[part 6 of 12: package /E40_Platform_System_SystemPackage/Components]
AUTOSAR XML (schema 4-2-1)
package /E40_Platform_System_SystemPackage/Components  (continued)
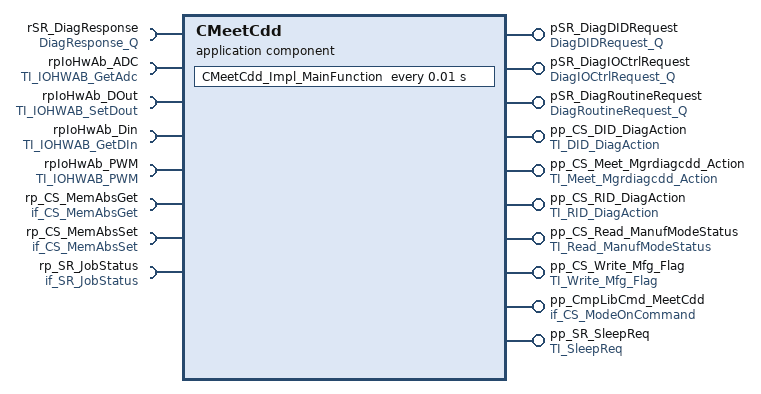
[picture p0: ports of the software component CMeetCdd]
  application sw component type CMeetCdd
    10 x provide port:
      pSR_DiagDIDRequest: queued-sender-com-spec=DiagDIDRequestData, provided-interface=DiagDIDRequest_Q
      pSR_DiagIOCtrlRequest: queued-sender-com-spec=DiagIOCtrlRequestData, provided-interface=DiagIOCtrlRequest_Q
      pSR_DiagRoutineRequest: queued-sender-com-spec=DiagRoutineRequestData, provided-interface=DiagRoutineRequest_Q
      pp_CS_DID_DiagAction: server-com-spec{operation=TI_DID_DiagAction/DID_DiagAction, queue-length=1}, provided-interface=TI_DID_DiagAction
      pp_CS_Meet_Mgrdiagcdd_Action: server-com-spec{operation=Meet_Mgrdiagcdd_Action, queue-length=1}, provided-interface=TI_Meet_Mgrdiagcdd_Action
      pp_CS_RID_DiagAction: server-com-spec{operation=TI_RID_DiagAction/RID_DiagAction, queue-length=1}, provided-interface=TI_RID_DiagAction
      pp_CS_Read_ManufModeStatus: server-com-spec{operation=Read_ManufModeStatus, queue-length=1}, provided-interface=TI_Read_ManufModeStatus
      pp_CS_Write_Mfg_Flag: server-com-spec{operation=Write_Mfg_Flag, queue-length=1}, provided-interface=TI_Write_Mfg_Flag
      pp_CmpLibCmd_MeetCdd: server-com-spec{operation=Impl_OnCommand, queue-length=1}, provided-interface=if_CS_ModeOnCommand
      pp_SR_SleepReq: nonqueued-sender-com-spec{data-element=SleepReqData, uses-end-to-end-protection=0, init-value=constant-reference=CMeetCddSleepReqDataValue0}, provided-interface=TI_SleepReq
    8 x require port:
      rSR_DiagResponse: queued-receiver-com-spec{data-element=DiagResponseData, queue-length=2}, required-interface=DiagResponse_Q
      rpIoHwAb_ADC: required-interface=TI_IOHWAB_GetAdc
      rpIoHwAb_DOut: required-interface=TI_IOHWAB_SetDout
      rpIoHwAb_Din: required-interface=TI_IOHWAB_GetDIn
      rpIoHwAb_PWM: required-interface=TI_IOHWAB_PWM
      rp_CS_MemAbsGet: required-interface=if_CS_MemAbsGet
      rp_CS_MemAbsSet: required-interface=if_CS_MemAbsSet
      rp_SR_JobStatus: required-interface=if_SR_JobStatus
        required-com-specs:
          data-element=JobStatus_BsConst_Audio_Element, init-value=constant-reference=CMeetCddJobStatus_BsConst_Audio_ElementValue0
          data-element=JobStatus_BsConst_BsConst_Illumination_ReservedByte, init-value=constant-reference=CMeetCddJobStatus_BsConst_BsConst_Illumination_ReservedByteValue0
          data-element=JobStatus_BsConst_BsConst_Illumination_ReservedByte_SafeCopy1, init-value=constant-reference=CMeetCddJobStatus_BsConst_BsConst_Illumination_ReservedByte_SafeCopy1Value0
          data-element=JobStatus_BsConst_BsConst_Illumination_ReservedByte_SafeCopy2, init-value=constant-reference=CMeetCddJobStatus_BsConst_BsConst_Illumination_ReservedByte_SafeCopy2Value0
          data-element=JobStatus_BsConst_Communication_Element, init-value=constant-reference=CMeetCddJobStatus_BsConst_Communication_ElementValue0
          data-element=JobStatus_BsConst_Compensation_Line_Shift_b, init-value=constant-reference=CMeetCddJobStatus_BsConst_Compensation_Line_Shift_bValue0
          data-element=JobStatus_BsConst_Compensation_Line_Shift_b_SafeCopy1, init-value=constant-reference=CMeetCddJobStatus_BsConst_Compensation_Line_Shift_b_SafeCopy1Value0
          data-element=JobStatus_BsConst_Compensation_Line_Shift_b_SafeCopy2, init-value=constant-reference=CMeetCddJobStatus_BsConst_Compensation_Line_Shift_b_SafeCopy2Value0
          data-element=JobStatus_BsConst_Compensation_Line_Slope_m, init-value=constant-reference=CMeetCddJobStatus_BsConst_Compensation_Line_Slope_mValue0
          data-element=JobStatus_BsConst_Compensation_Line_Slope_m_SafeCopy1, init-value=constant-reference=CMeetCddJobStatus_BsConst_Compensation_Line_Slope_m_SafeCopy1Value0
          data-element=JobStatus_BsConst_Compensation_Line_Slope_m_SafeCopy2, init-value=constant-reference=CMeetCddJobStatus_BsConst_Compensation_Line_Slope_m_SafeCopy2Value0
          data-element=JobStatus_BsConst_Derating_Backlight_Disable, init-value=constant-reference=CMeetCddJobStatus_BsConst_Derating_Backlight_DisableValue0
          data-element=JobStatus_BsConst_Derating_Backlight_Disable_SafeCopy1, init-value=constant-reference=CMeetCddJobStatus_BsConst_Derating_Backlight_Disable_SafeCopy1Value0
          data-element=JobStatus_BsConst_Derating_Backlight_Disable_SafeCopy2, init-value=constant-reference=CMeetCddJobStatus_BsConst_Derating_Backlight_Disable_SafeCopy2Value0
          data-element=JobStatus_BsConst_Display_Illum_Max_Level, init-value=constant-reference=CMeetCddJobStatus_BsConst_Display_Illum_Max_LevelValue0
          data-element=JobStatus_BsConst_Display_Illum_Max_Level_SafeCopy1, init-value=constant-reference=CMeetCddJobStatus_BsConst_Display_Illum_Max_Level_SafeCopy1Value0
          data-element=JobStatus_BsConst_Display_Illum_Max_Level_SafeCopy2, init-value=constant-reference=CMeetCddJobStatus_BsConst_Display_Illum_Max_Level_SafeCopy2Value0
          data-element=JobStatus_BsConst_EngOffTimer_Element, init-value=constant-reference=CMeetCddJobStatus_BsConst_EngOffTimer_ElementValue0
          data-element=JobStatus_BsConst_FuelGauge_Element, init-value=constant-reference=CMeetCddJobStatus_BsConst_FuelGauge_ElementValue0
          data-element=JobStatus_BsConst_Lookup_Curve_HotSpot_Coef_X, init-value=constant-reference=CMeetCddJobStatus_BsConst_Lookup_Curve_HotSpot_Coef_XValue0
          data-element=JobStatus_BsConst_Lookup_Curve_HotSpot_Coef_X_SafeCopy1, init-value=constant-reference=CMeetCddJobStatus_BsConst_Lookup_Curve_HotSpot_Coef_X_SafeCopy1Value0
          data-element=JobStatus_BsConst_Lookup_Curve_HotSpot_Coef_X_SafeCopy2, init-value=constant-reference=CMeetCddJobStatus_BsConst_Lookup_Curve_HotSpot_Coef_X_SafeCopy2Value0
          data-element=JobStatus_BsConst_Lookup_Curve_HotSpot_Coef_Y, init-value=constant-reference=CMeetCddJobStatus_BsConst_Lookup_Curve_HotSpot_Coef_YValue0
          data-element=JobStatus_BsConst_Lookup_Curve_HotSpot_Coef_Y_SafeCopy1, init-value=constant-reference=CMeetCddJobStatus_BsConst_Lookup_Curve_HotSpot_Coef_Y_SafeCopy1Value0
          data-element=JobStatus_BsConst_Lookup_Curve_HotSpot_Coef_Y_SafeCopy2, init-value=constant-reference=CMeetCddJobStatus_BsConst_Lookup_Curve_HotSpot_Coef_Y_SafeCopy2Value0
          data-element=JobStatus_BsConst_OilGauge_Element, init-value=constant-reference=CMeetCddJobStatus_BsConst_OilGauge_ElementValue0
          data-element=JobStatus_BsConst_PCB_Temperature_Sensor_Conv, init-value=constant-reference=CMeetCddJobStatus_BsConst_PCB_Temperature_Sensor_ConvValue0
          data-element=JobStatus_BsConst_PCB_Temperature_Sensor_Conv_SafeCopy1, init-value=constant-reference=CMeetCddJobStatus_BsConst_PCB_Temperature_Sensor_Conv_SafeCopy1Value0
          data-element=JobStatus_BsConst_PCB_Temperature_Sensor_Conv_SafeCopy2, init-value=constant-reference=CMeetCddJobStatus_BsConst_PCB_Temperature_Sensor_Conv_SafeCopy2Value0
          data-element=JobStatus_BsConst_PWM_boost_bypass_duty, init-value=constant-reference=CMeetCddJobStatus_BsConst_PWM_boost_bypass_dutyValue0
          data-element=JobStatus_BsConst_PWM_boost_bypass_duty_SafeCopy1, init-value=constant-reference=CMeetCddJobStatus_BsConst_PWM_boost_bypass_duty_SafeCopy1Value0
          data-element=JobStatus_BsConst_PWM_boost_bypass_duty_SafeCopy2, init-value=constant-reference=CMeetCddJobStatus_BsConst_PWM_boost_bypass_duty_SafeCopy2Value0
          data-element=JobStatus_BsConst_PowerGauge_Element, init-value=constant-reference=CMeetCddJobStatus_BsConst_PowerGauge_ElementValue0
          data-element=JobStatus_BsConst_Power_Element, init-value=constant-reference=CMeetCddJobStatus_BsConst_Power_ElementValue0
          data-element=JobStatus_BsConst_RealTimeClock_Element, init-value=constant-reference=CMeetCddJobStatus_BsConst_RealTimeClock_ElementValue0
          data-element=JobStatus_BsConst_ServiceReminder_Element, init-value=constant-reference=CMeetCddJobStatus_BsConst_ServiceReminder_ElementValue0
          data-element=JobStatus_BsConst_SpeedoGauge_Element, init-value=constant-reference=CMeetCddJobStatus_BsConst_SpeedoGauge_ElementValue0
          data-element=JobStatus_BsConst_TachoGauge_Element, init-value=constant-reference=CMeetCddJobStatus_BsConst_TachoGauge_ElementValue0
          data-element=JobStatus_BsConst_TempGauge_Element, init-value=constant-reference=CMeetCddJobStatus_BsConst_TempGauge_ElementValue0
          data-element=JobStatus_BsConst_Temp_Threshold_Hysteresis_Derating, init-value=constant-reference=CMeetCddJobStatus_BsConst_Temp_Threshold_Hysteresis_DeratingValue0
          data-element=JobStatus_BsConst_Temp_Threshold_Hysteresis_Derating_SafeCopy1, init-value=constant-reference=CMeetCddJobStatus_BsConst_Temp_Threshold_Hysteresis_Derating_SafeCopy1Value0
          data-element=JobStatus_BsConst_Temp_Threshold_Hysteresis_Derating_SafeCopy2, init-value=constant-reference=CMeetCddJobStatus_BsConst_Temp_Threshold_Hysteresis_Derating_SafeCopy2Value0
          data-element=JobStatus_BsConst_Temperature_Sensor_Conv, init-value=constant-reference=CMeetCddJobStatus_BsConst_Temperature_Sensor_ConvValue0
          data-element=JobStatus_BsConst_Temperature_Sensor_Conv_SafeCopy1, init-value=constant-reference=CMeetCddJobStatus_BsConst_Temperature_Sensor_Conv_SafeCopy1Value0
          data-element=JobStatus_BsConst_Temperature_Sensor_Conv_SafeCopy2, init-value=constant-reference=CMeetCddJobStatus_BsConst_Temperature_Sensor_Conv_SafeCopy2Value0
          data-element=JobStatus_BsConst_TripComputer_Element, init-value=constant-reference=CMeetCddJobStatus_BsConst_TripComputer_ElementValue0
          data-element=JobStatus_BsConst_Warning_Element, init-value=constant-reference=CMeetCddJobStatus_BsConst_Warning_ElementValue0
          data-element=JobStatus_BsCys_Certicificate_Element, init-value=constant-reference=CMeetCddJobStatus_BsCys_Certicificate_ElementValue0
          data-element=JobStatus_BsDiag_Dtc_Element, init-value=constant-reference=CMeetCddJobStatus_BsDiag_Dtc_ElementValue0
          data-element=JobStatus_BsDiag_ErrorRecord_Element, init-value=constant-reference=CMeetCddJobStatus_BsDiag_ErrorRecord_ElementValue0
          data-element=JobStatus_BsReten_Audio_Element, init-value=constant-reference=CMeetCddJobStatus_BsReten_Audio_ElementValue0
          data-element=JobStatus_BsReten_Communication_Element, init-value=constant-reference=CMeetCddJobStatus_BsReten_Communication_ElementValue0
          data-element=JobStatus_BsReten_Display_Element, init-value=constant-reference=CMeetCddJobStatus_BsReten_Display_ElementValue0
          data-element=JobStatus_BsReten_Gauges_Element, init-value=constant-reference=CMeetCddJobStatus_BsReten_Gauges_ElementValue0
          data-element=JobStatus_BsReten_Illumination_Element, init-value=constant-reference=CMeetCddJobStatus_BsReten_Illumination_ElementValue0
          data-element=JobStatus_BsReten_Odometer_Element, init-value=constant-reference=CMeetCddJobStatus_BsReten_Odometer_ElementValue0
          data-element=JobStatus_BsReten_Personalization_Element, init-value=constant-reference=CMeetCddJobStatus_BsReten_Personalization_ElementValue0
          data-element=JobStatus_BsReten_Power_Element, init-value=constant-reference=CMeetCddJobStatus_BsReten_Power_ElementValue0
          data-element=JobStatus_BsReten_RealTimeClock_Element, init-value=constant-reference=CMeetCddJobStatus_BsReten_RealTimeClock_ElementValue0
          data-element=JobStatus_BsReten_Tripcomputer_Element, init-value=constant-reference=CMeetCddJobStatus_BsReten_Tripcomputer_ElementValue0
          data-element=JobStatus_BsReten_Warning_Element, init-value=constant-reference=CMeetCddJobStatus_BsReten_Warning_ElementValue0
          data-element=JobStatus_BsRt_CusDlt_Element, init-value=constant-reference=CMeetCddJobStatus_BsRt_CusDlt_ElementValue0
          data-element=JobStatus_BsRt_FuelGauge_Element, init-value=constant-reference=CMeetCddJobStatus_BsRt_FuelGauge_ElementValue0
          data-element=JobStatus_BsRt_Illumination_Element, init-value=constant-reference=CMeetCddJobStatus_BsRt_Illumination_ElementValue0
          data-element=JobStatus_BsRt_Odometer_Element, init-value=constant-reference=CMeetCddJobStatus_BsRt_Odometer_ElementValue0
          data-element=JobStatus_BsRt_OilGauge_Element, init-value=constant-reference=CMeetCddJobStatus_BsRt_OilGauge_ElementValue0
          data-element=JobStatus_BsRt_Personalization_Element, init-value=constant-reference=CMeetCddJobStatus_BsRt_Personalization_ElementValue0
          data-element=JobStatus_BsRt_PowerGauge_Element, init-value=constant-reference=CMeetCddJobStatus_BsRt_PowerGauge_ElementValue0
          data-element=JobStatus_BsRt_RealTimeClock_Element, init-value=constant-reference=CMeetCddJobStatus_BsRt_RealTimeClock_ElementValue0
          data-element=JobStatus_BsRt_SpeedoGauge_Element, init-value=constant-reference=CMeetCddJobStatus_BsRt_SpeedoGauge_ElementValue0
          data-element=JobStatus_BsRt_TachoGauge_Element, init-value=constant-reference=CMeetCddJobStatus_BsRt_TachoGauge_ElementValue0
          data-element=JobStatus_BsRt_TempGauge_Element, init-value=constant-reference=CMeetCddJobStatus_BsRt_TempGauge_ElementValue0
          data-element=JobStatus_BsRt_TripComputer_Element, init-value=constant-reference=CMeetCddJobStatus_BsRt_TripComputer_ElementValue0
          data-element=JobStatus_BsRt_Warning_Element, init-value=constant-reference=CMeetCddJobStatus_BsRt_Warning_ElementValue0
          data-element=JobStatus_BsShare_AssemblyManufacturingDate, init-value=constant-reference=CMeetCddJobStatus_BsShare_AssemblyManufacturingDateValue0
          data-element=JobStatus_BsShare_AssemblyPlantNumber, init-value=constant-reference=CMeetCddJobStatus_BsShare_AssemblyPlantNumberValue0
          data-element=JobStatus_BsShare_EcuPartNumber_Element, init-value=constant-reference=CMeetCddJobStatus_BsShare_EcuPartNumber_ElementValue0
          data-element=JobStatus_BsShare_HWModification, init-value=constant-reference=CMeetCddJobStatus_BsShare_HWModificationValue0
          data-element=JobStatus_BsShare_PCBSerialNumber, init-value=constant-reference=CMeetCddJobStatus_BsShare_PCBSerialNumberValue0
          data-element=JobStatus_BsShare_ProductSerialNumber, init-value=constant-reference=CMeetCddJobStatus_BsShare_ProductSerialNumberValue0
          data-element=JobStatus_BsShare_SMTManufacturingDate, init-value=constant-reference=CMeetCddJobStatus_BsShare_SMTManufacturingDateValue0
          data-element=JobStatus_BsShare_SMTPlantNumber, init-value=constant-reference=CMeetCddJobStatus_BsShare_SMTPlantNumberValue0
          data-element=JobStatus_BsShare_SwUpdFotaFinPrint_Element, init-value=constant-reference=CMeetCddJobStatus_BsShare_SwUpdFotaFinPrint_ElementValue0
          data-element=JobStatus_BsShare_SwUpdFotaMode_Element, init-value=constant-reference=CMeetCddJobStatus_BsShare_SwUpdFotaMode_ElementValue0
          data-element=JobStatus_BsShare_SwUpdFotaStatus_Element, init-value=constant-reference=CMeetCddJobStatus_BsShare_SwUpdFotaStatus_ElementValue0
          data-element=JobStatus_BsShare_SwUpdFotadecrypt_Element, init-value=constant-reference=CMeetCddJobStatus_BsShare_SwUpdFotadecrypt_ElementValue0
          data-element=JobStatus_BsShare_SwUpdReflash_Element, init-value=constant-reference=CMeetCddJobStatus_BsShare_SwUpdReflash_ElementValue0
          data-element=JobStatus_BsShare_VehicleConfig_Element, init-value=constant-reference=CMeetCddJobStatus_BsShare_VehicleConfig_ElementValue0
          data-element=JobStatus_BsShare_VisMeet_EOLEntry_Element, init-value=constant-reference=CMeetCddJobStatus_BsShare_VisMeet_EOLEntry_ElementValue0
          data-element=JobStatus_BsShare_VisMeet_Element, init-value=constant-reference=CMeetCddJobStatus_BsShare_VisMeet_ElementValue0
          data-element=JobStatus_BsShare_VisteonPCBPartNumber, init-value=constant-reference=CMeetCddJobStatus_BsShare_VisteonPCBPartNumberValue0
          data-element=JobStatus_BsShare_VisteonPartNumber, init-value=constant-reference=CMeetCddJobStatus_BsShare_VisteonPartNumberValue0
          data-element=JobStatus_RefCys_Certicificate1_Element, init-value=constant-reference=CMeetCddJobStatus_RefCys_Certicificate1_ElementValue0
          data-element=JobStatus_RefCys_Certicificate_Element, init-value=constant-reference=CMeetCddJobStatus_RefCys_Certicificate_ElementValue0
    behavior IB_CMeetCdd
      operation invoked event OIE_pp_CS_DID_DiagAction_CMeetCdd_DID_DiagActionTrigByDID_DiagAction: start-on-event=CMeetCdd_DID_DiagAction, operation=pp_CS_DID_DiagAction.DID_DiagAction
      timing event TECMeetCdd_Impl_MainFunction: start-on-event=CMeetCdd_Impl_MainFunction, period=0.01
      5 x operation invoked event:
        OIE_pp_CmpLibCmd_MeetCdd_CMeetCdd_Impl_OnCommandTrigByImpl_OnCommand: start-on-event=CMeetCdd_Impl_OnCommand, operation=pp_CmpLibCmd_MeetCdd.Impl_OnCommand
        OIE_pp_CS_Meet_Mgrdiagcdd_Action_CMeetCdd_Meet_Mgrdiagcdd_ActionTrigByMeet_Mgrdiagcdd_Action: start-on-event=CMeetCdd_Meet_Mgrdiagcdd_Action, operation=pp_CS_Meet_Mgrdiagcdd_Action.Meet_Mgrdiagcdd_Action
        OIE_pp_CS_RID_DiagAction_CMeetCdd_RID_DiagActionTrigByRID_DiagAction: start-on-event=CMeetCdd_RID_DiagAction, operation=pp_CS_RID_DiagAction.RID_DiagAction
        OIE_pp_CS_Read_ManufModeStatus_CMeetCdd_Read_ManufModeStatusTrigByRead_ManufModeStatus: start-on-event=CMeetCdd_Read_ManufModeStatus, operation=pp_CS_Read_ManufModeStatus.Read_ManufModeStatus
        OIE_pp_CS_Write_Mfg_Flag_CMeetCdd_Write_Mfg_FlagTrigByWrite_Mfg_Flag: start-on-event=CMeetCdd_Write_Mfg_Flag, operation=pp_CS_Write_Mfg_Flag.Write_Mfg_Flag
      port-api-options:
        enable-take-address=false, indirect-api=false, port=pSR_DiagDIDRequest
        enable-take-address=false, indirect-api=false, port=pSR_DiagIOCtrlRequest
        enable-take-address=false, indirect-api=false, port=pSR_DiagRoutineRequest
        enable-take-address=false, indirect-api=false, port=pp_CS_DID_DiagAction
        enable-take-address=false, indirect-api=false, port=pp_CS_Meet_Mgrdiagcdd_Action
        enable-take-address=false, indirect-api=false, port=pp_CS_RID_DiagAction
        enable-take-address=false, indirect-api=false, port=pp_CS_Read_ManufModeStatus
        enable-take-address=false, indirect-api=false, port=pp_CS_Write_Mfg_Flag
        enable-take-address=false, indirect-api=false, port=pp_CmpLibCmd_MeetCdd
        enable-take-address=false, indirect-api=false, port=pp_SR_SleepReq
        enable-take-address=false, indirect-api=false, port=rSR_DiagResponse
        enable-take-address=false, indirect-api=false, port=CMeetCdd/rpIoHwAb_ADC
        enable-take-address=false, indirect-api=false, port=CMeetCdd/rpIoHwAb_DOut
        enable-take-address=false, indirect-api=false, port=CMeetCdd/rpIoHwAb_Din
        enable-take-address=false, indirect-api=false, port=CMeetCdd/rpIoHwAb_PWM
        enable-take-address=false, indirect-api=false, port=CMeetCdd/rp_CS_MemAbsGet
        enable-take-address=false, indirect-api=false, port=CMeetCdd/rp_CS_MemAbsSet
        enable-take-address=false, indirect-api=false, port=CMeetCdd/rp_SR_JobStatus
      7 x runnable, all with can-be-invoked-concurrently=true:
        CMeetCdd_DID_DiagAction
        CMeetCdd_Impl_MainFunction
          data-receive-point-by-arguments:
            95 x access:
              DRP_rSR_DiagResponse_DiagResponseData: accessed-variable=rSR_DiagResponse.DiagResponseData
              DRA_rp_SR_JobStatus_JobStatus_BsConst_Audio_Element: accessed-variable=rp_SR_JobStatus.JobStatus_BsConst_Audio_Element
              DRA_rp_SR_JobStatus_JobStatus_BsConst_BsConst_Illumination_ReservedByte: accessed-variable=rp_SR_JobStatus.JobStatus_BsConst_BsConst_Illumination_ReservedByte
              DRA_rp_SR_JobStatus_JobStatus_BsConst_BsConst_Illumination_ReservedByte_SafeCopy1: accessed-variable=rp_SR_JobStatus.JobStatus_BsConst_BsConst_Illumination_ReservedByte_SafeCopy1
              DRA_rp_SR_JobStatus_JobStatus_BsConst_BsConst_Illumination_ReservedByte_SafeCopy2: accessed-variable=rp_SR_JobStatus.JobStatus_BsConst_BsConst_Illumination_ReservedByte_SafeCopy2
              DRA_rp_SR_JobStatus_JobStatus_BsConst_Communication_Element: accessed-variable=rp_SR_JobStatus.JobStatus_BsConst_Communication_Element
              DRA_rp_SR_JobStatus_JobStatus_BsConst_Compensation_Line_Shift_b: accessed-variable=rp_SR_JobStatus.JobStatus_BsConst_Compensation_Line_Shift_b
              DRA_rp_SR_JobStatus_JobStatus_BsConst_Compensation_Line_Shift_b_SafeCopy1: accessed-variable=rp_SR_JobStatus.JobStatus_BsConst_Compensation_Line_Shift_b_SafeCopy1
              DRA_rp_SR_JobStatus_JobStatus_BsConst_Compensation_Line_Shift_b_SafeCopy2: accessed-variable=rp_SR_JobStatus.JobStatus_BsConst_Compensation_Line_Shift_b_SafeCopy2
              DRA_rp_SR_JobStatus_JobStatus_BsConst_Compensation_Line_Slope_m: accessed-variable=rp_SR_JobStatus.JobStatus_BsConst_Compensation_Line_Slope_m
              DRA_rp_SR_JobStatus_JobStatus_BsConst_Compensation_Line_Slope_m_SafeCopy1: accessed-variable=rp_SR_JobStatus.JobStatus_BsConst_Compensation_Line_Slope_m_SafeCopy1
              DRA_rp_SR_JobStatus_JobStatus_BsConst_Compensation_Line_Slope_m_SafeCopy2: accessed-variable=rp_SR_JobStatus.JobStatus_BsConst_Compensation_Line_Slope_m_SafeCopy2
              DRA_rp_SR_JobStatus_JobStatus_BsConst_Derating_Backlight_Disable: accessed-variable=rp_SR_JobStatus.JobStatus_BsConst_Derating_Backlight_Disable
              DRA_rp_SR_JobStatus_JobStatus_BsConst_Derating_Backlight_Disable_SafeCopy1: accessed-variable=rp_SR_JobStatus.JobStatus_BsConst_Derating_Backlight_Disable_SafeCopy1
              DRA_rp_SR_JobStatus_JobStatus_BsConst_Derating_Backlight_Disable_SafeCopy2: accessed-variable=rp_SR_JobStatus.JobStatus_BsConst_Derating_Backlight_Disable_SafeCopy2
              DRA_rp_SR_JobStatus_JobStatus_BsConst_Display_Illum_Max_Level: accessed-variable=rp_SR_JobStatus.JobStatus_BsConst_Display_Illum_Max_Level
              DRA_rp_SR_JobStatus_JobStatus_BsConst_Display_Illum_Max_Level_SafeCopy1: accessed-variable=rp_SR_JobStatus.JobStatus_BsConst_Display_Illum_Max_Level_SafeCopy1
              DRA_rp_SR_JobStatus_JobStatus_BsConst_Display_Illum_Max_Level_SafeCopy2: accessed-variable=rp_SR_JobStatus.JobStatus_BsConst_Display_Illum_Max_Level_SafeCopy2
              DRA_rp_SR_JobStatus_JobStatus_BsConst_EngOffTimer_Element: accessed-variable=rp_SR_JobStatus.JobStatus_BsConst_EngOffTimer_Element
              DRA_rp_SR_JobStatus_JobStatus_BsConst_FuelGauge_Element: accessed-variable=rp_SR_JobStatus.JobStatus_BsConst_FuelGauge_Element
              DRA_rp_SR_JobStatus_JobStatus_BsConst_Lookup_Curve_HotSpot_Coef_X: accessed-variable=rp_SR_JobStatus.JobStatus_BsConst_Lookup_Curve_HotSpot_Coef_X
              DRA_rp_SR_JobStatus_JobStatus_BsConst_Lookup_Curve_HotSpot_Coef_X_SafeCopy1: accessed-variable=rp_SR_JobStatus.JobStatus_BsConst_Lookup_Curve_HotSpot_Coef_X_SafeCopy1
              DRA_rp_SR_JobStatus_JobStatus_BsConst_Lookup_Curve_HotSpot_Coef_X_SafeCopy2: accessed-variable=rp_SR_JobStatus.JobStatus_BsConst_Lookup_Curve_HotSpot_Coef_X_SafeCopy2
              DRA_rp_SR_JobStatus_JobStatus_BsConst_Lookup_Curve_HotSpot_Coef_Y: accessed-variable=rp_SR_JobStatus.JobStatus_BsConst_Lookup_Curve_HotSpot_Coef_Y
              DRA_rp_SR_JobStatus_JobStatus_BsConst_Lookup_Curve_HotSpot_Coef_Y_SafeCopy1: accessed-variable=rp_SR_JobStatus.JobStatus_BsConst_Lookup_Curve_HotSpot_Coef_Y_SafeCopy1
              DRA_rp_SR_JobStatus_JobStatus_BsConst_Lookup_Curve_HotSpot_Coef_Y_SafeCopy2: accessed-variable=rp_SR_JobStatus.JobStatus_BsConst_Lookup_Curve_HotSpot_Coef_Y_SafeCopy2
              DRA_rp_SR_JobStatus_JobStatus_BsConst_OilGauge_Element: accessed-variable=rp_SR_JobStatus.JobStatus_BsConst_OilGauge_Element
              DRA_rp_SR_JobStatus_JobStatus_BsConst_PCB_Temperature_Sensor_Conv: accessed-variable=rp_SR_JobStatus.JobStatus_BsConst_PCB_Temperature_Sensor_Conv
              DRA_rp_SR_JobStatus_JobStatus_BsConst_PCB_Temperature_Sensor_Conv_SafeCopy1: accessed-variable=rp_SR_JobStatus.JobStatus_BsConst_PCB_Temperature_Sensor_Conv_SafeCopy1
              DRA_rp_SR_JobStatus_JobStatus_BsConst_PCB_Temperature_Sensor_Conv_SafeCopy2: accessed-variable=rp_SR_JobStatus.JobStatus_BsConst_PCB_Temperature_Sensor_Conv_SafeCopy2
              DRA_rp_SR_JobStatus_JobStatus_BsConst_PWM_boost_bypass_duty: accessed-variable=rp_SR_JobStatus.JobStatus_BsConst_PWM_boost_bypass_duty
              DRA_rp_SR_JobStatus_JobStatus_BsConst_PWM_boost_bypass_duty_SafeCopy1: accessed-variable=rp_SR_JobStatus.JobStatus_BsConst_PWM_boost_bypass_duty_SafeCopy1
              DRA_rp_SR_JobStatus_JobStatus_BsConst_PWM_boost_bypass_duty_SafeCopy2: accessed-variable=rp_SR_JobStatus.JobStatus_BsConst_PWM_boost_bypass_duty_SafeCopy2
              DRA_rp_SR_JobStatus_JobStatus_BsConst_PowerGauge_Element: accessed-variable=rp_SR_JobStatus.JobStatus_BsConst_PowerGauge_Element
              DRA_rp_SR_JobStatus_JobStatus_BsConst_Power_Element: accessed-variable=rp_SR_JobStatus.JobStatus_BsConst_Power_Element
              DRA_rp_SR_JobStatus_JobStatus_BsConst_RealTimeClock_Element: accessed-variable=rp_SR_JobStatus.JobStatus_BsConst_RealTimeClock_Element
              DRA_rp_SR_JobStatus_JobStatus_BsConst_ServiceReminder_Element: accessed-variable=rp_SR_JobStatus.JobStatus_BsConst_ServiceReminder_Element
              DRA_rp_SR_JobStatus_JobStatus_BsConst_SpeedoGauge_Element: accessed-variable=rp_SR_JobStatus.JobStatus_BsConst_SpeedoGauge_Element
              DRA_rp_SR_JobStatus_JobStatus_BsConst_TachoGauge_Element: accessed-variable=rp_SR_JobStatus.JobStatus_BsConst_TachoGauge_Element
              DRA_rp_SR_JobStatus_JobStatus_BsConst_TempGauge_Element: accessed-variable=rp_SR_JobStatus.JobStatus_BsConst_TempGauge_Element
              DRA_rp_SR_JobStatus_JobStatus_BsConst_Temp_Threshold_Hysteresis_Derating: accessed-variable=rp_SR_JobStatus.JobStatus_BsConst_Temp_Threshold_Hysteresis_Derating
              DRA_rp_SR_JobStatus_JobStatus_BsConst_Temp_Threshold_Hysteresis_Derating_SafeCopy1: accessed-variable=rp_SR_JobStatus.JobStatus_BsConst_Temp_Threshold_Hysteresis_Derating_SafeCopy1
              DRA_rp_SR_JobStatus_JobStatus_BsConst_Temp_Threshold_Hysteresis_Derating_SafeCopy2: accessed-variable=rp_SR_JobStatus.JobStatus_BsConst_Temp_Threshold_Hysteresis_Derating_SafeCopy2
              DRA_rp_SR_JobStatus_JobStatus_BsConst_Temperature_Sensor_Conv: accessed-variable=rp_SR_JobStatus.JobStatus_BsConst_Temperature_Sensor_Conv
              DRA_rp_SR_JobStatus_JobStatus_BsConst_Temperature_Sensor_Conv_SafeCopy1: accessed-variable=rp_SR_JobStatus.JobStatus_BsConst_Temperature_Sensor_Conv_SafeCopy1
              DRA_rp_SR_JobStatus_JobStatus_BsConst_Temperature_Sensor_Conv_SafeCopy2: accessed-variable=rp_SR_JobStatus.JobStatus_BsConst_Temperature_Sensor_Conv_SafeCopy2
              DRA_rp_SR_JobStatus_JobStatus_BsConst_TripComputer_Element: accessed-variable=rp_SR_JobStatus.JobStatus_BsConst_TripComputer_Element
              DRA_rp_SR_JobStatus_JobStatus_BsConst_Warning_Element: accessed-variable=rp_SR_JobStatus.JobStatus_BsConst_Warning_Element
              DRA_rp_SR_JobStatus_JobStatus_BsCys_Certicificate_Element: accessed-variable=rp_SR_JobStatus.JobStatus_BsCys_Certicificate_Element
              DRA_rp_SR_JobStatus_JobStatus_BsDiag_Dtc_Element: accessed-variable=rp_SR_JobStatus.JobStatus_BsDiag_Dtc_Element
              DRA_rp_SR_JobStatus_JobStatus_BsDiag_ErrorRecord_Element: accessed-variable=rp_SR_JobStatus.JobStatus_BsDiag_ErrorRecord_Element
              DRA_rp_SR_JobStatus_JobStatus_BsReten_Audio_Element: accessed-variable=rp_SR_JobStatus.JobStatus_BsReten_Audio_Element
              DRA_rp_SR_JobStatus_JobStatus_BsReten_Communication_Element: accessed-variable=rp_SR_JobStatus.JobStatus_BsReten_Communication_Element
              DRA_rp_SR_JobStatus_JobStatus_BsReten_Display_Element: accessed-variable=rp_SR_JobStatus.JobStatus_BsReten_Display_Element
              DRA_rp_SR_JobStatus_JobStatus_BsReten_Gauges_Element: accessed-variable=rp_SR_JobStatus.JobStatus_BsReten_Gauges_Element
              DRA_rp_SR_JobStatus_JobStatus_BsReten_Illumination_Element: accessed-variable=rp_SR_JobStatus.JobStatus_BsReten_Illumination_Element
              DRA_rp_SR_JobStatus_JobStatus_BsReten_Odometer_Element: accessed-variable=rp_SR_JobStatus.JobStatus_BsReten_Odometer_Element
              DRA_rp_SR_JobStatus_JobStatus_BsReten_Personalization_Element: accessed-variable=rp_SR_JobStatus.JobStatus_BsReten_Personalization_Element
              DRA_rp_SR_JobStatus_JobStatus_BsReten_Power_Element: accessed-variable=rp_SR_JobStatus.JobStatus_BsReten_Power_Element
              DRA_rp_SR_JobStatus_JobStatus_BsReten_RealTimeClock_Element: accessed-variable=rp_SR_JobStatus.JobStatus_BsReten_RealTimeClock_Element
              DRA_rp_SR_JobStatus_JobStatus_BsReten_Tripcomputer_Element: accessed-variable=rp_SR_JobStatus.JobStatus_BsReten_Tripcomputer_Element
              DRA_rp_SR_JobStatus_JobStatus_BsReten_Warning_Element: accessed-variable=rp_SR_JobStatus.JobStatus_BsReten_Warning_Element
              DRA_rp_SR_JobStatus_JobStatus_BsRt_CusDlt_Element: accessed-variable=rp_SR_JobStatus.JobStatus_BsRt_CusDlt_Element
              DRA_rp_SR_JobStatus_JobStatus_BsRt_FuelGauge_Element: accessed-variable=rp_SR_JobStatus.JobStatus_BsRt_FuelGauge_Element
              DRA_rp_SR_JobStatus_JobStatus_BsRt_Illumination_Element: accessed-variable=rp_SR_JobStatus.JobStatus_BsRt_Illumination_Element
              DRA_rp_SR_JobStatus_JobStatus_BsRt_Odometer_Element: accessed-variable=rp_SR_JobStatus.JobStatus_BsRt_Odometer_Element
              DRA_rp_SR_JobStatus_JobStatus_BsRt_OilGauge_Element: accessed-variable=rp_SR_JobStatus.JobStatus_BsRt_OilGauge_Element
              DRA_rp_SR_JobStatus_JobStatus_BsRt_Personalization_Element: accessed-variable=rp_SR_JobStatus.JobStatus_BsRt_Personalization_Element
              DRA_rp_SR_JobStatus_JobStatus_BsRt_PowerGauge_Element: accessed-variable=rp_SR_JobStatus.JobStatus_BsRt_PowerGauge_Element
              DRA_rp_SR_JobStatus_JobStatus_BsRt_RealTimeClock_Element: accessed-variable=rp_SR_JobStatus.JobStatus_BsRt_RealTimeClock_Element
              DRA_rp_SR_JobStatus_JobStatus_BsRt_SpeedoGauge_Element: accessed-variable=rp_SR_JobStatus.JobStatus_BsRt_SpeedoGauge_Element
              DRA_rp_SR_JobStatus_JobStatus_BsRt_TachoGauge_Element: accessed-variable=rp_SR_JobStatus.JobStatus_BsRt_TachoGauge_Element
              DRA_rp_SR_JobStatus_JobStatus_BsRt_TempGauge_Element: accessed-variable=rp_SR_JobStatus.JobStatus_BsRt_TempGauge_Element
              DRA_rp_SR_JobStatus_JobStatus_BsRt_TripComputer_Element: accessed-variable=rp_SR_JobStatus.JobStatus_BsRt_TripComputer_Element
              DRA_rp_SR_JobStatus_JobStatus_BsRt_Warning_Element: accessed-variable=rp_SR_JobStatus.JobStatus_BsRt_Warning_Element
              DRA_rp_SR_JobStatus_JobStatus_BsShare_AssemblyManufacturingDate: accessed-variable=rp_SR_JobStatus.JobStatus_BsShare_AssemblyManufacturingDate
              DRA_rp_SR_JobStatus_JobStatus_BsShare_AssemblyPlantNumber: accessed-variable=rp_SR_JobStatus.JobStatus_BsShare_AssemblyPlantNumber
              DRA_rp_SR_JobStatus_JobStatus_BsShare_EcuPartNumber_Element: accessed-variable=rp_SR_JobStatus.JobStatus_BsShare_EcuPartNumber_Element
              DRA_rp_SR_JobStatus_JobStatus_BsShare_HWModification: accessed-variable=rp_SR_JobStatus.JobStatus_BsShare_HWModification
              DRA_rp_SR_JobStatus_JobStatus_BsShare_PCBSerialNumber: accessed-variable=rp_SR_JobStatus.JobStatus_BsShare_PCBSerialNumber
              DRA_rp_SR_JobStatus_JobStatus_BsShare_ProductSerialNumber: accessed-variable=rp_SR_JobStatus.JobStatus_BsShare_ProductSerialNumber
              DRA_rp_SR_JobStatus_JobStatus_BsShare_SMTManufacturingDate: accessed-variable=rp_SR_JobStatus.JobStatus_BsShare_SMTManufacturingDate
              DRA_rp_SR_JobStatus_JobStatus_BsShare_SMTPlantNumber: accessed-variable=rp_SR_JobStatus.JobStatus_BsShare_SMTPlantNumber
              DRA_rp_SR_JobStatus_JobStatus_BsShare_SwUpdFotaFinPrint_Element: accessed-variable=rp_SR_JobStatus.JobStatus_BsShare_SwUpdFotaFinPrint_Element
              DRA_rp_SR_JobStatus_JobStatus_BsShare_SwUpdFotaMode_Element: accessed-variable=rp_SR_JobStatus.JobStatus_BsShare_SwUpdFotaMode_Element
              DRA_rp_SR_JobStatus_JobStatus_BsShare_SwUpdFotaStatus_Element: accessed-variable=rp_SR_JobStatus.JobStatus_BsShare_SwUpdFotaStatus_Element
              DRA_rp_SR_JobStatus_JobStatus_BsShare_SwUpdFotadecrypt_Element: accessed-variable=rp_SR_JobStatus.JobStatus_BsShare_SwUpdFotadecrypt_Element
              DRA_rp_SR_JobStatus_JobStatus_BsShare_SwUpdReflash_Element: accessed-variable=rp_SR_JobStatus.JobStatus_BsShare_SwUpdReflash_Element
              DRA_rp_SR_JobStatus_JobStatus_BsShare_VehicleConfig_Element: accessed-variable=rp_SR_JobStatus.JobStatus_BsShare_VehicleConfig_Element
              DRA_rp_SR_JobStatus_JobStatus_BsShare_VisMeet_EOLEntry_Element: accessed-variable=rp_SR_JobStatus.JobStatus_BsShare_VisMeet_EOLEntry_Element
              DRA_rp_SR_JobStatus_JobStatus_BsShare_VisMeet_Element: accessed-variable=rp_SR_JobStatus.JobStatus_BsShare_VisMeet_Element
              DRA_rp_SR_JobStatus_JobStatus_BsShare_VisteonPCBPartNumber: accessed-variable=rp_SR_JobStatus.JobStatus_BsShare_VisteonPCBPartNumber
              DRA_rp_SR_JobStatus_JobStatus_BsShare_VisteonPartNumber: accessed-variable=rp_SR_JobStatus.JobStatus_BsShare_VisteonPartNumber
              DRA_rp_SR_JobStatus_JobStatus_RefCys_Certicificate1_Element: accessed-variable=rp_SR_JobStatus.JobStatus_RefCys_Certicificate1_Element
              DRA_rp_SR_JobStatus_JobStatus_RefCys_Certicificate_Element: accessed-variable=rp_SR_JobStatus.JobStatus_RefCys_Certicificate_Element
          data-send-points:
            4 x access:
              DSP_pSR_DiagDIDRequest_DiagDIDRequestData: accessed-variable=pSR_DiagDIDRequest.DiagDIDRequestData
              DSP_pSR_DiagIOCtrlRequest_DiagIOCtrlRequestData: accessed-variable=pSR_DiagIOCtrlRequest.DiagIOCtrlRequestData
              DSP_pSR_DiagRoutineRequest_DiagRoutineRequestData: accessed-variable=pSR_DiagRoutineRequest.DiagRoutineRequestData
              DWA_pp_SR_SleepReq_SleepReqData: accessed-variable=pp_SR_SleepReq.SleepReqData
          200 x sync call, all with timeout=0.0:
            OA_rpIoHwAb_ADC_GetAsyncRawAdc: operation=rpIoHwAb_ADC.GetAsyncRawAdc
            OA_rpIoHwAb_ADC_GetSyncRawAdc: operation=rpIoHwAb_ADC.GetSyncRawAdc
            OA_rpIoHwAb_ADC_GetProcessedAdc: operation=rpIoHwAb_ADC.GetProcessedAdc
            OA_rpIoHwAb_DOut_SetOutputGroup: operation=rpIoHwAb_DOut.SetOutputGroup
            OA_rpIoHwAb_DOut_SetOutputPin: operation=rpIoHwAb_DOut.SetOutputPin
            OA_rpIoHwAb_Din_GetAsyncRawInput: operation=rpIoHwAb_Din.GetAsyncRawInput
            OA_rpIoHwAb_Din_GetProcessedInput: operation=rpIoHwAb_Din.GetProcessedInput
            OA_rpIoHwAb_Din_GetSyncRawInput: operation=rpIoHwAb_Din.GetSyncRawInput
            OA_rpIoHwAb_Din_GetInputGroup: operation=rpIoHwAb_Din.GetInputGroup
            OA_rpIoHwAb_PWM_PwmSetDuty: operation=rpIoHwAb_PWM.PwmSetDuty
            OA_rpIoHwAb_PWM_PwmSetDutyAndPeriod: operation=rpIoHwAb_PWM.PwmSetDutyAndPeriod
            OA_rpIoHwAb_PWM_PwmSetIdeal: operation=rpIoHwAb_PWM.PwmSetIdeal
            OA_rp_CS_MemAbsGet_Get_BsShare_SwUpdReflash_Element: operation=rp_CS_MemAbsGet.Get_BsShare_SwUpdReflash_Element
            OA_rp_CS_MemAbsGet_Get_BsShare_SwUpdFotaMode_Element: operation=rp_CS_MemAbsGet.Get_BsShare_SwUpdFotaMode_Element
            OA_rp_CS_MemAbsGet_Get_BsShare_SwUpdFotaFinPrint_Element: operation=rp_CS_MemAbsGet.Get_BsShare_SwUpdFotaFinPrint_Element
            OA_rp_CS_MemAbsGet_Get_BsShare_SwUpdFotaStatus_Element: operation=rp_CS_MemAbsGet.Get_BsShare_SwUpdFotaStatus_Element
            OA_rp_CS_MemAbsGet_Get_BsShare_SwUpdFotadecrypt_Element: operation=rp_CS_MemAbsGet.Get_BsShare_SwUpdFotadecrypt_Element
            OA_rp_CS_MemAbsGet_Get_BsShare_EcuPartNumber_Element: operation=rp_CS_MemAbsGet.Get_BsShare_EcuPartNumber_Element
            OA_rp_CS_MemAbsGet_Get_BsShare_VisteonPartNumber: operation=rp_CS_MemAbsGet.Get_BsShare_VisteonPartNumber
            OA_rp_CS_MemAbsGet_Get_BsShare_VisteonPCBPartNumber: operation=rp_CS_MemAbsGet.Get_BsShare_VisteonPCBPartNumber
            OA_rp_CS_MemAbsGet_Get_BsShare_ProductSerialNumber: operation=rp_CS_MemAbsGet.Get_BsShare_ProductSerialNumber
            OA_rp_CS_MemAbsGet_Get_BsShare_PCBSerialNumber: operation=rp_CS_MemAbsGet.Get_BsShare_PCBSerialNumber
            OA_rp_CS_MemAbsGet_Get_BsShare_SMTManufacturingDate: operation=rp_CS_MemAbsGet.Get_BsShare_SMTManufacturingDate
            OA_rp_CS_MemAbsGet_Get_BsShare_AssemblyManufacturingDate: operation=rp_CS_MemAbsGet.Get_BsShare_AssemblyManufacturingDate
            OA_rp_CS_MemAbsGet_Get_BsShare_SMTPlantNumber: operation=rp_CS_MemAbsGet.Get_BsShare_SMTPlantNumber
            OA_rp_CS_MemAbsGet_Get_BsShare_AssemblyPlantNumber: operation=rp_CS_MemAbsGet.Get_BsShare_AssemblyPlantNumber
            OA_rp_CS_MemAbsGet_Get_BsShare_HWModification: operation=rp_CS_MemAbsGet.Get_BsShare_HWModification
            OA_rp_CS_MemAbsGet_Get_BsShare_VisMeet_Element: operation=rp_CS_MemAbsGet.Get_BsShare_VisMeet_Element
            OA_rp_CS_MemAbsGet_Get_BsShare_VisMeet_EOLEntry_Element: operation=rp_CS_MemAbsGet.Get_BsShare_VisMeet_EOLEntry_Element
            OA_rp_CS_MemAbsGet_Get_BsShare_VehicleConfig_Element: operation=rp_CS_MemAbsGet.Get_BsShare_VehicleConfig_Element
            OA_rp_CS_MemAbsGet_Get_BsConst_SpeedoGauge_Element: operation=rp_CS_MemAbsGet.Get_BsConst_SpeedoGauge_Element
            OA_rp_CS_MemAbsGet_Get_BsConst_TachoGauge_Element: operation=rp_CS_MemAbsGet.Get_BsConst_TachoGauge_Element
            OA_rp_CS_MemAbsGet_Get_BsConst_FuelGauge_Element: operation=rp_CS_MemAbsGet.Get_BsConst_FuelGauge_Element
            OA_rp_CS_MemAbsGet_Get_BsConst_TempGauge_Element: operation=rp_CS_MemAbsGet.Get_BsConst_TempGauge_Element
            OA_rp_CS_MemAbsGet_Get_BsConst_PowerGauge_Element: operation=rp_CS_MemAbsGet.Get_BsConst_PowerGauge_Element
            OA_rp_CS_MemAbsGet_Get_BsConst_OilGauge_Element: operation=rp_CS_MemAbsGet.Get_BsConst_OilGauge_Element
            OA_rp_CS_MemAbsGet_Get_BsConst_TripComputer_Element: operation=rp_CS_MemAbsGet.Get_BsConst_TripComputer_Element
            OA_rp_CS_MemAbsGet_Get_BsConst_Compensation_Line_Slope_m: operation=rp_CS_MemAbsGet.Get_BsConst_Compensation_Line_Slope_m
            OA_rp_CS_MemAbsGet_Get_BsConst_Compensation_Line_Shift_b: operation=rp_CS_MemAbsGet.Get_BsConst_Compensation_Line_Shift_b
            OA_rp_CS_MemAbsGet_Get_BsConst_Lookup_Curve_HotSpot_Coef_X: operation=rp_CS_MemAbsGet.Get_BsConst_Lookup_Curve_HotSpot_Coef_X
            OA_rp_CS_MemAbsGet_Get_BsConst_Lookup_Curve_HotSpot_Coef_Y: operation=rp_CS_MemAbsGet.Get_BsConst_Lookup_Curve_HotSpot_Coef_Y
            OA_rp_CS_MemAbsGet_Get_BsConst_Temp_Threshold_Hysteresis_Derating: operation=rp_CS_MemAbsGet.Get_BsConst_Temp_Threshold_Hysteresis_Derating
            OA_rp_CS_MemAbsGet_Get_BsConst_Derating_Backlight_Disable: operation=rp_CS_MemAbsGet.Get_BsConst_Derating_Backlight_Disable
            OA_rp_CS_MemAbsGet_Get_BsConst_Temperature_Sensor_Conv: operation=rp_CS_MemAbsGet.Get_BsConst_Temperature_Sensor_Conv
            OA_rp_CS_MemAbsGet_Get_BsConst_PCB_Temperature_Sensor_Conv: operation=rp_CS_MemAbsGet.Get_BsConst_PCB_Temperature_Sensor_Conv
            OA_rp_CS_MemAbsGet_Get_BsConst_Display_Illum_Max_Level: operation=rp_CS_MemAbsGet.Get_BsConst_Display_Illum_Max_Level
            OA_rp_CS_MemAbsGet_Get_BsConst_PWM_boost_bypass_duty: operation=rp_CS_MemAbsGet.Get_BsConst_PWM_boost_bypass_duty
            OA_rp_CS_MemAbsGet_Get_BsConst_BsConst_Illumination_ReservedByte: operation=rp_CS_MemAbsGet.Get_BsConst_BsConst_Illumination_ReservedByte
            OA_rp_CS_MemAbsGet_Get_BsConst_Compensation_Line_Slope_m_SafeCopy1: operation=rp_CS_MemAbsGet.Get_BsConst_Compensation_Line_Slope_m_SafeCopy1
            OA_rp_CS_MemAbsGet_Get_BsConst_Compensation_Line_Shift_b_SafeCopy1: operation=rp_CS_MemAbsGet.Get_BsConst_Compensation_Line_Shift_b_SafeCopy1
            OA_rp_CS_MemAbsGet_Get_BsConst_Lookup_Curve_HotSpot_Coef_X_SafeCopy1: operation=rp_CS_MemAbsGet.Get_BsConst_Lookup_Curve_HotSpot_Coef_X_SafeCopy1
            OA_rp_CS_MemAbsGet_Get_BsConst_Lookup_Curve_HotSpot_Coef_Y_SafeCopy1: operation=rp_CS_MemAbsGet.Get_BsConst_Lookup_Curve_HotSpot_Coef_Y_SafeCopy1
            OA_rp_CS_MemAbsGet_Get_BsConst_Temp_Threshold_Hysteresis_Derating_SafeCopy1: operation=rp_CS_MemAbsGet.Get_BsConst_Temp_Threshold_Hysteresis_Derating_SafeCopy1
            OA_rp_CS_MemAbsGet_Get_BsConst_Derating_Backlight_Disable_SafeCopy1: operation=rp_CS_MemAbsGet.Get_BsConst_Derating_Backlight_Disable_SafeCopy1
            OA_rp_CS_MemAbsGet_Get_BsConst_Temperature_Sensor_Conv_SafeCopy1: operation=rp_CS_MemAbsGet.Get_BsConst_Temperature_Sensor_Conv_SafeCopy1
            OA_rp_CS_MemAbsGet_Get_BsConst_PCB_Temperature_Sensor_Conv_SafeCopy1: operation=rp_CS_MemAbsGet.Get_BsConst_PCB_Temperature_Sensor_Conv_SafeCopy1
            OA_rp_CS_MemAbsGet_Get_BsConst_Display_Illum_Max_Level_SafeCopy1: operation=rp_CS_MemAbsGet.Get_BsConst_Display_Illum_Max_Level_SafeCopy1
            OA_rp_CS_MemAbsGet_Get_BsConst_PWM_boost_bypass_duty_SafeCopy1: operation=rp_CS_MemAbsGet.Get_BsConst_PWM_boost_bypass_duty_SafeCopy1
            OA_rp_CS_MemAbsGet_Get_BsConst_BsConst_Illumination_ReservedByte_SafeCopy1: operation=rp_CS_MemAbsGet.Get_BsConst_BsConst_Illumination_ReservedByte_SafeCopy1
            OA_rp_CS_MemAbsGet_Get_BsConst_Compensation_Line_Slope_m_SafeCopy2: operation=rp_CS_MemAbsGet.Get_BsConst_Compensation_Line_Slope_m_SafeCopy2
            OA_rp_CS_MemAbsGet_Get_BsConst_Compensation_Line_Shift_b_SafeCopy2: operation=rp_CS_MemAbsGet.Get_BsConst_Compensation_Line_Shift_b_SafeCopy2
            OA_rp_CS_MemAbsGet_Get_BsConst_Lookup_Curve_HotSpot_Coef_X_SafeCopy2: operation=rp_CS_MemAbsGet.Get_BsConst_Lookup_Curve_HotSpot_Coef_X_SafeCopy2
            OA_rp_CS_MemAbsGet_Get_BsConst_Lookup_Curve_HotSpot_Coef_Y_SafeCopy2: operation=rp_CS_MemAbsGet.Get_BsConst_Lookup_Curve_HotSpot_Coef_Y_SafeCopy2
            OA_rp_CS_MemAbsGet_Get_BsConst_Temp_Threshold_Hysteresis_Derating_SafeCopy2: operation=rp_CS_MemAbsGet.Get_BsConst_Temp_Threshold_Hysteresis_Derating_SafeCopy2
            OA_rp_CS_MemAbsGet_Get_BsConst_Derating_Backlight_Disable_SafeCopy2: operation=rp_CS_MemAbsGet.Get_BsConst_Derating_Backlight_Disable_SafeCopy2
            OA_rp_CS_MemAbsGet_Get_BsConst_Temperature_Sensor_Conv_SafeCopy2: operation=rp_CS_MemAbsGet.Get_BsConst_Temperature_Sensor_Conv_SafeCopy2
            OA_rp_CS_MemAbsGet_Get_BsConst_PCB_Temperature_Sensor_Conv_SafeCopy2: operation=rp_CS_MemAbsGet.Get_BsConst_PCB_Temperature_Sensor_Conv_SafeCopy2
            OA_rp_CS_MemAbsGet_Get_BsConst_Display_Illum_Max_Level_SafeCopy2: operation=rp_CS_MemAbsGet.Get_BsConst_Display_Illum_Max_Level_SafeCopy2
            OA_rp_CS_MemAbsGet_Get_BsConst_PWM_boost_bypass_duty_SafeCopy2: operation=rp_CS_MemAbsGet.Get_BsConst_PWM_boost_bypass_duty_SafeCopy2
            OA_rp_CS_MemAbsGet_Get_BsConst_BsConst_Illumination_ReservedByte_SafeCopy2: operation=rp_CS_MemAbsGet.Get_BsConst_BsConst_Illumination_ReservedByte_SafeCopy2
            OA_rp_CS_MemAbsGet_Get_BsConst_Audio_Element: operation=rp_CS_MemAbsGet.Get_BsConst_Audio_Element
            OA_rp_CS_MemAbsGet_Get_BsConst_Warning_Element: operation=rp_CS_MemAbsGet.Get_BsConst_Warning_Element
            OA_rp_CS_MemAbsGet_Get_BsConst_RealTimeClock_Element: operation=rp_CS_MemAbsGet.Get_BsConst_RealTimeClock_Element
            OA_rp_CS_MemAbsGet_Get_BsConst_Communication_Element: operation=rp_CS_MemAbsGet.Get_BsConst_Communication_Element
            OA_rp_CS_MemAbsGet_Get_BsConst_Power_Element: operation=rp_CS_MemAbsGet.Get_BsConst_Power_Element
            OA_rp_CS_MemAbsGet_Get_BsConst_ServiceReminder_Element: operation=rp_CS_MemAbsGet.Get_BsConst_ServiceReminder_Element
            OA_rp_CS_MemAbsGet_Get_BsConst_EngOffTimer_Element: operation=rp_CS_MemAbsGet.Get_BsConst_EngOffTimer_Element
            OA_rp_CS_MemAbsGet_Get_BsCys_Certicificate_Element: operation=rp_CS_MemAbsGet.Get_BsCys_Certicificate_Element
            OA_rp_CS_MemAbsGet_Get_RefCys_Certicificate_Element: operation=rp_CS_MemAbsGet.Get_RefCys_Certicificate_Element
            OA_rp_CS_MemAbsGet_Get_RefCys_Certicificate1_Element: operation=rp_CS_MemAbsGet.Get_RefCys_Certicificate1_Element
            OA_rp_CS_MemAbsGet_Get_BsRt_Odometer_Element: operation=rp_CS_MemAbsGet.Get_BsRt_Odometer_Element
            OA_rp_CS_MemAbsGet_Get_BsRt_SpeedoGauge_Element: operation=rp_CS_MemAbsGet.Get_BsRt_SpeedoGauge_Element
            OA_rp_CS_MemAbsGet_Get_BsRt_TachoGauge_Element: operation=rp_CS_MemAbsGet.Get_BsRt_TachoGauge_Element
            OA_rp_CS_MemAbsGet_Get_BsRt_FuelGauge_Element: operation=rp_CS_MemAbsGet.Get_BsRt_FuelGauge_Element
            OA_rp_CS_MemAbsGet_Get_BsRt_TempGauge_Element: operation=rp_CS_MemAbsGet.Get_BsRt_TempGauge_Element
            OA_rp_CS_MemAbsGet_Get_BsRt_PowerGauge_Element: operation=rp_CS_MemAbsGet.Get_BsRt_PowerGauge_Element
            OA_rp_CS_MemAbsGet_Get_BsRt_OilGauge_Element: operation=rp_CS_MemAbsGet.Get_BsRt_OilGauge_Element
            OA_rp_CS_MemAbsGet_Get_BsRt_TripComputer_Element: operation=rp_CS_MemAbsGet.Get_BsRt_TripComputer_Element
            OA_rp_CS_MemAbsGet_Get_BsRt_Warning_Element: operation=rp_CS_MemAbsGet.Get_BsRt_Warning_Element
            OA_rp_CS_MemAbsGet_Get_BsRt_RealTimeClock_Element: operation=rp_CS_MemAbsGet.Get_BsRt_RealTimeClock_Element
            OA_rp_CS_MemAbsGet_Get_BsRt_Personalization_Element: operation=rp_CS_MemAbsGet.Get_BsRt_Personalization_Element
            OA_rp_CS_MemAbsGet_Get_BsRt_Illumination_Element: operation=rp_CS_MemAbsGet.Get_BsRt_Illumination_Element
            OA_rp_CS_MemAbsGet_Get_BsRt_CusDlt_Element: operation=rp_CS_MemAbsGet.Get_BsRt_CusDlt_Element
            OA_rp_CS_MemAbsGet_Get_BsReten_Odometer_Element: operation=rp_CS_MemAbsGet.Get_BsReten_Odometer_Element
            OA_rp_CS_MemAbsGet_Get_BsReten_Gauges_Element: operation=rp_CS_MemAbsGet.Get_BsReten_Gauges_Element
            OA_rp_CS_MemAbsGet_Get_BsReten_Tripcomputer_Element: operation=rp_CS_MemAbsGet.Get_BsReten_Tripcomputer_Element
            OA_rp_CS_MemAbsGet_Get_BsReten_Illumination_Element: operation=rp_CS_MemAbsGet.Get_BsReten_Illumination_Element
            OA_rp_CS_MemAbsGet_Get_BsReten_Audio_Element: operation=rp_CS_MemAbsGet.Get_BsReten_Audio_Element
            OA_rp_CS_MemAbsGet_Get_BsReten_Warning_Element: operation=rp_CS_MemAbsGet.Get_BsReten_Warning_Element
            OA_rp_CS_MemAbsGet_Get_BsReten_RealTimeClock_Element: operation=rp_CS_MemAbsGet.Get_BsReten_RealTimeClock_Element
            OA_rp_CS_MemAbsGet_Get_BsReten_Communication_Element: operation=rp_CS_MemAbsGet.Get_BsReten_Communication_Element
            OA_rp_CS_MemAbsGet_Get_BsReten_Personalization_Element: operation=rp_CS_MemAbsGet.Get_BsReten_Personalization_Element
            OA_rp_CS_MemAbsGet_Get_BsReten_Power_Element: operation=rp_CS_MemAbsGet.Get_BsReten_Power_Element
            OA_rp_CS_MemAbsGet_Get_BsReten_Display_Element: operation=rp_CS_MemAbsGet.Get_BsReten_Display_Element
            OA_rp_CS_MemAbsGet_Get_BsDiag_ErrorRecord_Element: operation=rp_CS_MemAbsGet.Get_BsDiag_ErrorRecord_Element
            OA_rp_CS_MemAbsGet_Get_BsDiag_Dtc_Element: operation=rp_CS_MemAbsGet.Get_BsDiag_Dtc_Element
            OA_rp_CS_MemAbsSet_Set_BsShare_SwUpdReflash_Element: operation=rp_CS_MemAbsSet.Set_BsShare_SwUpdReflash_Element
            OA_rp_CS_MemAbsSet_Set_BsShare_SwUpdFotaMode_Element: operation=rp_CS_MemAbsSet.Set_BsShare_SwUpdFotaMode_Element
            OA_rp_CS_MemAbsSet_Set_BsShare_SwUpdFotaFinPrint_Element: operation=rp_CS_MemAbsSet.Set_BsShare_SwUpdFotaFinPrint_Element
            OA_rp_CS_MemAbsSet_Set_BsShare_SwUpdFotaStatus_Element: operation=rp_CS_MemAbsSet.Set_BsShare_SwUpdFotaStatus_Element
            OA_rp_CS_MemAbsSet_Set_BsShare_SwUpdFotadecrypt_Element: operation=rp_CS_MemAbsSet.Set_BsShare_SwUpdFotadecrypt_Element
            OA_rp_CS_MemAbsSet_Set_BsShare_EcuPartNumber_Element: operation=rp_CS_MemAbsSet.Set_BsShare_EcuPartNumber_Element
            OA_rp_CS_MemAbsSet_Set_BsShare_VisteonPartNumber: operation=rp_CS_MemAbsSet.Set_BsShare_VisteonPartNumber
            OA_rp_CS_MemAbsSet_Set_BsShare_VisteonPCBPartNumber: operation=rp_CS_MemAbsSet.Set_BsShare_VisteonPCBPartNumber
            OA_rp_CS_MemAbsSet_Set_BsShare_ProductSerialNumber: operation=rp_CS_MemAbsSet.Set_BsShare_ProductSerialNumber
            OA_rp_CS_MemAbsSet_Set_BsShare_PCBSerialNumber: operation=rp_CS_MemAbsSet.Set_BsShare_PCBSerialNumber
            OA_rp_CS_MemAbsSet_Set_BsShare_SMTManufacturingDate: operation=rp_CS_MemAbsSet.Set_BsShare_SMTManufacturingDate
            OA_rp_CS_MemAbsSet_Set_BsShare_AssemblyManufacturingDate: operation=rp_CS_MemAbsSet.Set_BsShare_AssemblyManufacturingDate
            OA_rp_CS_MemAbsSet_Set_BsShare_SMTPlantNumber: operation=rp_CS_MemAbsSet.Set_BsShare_SMTPlantNumber
            OA_rp_CS_MemAbsSet_Set_BsShare_AssemblyPlantNumber: operation=rp_CS_MemAbsSet.Set_BsShare_AssemblyPlantNumber
            OA_rp_CS_MemAbsSet_Set_BsShare_HWModification: operation=rp_CS_MemAbsSet.Set_BsShare_HWModification
            OA_rp_CS_MemAbsSet_Set_BsShare_VisMeet_Element: operation=rp_CS_MemAbsSet.Set_BsShare_VisMeet_Element
            OA_rp_CS_MemAbsSet_Set_BsShare_VisMeet_EOLEntry_Element: operation=rp_CS_MemAbsSet.Set_BsShare_VisMeet_EOLEntry_Element
            OA_rp_CS_MemAbsSet_Set_BsShare_VehicleConfig_Element: operation=rp_CS_MemAbsSet.Set_BsShare_VehicleConfig_Element
            OA_rp_CS_MemAbsSet_Set_BsConst_SpeedoGauge_Element: operation=rp_CS_MemAbsSet.Set_BsConst_SpeedoGauge_Element
            OA_rp_CS_MemAbsSet_Set_BsConst_TachoGauge_Element: operation=rp_CS_MemAbsSet.Set_BsConst_TachoGauge_Element
            OA_rp_CS_MemAbsSet_Set_BsConst_FuelGauge_Element: operation=rp_CS_MemAbsSet.Set_BsConst_FuelGauge_Element
            OA_rp_CS_MemAbsSet_Set_BsConst_TempGauge_Element: operation=rp_CS_MemAbsSet.Set_BsConst_TempGauge_Element
            OA_rp_CS_MemAbsSet_Set_BsConst_PowerGauge_Element: operation=rp_CS_MemAbsSet.Set_BsConst_PowerGauge_Element
            OA_rp_CS_MemAbsSet_Set_BsConst_OilGauge_Element: operation=rp_CS_MemAbsSet.Set_BsConst_OilGauge_Element
            OA_rp_CS_MemAbsSet_Set_BsConst_TripComputer_Element: operation=rp_CS_MemAbsSet.Set_BsConst_TripComputer_Element
            OA_rp_CS_MemAbsSet_Set_BsConst_Compensation_Line_Slope_m: operation=rp_CS_MemAbsSet.Set_BsConst_Compensation_Line_Slope_m
            OA_rp_CS_MemAbsSet_Set_BsConst_Compensation_Line_Shift_b: operation=rp_CS_MemAbsSet.Set_BsConst_Compensation_Line_Shift_b
            OA_rp_CS_MemAbsSet_Set_BsConst_Lookup_Curve_HotSpot_Coef_X: operation=rp_CS_MemAbsSet.Set_BsConst_Lookup_Curve_HotSpot_Coef_X
            OA_rp_CS_MemAbsSet_Set_BsConst_Lookup_Curve_HotSpot_Coef_Y: operation=rp_CS_MemAbsSet.Set_BsConst_Lookup_Curve_HotSpot_Coef_Y
            OA_rp_CS_MemAbsSet_Set_BsConst_Temp_Threshold_Hysteresis_Derating: operation=rp_CS_MemAbsSet.Set_BsConst_Temp_Threshold_Hysteresis_Derating
            OA_rp_CS_MemAbsSet_Set_BsConst_Derating_Backlight_Disable: operation=rp_CS_MemAbsSet.Set_BsConst_Derating_Backlight_Disable
            OA_rp_CS_MemAbsSet_Set_BsConst_Temperature_Sensor_Conv: operation=rp_CS_MemAbsSet.Set_BsConst_Temperature_Sensor_Conv
            OA_rp_CS_MemAbsSet_Set_BsConst_PCB_Temperature_Sensor_Conv: operation=rp_CS_MemAbsSet.Set_BsConst_PCB_Temperature_Sensor_Conv
            OA_rp_CS_MemAbsSet_Set_BsConst_Display_Illum_Max_Level: operation=rp_CS_MemAbsSet.Set_BsConst_Display_Illum_Max_Level
            OA_rp_CS_MemAbsSet_Set_BsConst_PWM_boost_bypass_duty: operation=rp_CS_MemAbsSet.Set_BsConst_PWM_boost_bypass_duty
            OA_rp_CS_MemAbsSet_Set_BsConst_BsConst_Illumination_ReservedByte: operation=rp_CS_MemAbsSet.Set_BsConst_BsConst_Illumination_ReservedByte
            OA_rp_CS_MemAbsSet_Set_BsConst_Compensation_Line_Slope_m_SafeCopy1: operation=rp_CS_MemAbsSet.Set_BsConst_Compensation_Line_Slope_m_SafeCopy1
            OA_rp_CS_MemAbsSet_Set_BsConst_Compensation_Line_Shift_b_SafeCopy1: operation=rp_CS_MemAbsSet.Set_BsConst_Compensation_Line_Shift_b_SafeCopy1
            OA_rp_CS_MemAbsSet_Set_BsConst_Lookup_Curve_HotSpot_Coef_X_SafeCopy1: operation=rp_CS_MemAbsSet.Set_BsConst_Lookup_Curve_HotSpot_Coef_X_SafeCopy1
            OA_rp_CS_MemAbsSet_Set_BsConst_Lookup_Curve_HotSpot_Coef_Y_SafeCopy1: operation=rp_CS_MemAbsSet.Set_BsConst_Lookup_Curve_HotSpot_Coef_Y_SafeCopy1
            OA_rp_CS_MemAbsSet_Set_BsConst_Temp_Threshold_Hysteresis_Derating_SafeCopy1: operation=rp_CS_MemAbsSet.Set_BsConst_Temp_Threshold_Hysteresis_Derating_SafeCopy1
            OA_rp_CS_MemAbsSet_Set_BsConst_Derating_Backlight_Disable_SafeCopy1: operation=rp_CS_MemAbsSet.Set_BsConst_Derating_Backlight_Disable_SafeCopy1
            OA_rp_CS_MemAbsSet_Set_BsConst_Temperature_Sensor_Conv_SafeCopy1: operation=rp_CS_MemAbsSet.Set_BsConst_Temperature_Sensor_Conv_SafeCopy1
            OA_rp_CS_MemAbsSet_Set_BsConst_PCB_Temperature_Sensor_Conv_SafeCopy1: operation=rp_CS_MemAbsSet.Set_BsConst_PCB_Temperature_Sensor_Conv_SafeCopy1
            OA_rp_CS_MemAbsSet_Set_BsConst_Display_Illum_Max_Level_SafeCopy1: operation=rp_CS_MemAbsSet.Set_BsConst_Display_Illum_Max_Level_SafeCopy1
            OA_rp_CS_MemAbsSet_Set_BsConst_PWM_boost_bypass_duty_SafeCopy1: operation=rp_CS_MemAbsSet.Set_BsConst_PWM_boost_bypass_duty_SafeCopy1
            OA_rp_CS_MemAbsSet_Set_BsConst_BsConst_Illumination_ReservedByte_SafeCopy1: operation=rp_CS_MemAbsSet.Set_BsConst_BsConst_Illumination_ReservedByte_SafeCopy1
            OA_rp_CS_MemAbsSet_Set_BsConst_Compensation_Line_Slope_m_SafeCopy2: operation=rp_CS_MemAbsSet.Set_BsConst_Compensation_Line_Slope_m_SafeCopy2
            OA_rp_CS_MemAbsSet_Set_BsConst_Compensation_Line_Shift_b_SafeCopy2: operation=rp_CS_MemAbsSet.Set_BsConst_Compensation_Line_Shift_b_SafeCopy2
            OA_rp_CS_MemAbsSet_Set_BsConst_Lookup_Curve_HotSpot_Coef_X_SafeCopy2: operation=rp_CS_MemAbsSet.Set_BsConst_Lookup_Curve_HotSpot_Coef_X_SafeCopy2
            OA_rp_CS_MemAbsSet_Set_BsConst_Lookup_Curve_HotSpot_Coef_Y_SafeCopy2: operation=rp_CS_MemAbsSet.Set_BsConst_Lookup_Curve_HotSpot_Coef_Y_SafeCopy2
            OA_rp_CS_MemAbsSet_Set_BsConst_Temp_Threshold_Hysteresis_Derating_SafeCopy2: operation=rp_CS_MemAbsSet.Set_BsConst_Temp_Threshold_Hysteresis_Derating_SafeCopy2
            OA_rp_CS_MemAbsSet_Set_BsConst_Derating_Backlight_Disable_SafeCopy2: operation=rp_CS_MemAbsSet.Set_BsConst_Derating_Backlight_Disable_SafeCopy2
            OA_rp_CS_MemAbsSet_Set_BsConst_Temperature_Sensor_Conv_SafeCopy2: operation=rp_CS_MemAbsSet.Set_BsConst_Temperature_Sensor_Conv_SafeCopy2
            OA_rp_CS_MemAbsSet_Set_BsConst_PCB_Temperature_Sensor_Conv_SafeCopy2: operation=rp_CS_MemAbsSet.Set_BsConst_PCB_Temperature_Sensor_Conv_SafeCopy2
            OA_rp_CS_MemAbsSet_Set_BsConst_Display_Illum_Max_Level_SafeCopy2: operation=rp_CS_MemAbsSet.Set_BsConst_Display_Illum_Max_Level_SafeCopy2
            OA_rp_CS_MemAbsSet_Set_BsConst_PWM_boost_bypass_duty_SafeCopy2: operation=rp_CS_MemAbsSet.Set_BsConst_PWM_boost_bypass_duty_SafeCopy2
            OA_rp_CS_MemAbsSet_Set_BsConst_BsConst_Illumination_ReservedByte_SafeCopy2: operation=rp_CS_MemAbsSet.Set_BsConst_BsConst_Illumination_ReservedByte_SafeCopy2
            OA_rp_CS_MemAbsSet_Set_BsConst_Audio_Element: operation=rp_CS_MemAbsSet.Set_BsConst_Audio_Element
            OA_rp_CS_MemAbsSet_Set_BsConst_Warning_Element: operation=rp_CS_MemAbsSet.Set_BsConst_Warning_Element
            OA_rp_CS_MemAbsSet_Set_BsConst_RealTimeClock_Element: operation=rp_CS_MemAbsSet.Set_BsConst_RealTimeClock_Element
            OA_rp_CS_MemAbsSet_Set_BsConst_Communication_Element: operation=rp_CS_MemAbsSet.Set_BsConst_Communication_Element
            OA_rp_CS_MemAbsSet_Set_BsConst_Power_Element: operation=rp_CS_MemAbsSet.Set_BsConst_Power_Element
            OA_rp_CS_MemAbsSet_Set_BsConst_ServiceReminder_Element: operation=rp_CS_MemAbsSet.Set_BsConst_ServiceReminder_Element
            OA_rp_CS_MemAbsSet_Set_BsConst_EngOffTimer_Element: operation=rp_CS_MemAbsSet.Set_BsConst_EngOffTimer_Element
            OA_rp_CS_MemAbsSet_Set_BsCys_Certicificate_Element: operation=rp_CS_MemAbsSet.Set_BsCys_Certicificate_Element
            OA_rp_CS_MemAbsSet_Set_RefCys_Certicificate_Element: operation=rp_CS_MemAbsSet.Set_RefCys_Certicificate_Element
            OA_rp_CS_MemAbsSet_Set_RefCys_Certicificate1_Element: operation=rp_CS_MemAbsSet.Set_RefCys_Certicificate1_Element
            OA_rp_CS_MemAbsSet_Set_BsRt_Odometer_Element: operation=rp_CS_MemAbsSet.Set_BsRt_Odometer_Element
            OA_rp_CS_MemAbsSet_Set_BsRt_SpeedoGauge_Element: operation=rp_CS_MemAbsSet.Set_BsRt_SpeedoGauge_Element
            OA_rp_CS_MemAbsSet_Set_BsRt_TachoGauge_Element: operation=rp_CS_MemAbsSet.Set_BsRt_TachoGauge_Element
            OA_rp_CS_MemAbsSet_Set_BsRt_FuelGauge_Element: operation=rp_CS_MemAbsSet.Set_BsRt_FuelGauge_Element
            OA_rp_CS_MemAbsSet_Set_BsRt_TempGauge_Element: operation=rp_CS_MemAbsSet.Set_BsRt_TempGauge_Element
            OA_rp_CS_MemAbsSet_Set_BsRt_PowerGauge_Element: operation=rp_CS_MemAbsSet.Set_BsRt_PowerGauge_Element
            OA_rp_CS_MemAbsSet_Set_BsRt_OilGauge_Element: operation=rp_CS_MemAbsSet.Set_BsRt_OilGauge_Element
            OA_rp_CS_MemAbsSet_Set_BsRt_TripComputer_Element: operation=rp_CS_MemAbsSet.Set_BsRt_TripComputer_Element
            OA_rp_CS_MemAbsSet_Set_BsRt_Warning_Element: operation=rp_CS_MemAbsSet.Set_BsRt_Warning_Element
            OA_rp_CS_MemAbsSet_Set_BsRt_RealTimeClock_Element: operation=rp_CS_MemAbsSet.Set_BsRt_RealTimeClock_Element
            OA_rp_CS_MemAbsSet_Set_BsRt_Personalization_Element: operation=rp_CS_MemAbsSet.Set_BsRt_Personalization_Element
            OA_rp_CS_MemAbsSet_Set_BsRt_Illumination_Element: operation=rp_CS_MemAbsSet.Set_BsRt_Illumination_Element
            OA_rp_CS_MemAbsSet_Set_BsRt_CusDlt_Element: operation=rp_CS_MemAbsSet.Set_BsRt_CusDlt_Element
            OA_rp_CS_MemAbsSet_Set_BsReten_Odometer_Element: operation=rp_CS_MemAbsSet.Set_BsReten_Odometer_Element
            OA_rp_CS_MemAbsSet_Set_BsReten_Gauges_Element: operation=rp_CS_MemAbsSet.Set_BsReten_Gauges_Element
            OA_rp_CS_MemAbsSet_Set_BsReten_Tripcomputer_Element: operation=rp_CS_MemAbsSet.Set_BsReten_Tripcomputer_Element
            OA_rp_CS_MemAbsSet_Set_BsReten_Illumination_Element: operation=rp_CS_MemAbsSet.Set_BsReten_Illumination_Element
            OA_rp_CS_MemAbsSet_Set_BsReten_Audio_Element: operation=rp_CS_MemAbsSet.Set_BsReten_Audio_Element
            OA_rp_CS_MemAbsSet_Set_BsReten_Warning_Element: operation=rp_CS_MemAbsSet.Set_BsReten_Warning_Element
            OA_rp_CS_MemAbsSet_Set_BsReten_RealTimeClock_Element: operation=rp_CS_MemAbsSet.Set_BsReten_RealTimeClock_Element
            OA_rp_CS_MemAbsSet_Set_BsReten_Communication_Element: operation=rp_CS_MemAbsSet.Set_BsReten_Communication_Element
            OA_rp_CS_MemAbsSet_Set_BsReten_Personalization_Element: operation=rp_CS_MemAbsSet.Set_BsReten_Personalization_Element
            OA_rp_CS_MemAbsSet_Set_BsReten_Power_Element: operation=rp_CS_MemAbsSet.Set_BsReten_Power_Element
            OA_rp_CS_MemAbsSet_Set_BsReten_Display_Element: operation=rp_CS_MemAbsSet.Set_BsReten_Display_Element
            OA_rp_CS_MemAbsSet_Set_BsDiag_ErrorRecord_Element: operation=rp_CS_MemAbsSet.Set_BsDiag_ErrorRecord_Element
            OA_rp_CS_MemAbsSet_Set_BsDiag_Dtc_Element: operation=rp_CS_MemAbsSet.Set_BsDiag_Dtc_Element
        CMeetCdd_Impl_OnCommand
        CMeetCdd_Meet_Mgrdiagcdd_Action
        CMeetCdd_RID_DiagAction
        CMeetCdd_Read_ManufModeStatus
        CMeetCdd_Write_Mfg_Flag
  95 x constant specification:
    CMeetCddSleepReqDataValue0: value-spec=CMeetCddSleepReqDataValue0:false
    CMeetCddJobStatus_BsConst_Audio_ElementValue0: value-spec=CMeetCddJobStatus_BsConst_Audio_ElementValue0:0
    CMeetCddJobStatus_BsConst_BsConst_Illumination_ReservedByteValue0: value-spec=CMeetCddJobStatus_BsConst_BsConst_Illumination_ReservedByteValue0:0
    CMeetCddJobStatus_BsConst_BsConst_Illumination_ReservedByte_SafeCopy1Value0: value-spec=CMeetCddJobStatus_BsConst_BsConst_Illumination_ReservedByte_SafeCopy1Value0:0
    CMeetCddJobStatus_BsConst_BsConst_Illumination_ReservedByte_SafeCopy2Value0: value-spec=CMeetCddJobStatus_BsConst_BsConst_Illumination_ReservedByte_SafeCopy2Value0:0
    CMeetCddJobStatus_BsConst_Communication_ElementValue0: value-spec=CMeetCddJobStatus_BsConst_Communication_ElementValue0:0
    CMeetCddJobStatus_BsConst_Compensation_Line_Shift_bValue0: value-spec=CMeetCddJobStatus_BsConst_Compensation_Line_Shift_bValue0:0
    CMeetCddJobStatus_BsConst_Compensation_Line_Shift_b_SafeCopy1Value0: value-spec=CMeetCddJobStatus_BsConst_Compensation_Line_Shift_b_SafeCopy1Value0:0
    CMeetCddJobStatus_BsConst_Compensation_Line_Shift_b_SafeCopy2Value0: value-spec=CMeetCddJobStatus_BsConst_Compensation_Line_Shift_b_SafeCopy2Value0:0
    CMeetCddJobStatus_BsConst_Compensation_Line_Slope_mValue0: value-spec=CMeetCddJobStatus_BsConst_Compensation_Line_Slope_mValue0:0
    CMeetCddJobStatus_BsConst_Compensation_Line_Slope_m_SafeCopy1Value0: value-spec=CMeetCddJobStatus_BsConst_Compensation_Line_Slope_m_SafeCopy1Value0:0
    CMeetCddJobStatus_BsConst_Compensation_Line_Slope_m_SafeCopy2Value0: value-spec=CMeetCddJobStatus_BsConst_Compensation_Line_Slope_m_SafeCopy2Value0:0
    CMeetCddJobStatus_BsConst_Derating_Backlight_DisableValue0: value-spec=CMeetCddJobStatus_BsConst_Derating_Backlight_DisableValue0:0
    CMeetCddJobStatus_BsConst_Derating_Backlight_Disable_SafeCopy1Value0: value-spec=CMeetCddJobStatus_BsConst_Derating_Backlight_Disable_SafeCopy1Value0:0
    CMeetCddJobStatus_BsConst_Derating_Backlight_Disable_SafeCopy2Value0: value-spec=CMeetCddJobStatus_BsConst_Derating_Backlight_Disable_SafeCopy2Value0:0
    CMeetCddJobStatus_BsConst_Display_Illum_Max_LevelValue0: value-spec=CMeetCddJobStatus_BsConst_Display_Illum_Max_LevelValue0:0
    CMeetCddJobStatus_BsConst_Display_Illum_Max_Level_SafeCopy1Value0: value-spec=CMeetCddJobStatus_BsConst_Display_Illum_Max_Level_SafeCopy1Value0:0
    CMeetCddJobStatus_BsConst_Display_Illum_Max_Level_SafeCopy2Value0: value-spec=CMeetCddJobStatus_BsConst_Display_Illum_Max_Level_SafeCopy2Value0:0
    CMeetCddJobStatus_BsConst_EngOffTimer_ElementValue0: value-spec=CMeetCddJobStatus_BsConst_EngOffTimer_ElementValue0:0
    CMeetCddJobStatus_BsConst_FuelGauge_ElementValue0: value-spec=CMeetCddJobStatus_BsConst_FuelGauge_ElementValue0:0
    CMeetCddJobStatus_BsConst_Lookup_Curve_HotSpot_Coef_XValue0: value-spec=CMeetCddJobStatus_BsConst_Lookup_Curve_HotSpot_Coef_XValue0:0
    CMeetCddJobStatus_BsConst_Lookup_Curve_HotSpot_Coef_X_SafeCopy1Value0: value-spec=CMeetCddJobStatus_BsConst_Lookup_Curve_HotSpot_Coef_X_SafeCopy1Value0:0
    CMeetCddJobStatus_BsConst_Lookup_Curve_HotSpot_Coef_X_SafeCopy2Value0: value-spec=CMeetCddJobStatus_BsConst_Lookup_Curve_HotSpot_Coef_X_SafeCopy2Value0:0
    CMeetCddJobStatus_BsConst_Lookup_Curve_HotSpot_Coef_YValue0: value-spec=CMeetCddJobStatus_BsConst_Lookup_Curve_HotSpot_Coef_YValue0:0
    CMeetCddJobStatus_BsConst_Lookup_Curve_HotSpot_Coef_Y_SafeCopy1Value0: value-spec=CMeetCddJobStatus_BsConst_Lookup_Curve_HotSpot_Coef_Y_SafeCopy1Value0:0
    CMeetCddJobStatus_BsConst_Lookup_Curve_HotSpot_Coef_Y_SafeCopy2Value0: value-spec=CMeetCddJobStatus_BsConst_Lookup_Curve_HotSpot_Coef_Y_SafeCopy2Value0:0
    CMeetCddJobStatus_BsConst_OilGauge_ElementValue0: value-spec=CMeetCddJobStatus_BsConst_OilGauge_ElementValue0:0
    CMeetCddJobStatus_BsConst_PCB_Temperature_Sensor_ConvValue0: value-spec=CMeetCddJobStatus_BsConst_PCB_Temperature_Sensor_ConvValue0:0
    CMeetCddJobStatus_BsConst_PCB_Temperature_Sensor_Conv_SafeCopy1Value0: value-spec=CMeetCddJobStatus_BsConst_PCB_Temperature_Sensor_Conv_SafeCopy1Value0:0
    CMeetCddJobStatus_BsConst_PCB_Temperature_Sensor_Conv_SafeCopy2Value0: value-spec=CMeetCddJobStatus_BsConst_PCB_Temperature_Sensor_Conv_SafeCopy2Value0:0
    CMeetCddJobStatus_BsConst_PWM_boost_bypass_dutyValue0: value-spec=CMeetCddJobStatus_BsConst_PWM_boost_bypass_dutyValue0:0
    CMeetCddJobStatus_BsConst_PWM_boost_bypass_duty_SafeCopy1Value0: value-spec=CMeetCddJobStatus_BsConst_PWM_boost_bypass_duty_SafeCopy1Value0:0
    CMeetCddJobStatus_BsConst_PWM_boost_bypass_duty_SafeCopy2Value0: value-spec=CMeetCddJobStatus_BsConst_PWM_boost_bypass_duty_SafeCopy2Value0:0
    CMeetCddJobStatus_BsConst_PowerGauge_ElementValue0: value-spec=CMeetCddJobStatus_BsConst_PowerGauge_ElementValue0:0
    CMeetCddJobStatus_BsConst_Power_ElementValue0: value-spec=CMeetCddJobStatus_BsConst_Power_ElementValue0:0
    CMeetCddJobStatus_BsConst_RealTimeClock_ElementValue0: value-spec=CMeetCddJobStatus_BsConst_RealTimeClock_ElementValue0:0
    CMeetCddJobStatus_BsConst_ServiceReminder_ElementValue0: value-spec=CMeetCddJobStatus_BsConst_ServiceReminder_ElementValue0:0
    CMeetCddJobStatus_BsConst_SpeedoGauge_ElementValue0: value-spec=CMeetCddJobStatus_BsConst_SpeedoGauge_ElementValue0:0
    CMeetCddJobStatus_BsConst_TachoGauge_ElementValue0: value-spec=CMeetCddJobStatus_BsConst_TachoGauge_ElementValue0:0
    CMeetCddJobStatus_BsConst_TempGauge_ElementValue0: value-spec=CMeetCddJobStatus_BsConst_TempGauge_ElementValue0:0
    CMeetCddJobStatus_BsConst_Temp_Threshold_Hysteresis_DeratingValue0: value-spec=CMeetCddJobStatus_BsConst_Temp_Threshold_Hysteresis_DeratingValue0:0
    CMeetCddJobStatus_BsConst_Temp_Threshold_Hysteresis_Derating_SafeCopy1Value0: value-spec=CMeetCddJobStatus_BsConst_Temp_Threshold_Hysteresis_Derating_SafeCopy1Value0:0
    CMeetCddJobStatus_BsConst_Temp_Threshold_Hysteresis_Derating_SafeCopy2Value0: value-spec=CMeetCddJobStatus_BsConst_Temp_Threshold_Hysteresis_Derating_SafeCopy2Value0:0
    CMeetCddJobStatus_BsConst_Temperature_Sensor_ConvValue0: value-spec=CMeetCddJobStatus_BsConst_Temperature_Sensor_ConvValue0:0
    CMeetCddJobStatus_BsConst_Temperature_Sensor_Conv_SafeCopy1Value0: value-spec=CMeetCddJobStatus_BsConst_Temperature_Sensor_Conv_SafeCopy1Value0:0
    CMeetCddJobStatus_BsConst_Temperature_Sensor_Conv_SafeCopy2Value0: value-spec=CMeetCddJobStatus_BsConst_Temperature_Sensor_Conv_SafeCopy2Value0:0
    CMeetCddJobStatus_BsConst_TripComputer_ElementValue0: value-spec=CMeetCddJobStatus_BsConst_TripComputer_ElementValue0:0
    CMeetCddJobStatus_BsConst_Warning_ElementValue0: value-spec=CMeetCddJobStatus_BsConst_Warning_ElementValue0:0
    CMeetCddJobStatus_BsCys_Certicificate_ElementValue0: value-spec=CMeetCddJobStatus_BsCys_Certicificate_ElementValue0:0
    CMeetCddJobStatus_BsDiag_Dtc_ElementValue0: value-spec=CMeetCddJobStatus_BsDiag_Dtc_ElementValue0:0
    CMeetCddJobStatus_BsDiag_ErrorRecord_ElementValue0: value-spec=CMeetCddJobStatus_BsDiag_ErrorRecord_ElementValue0:0
    CMeetCddJobStatus_BsReten_Audio_ElementValue0: value-spec=CMeetCddJobStatus_BsReten_Audio_ElementValue0:0
    CMeetCddJobStatus_BsReten_Communication_ElementValue0: value-spec=CMeetCddJobStatus_BsReten_Communication_ElementValue0:0
    CMeetCddJobStatus_BsReten_Display_ElementValue0: value-spec=CMeetCddJobStatus_BsReten_Display_ElementValue0:0
    CMeetCddJobStatus_BsReten_Gauges_ElementValue0: value-spec=CMeetCddJobStatus_BsReten_Gauges_ElementValue0:0
    CMeetCddJobStatus_BsReten_Illumination_ElementValue0: value-spec=CMeetCddJobStatus_BsReten_Illumination_ElementValue0:0
    CMeetCddJobStatus_BsReten_Odometer_ElementValue0: value-spec=CMeetCddJobStatus_BsReten_Odometer_ElementValue0:0
    CMeetCddJobStatus_BsReten_Personalization_ElementValue0: value-spec=CMeetCddJobStatus_BsReten_Personalization_ElementValue0:0
    CMeetCddJobStatus_BsReten_Power_ElementValue0: value-spec=CMeetCddJobStatus_BsReten_Power_ElementValue0:0
    CMeetCddJobStatus_BsReten_RealTimeClock_ElementValue0: value-spec=CMeetCddJobStatus_BsReten_RealTimeClock_ElementValue0:0
    CMeetCddJobStatus_BsReten_Tripcomputer_ElementValue0: value-spec=CMeetCddJobStatus_BsReten_Tripcomputer_ElementValue0:0
    CMeetCddJobStatus_BsReten_Warning_ElementValue0: value-spec=CMeetCddJobStatus_BsReten_Warning_ElementValue0:0
    CMeetCddJobStatus_BsRt_CusDlt_ElementValue0: value-spec=CMeetCddJobStatus_BsRt_CusDlt_ElementValue0:0
    CMeetCddJobStatus_BsRt_FuelGauge_ElementValue0: value-spec=CMeetCddJobStatus_BsRt_FuelGauge_ElementValue0:0
    CMeetCddJobStatus_BsRt_Illumination_ElementValue0: value-spec=CMeetCddJobStatus_BsRt_Illumination_ElementValue0:0
    CMeetCddJobStatus_BsRt_Odometer_ElementValue0: value-spec=CMeetCddJobStatus_BsRt_Odometer_ElementValue0:0
    CMeetCddJobStatus_BsRt_OilGauge_ElementValue0: value-spec=CMeetCddJobStatus_BsRt_OilGauge_ElementValue0:0
    CMeetCddJobStatus_BsRt_Personalization_ElementValue0: value-spec=CMeetCddJobStatus_BsRt_Personalization_ElementValue0:0
    CMeetCddJobStatus_BsRt_PowerGauge_ElementValue0: value-spec=CMeetCddJobStatus_BsRt_PowerGauge_ElementValue0:0
    CMeetCddJobStatus_BsRt_RealTimeClock_ElementValue0: value-spec=CMeetCddJobStatus_BsRt_RealTimeClock_ElementValue0:0
    CMeetCddJobStatus_BsRt_SpeedoGauge_ElementValue0: value-spec=CMeetCddJobStatus_BsRt_SpeedoGauge_ElementValue0:0
    CMeetCddJobStatus_BsRt_TachoGauge_ElementValue0: value-spec=CMeetCddJobStatus_BsRt_TachoGauge_ElementValue0:0
    CMeetCddJobStatus_BsRt_TempGauge_ElementValue0: value-spec=CMeetCddJobStatus_BsRt_TempGauge_ElementValue0:0
    CMeetCddJobStatus_BsRt_TripComputer_ElementValue0: value-spec=CMeetCddJobStatus_BsRt_TripComputer_ElementValue0:0
    CMeetCddJobStatus_BsRt_Warning_ElementValue0: value-spec=CMeetCddJobStatus_BsRt_Warning_ElementValue0:0
    CMeetCddJobStatus_BsShare_AssemblyManufacturingDateValue0: value-spec=CMeetCddJobStatus_BsShare_AssemblyManufacturingDateValue0:0
    CMeetCddJobStatus_BsShare_AssemblyPlantNumberValue0: value-spec=CMeetCddJobStatus_BsShare_AssemblyPlantNumberValue0:0
    CMeetCddJobStatus_BsShare_EcuPartNumber_ElementValue0: value-spec=CMeetCddJobStatus_BsShare_EcuPartNumber_ElementValue0:0
    CMeetCddJobStatus_BsShare_HWModificationValue0: value-spec=CMeetCddJobStatus_BsShare_HWModificationValue0:0
    CMeetCddJobStatus_BsShare_PCBSerialNumberValue0: value-spec=CMeetCddJobStatus_BsShare_PCBSerialNumberValue0:0
    CMeetCddJobStatus_BsShare_ProductSerialNumberValue0: value-spec=CMeetCddJobStatus_BsShare_ProductSerialNumberValue0:0
    CMeetCddJobStatus_BsShare_SMTManufacturingDateValue0: value-spec=CMeetCddJobStatus_BsShare_SMTManufacturingDateValue0:0
    CMeetCddJobStatus_BsShare_SMTPlantNumberValue0: value-spec=CMeetCddJobStatus_BsShare_SMTPlantNumberValue0:0
    CMeetCddJobStatus_BsShare_SwUpdFotaFinPrint_ElementValue0: value-spec=CMeetCddJobStatus_BsShare_SwUpdFotaFinPrint_ElementValue0:0
    CMeetCddJobStatus_BsShare_SwUpdFotaMode_ElementValue0: value-spec=CMeetCddJobStatus_BsShare_SwUpdFotaMode_ElementValue0:0
    CMeetCddJobStatus_BsShare_SwUpdFotaStatus_ElementValue0: value-spec=CMeetCddJobStatus_BsShare_SwUpdFotaStatus_ElementValue0:0
    CMeetCddJobStatus_BsShare_SwUpdFotadecrypt_ElementValue0: value-spec=CMeetCddJobStatus_BsShare_SwUpdFotadecrypt_ElementValue0:0
    CMeetCddJobStatus_BsShare_SwUpdReflash_ElementValue0: value-spec=CMeetCddJobStatus_BsShare_SwUpdReflash_ElementValue0:0
    CMeetCddJobStatus_BsShare_VehicleConfig_ElementValue0: value-spec=CMeetCddJobStatus_BsShare_VehicleConfig_ElementValue0:0
    CMeetCddJobStatus_BsShare_VisMeet_EOLEntry_ElementValue0: value-spec=CMeetCddJobStatus_BsShare_VisMeet_EOLEntry_ElementValue0:0
    CMeetCddJobStatus_BsShare_VisMeet_ElementValue0: value-spec=CMeetCddJobStatus_BsShare_VisMeet_ElementValue0:0
    CMeetCddJobStatus_BsShare_VisteonPCBPartNumberValue0: value-spec=CMeetCddJobStatus_BsShare_VisteonPCBPartNumberValue0:0
    CMeetCddJobStatus_BsShare_VisteonPartNumberValue0: value-spec=CMeetCddJobStatus_BsShare_VisteonPartNumberValue0:0
    CMeetCddJobStatus_RefCys_Certicificate1_ElementValue0: value-spec=CMeetCddJobStatus_RefCys_Certicificate1_ElementValue0:0
    CMeetCddJobStatus_RefCys_Certicificate_ElementValue0: value-spec=CMeetCddJobStatus_RefCys_Certicificate_ElementValue0:0
  swc implementation IMPL_CMeetCdd: programming-language=C, behavior=IB_CMeetCdd
    code-descriptors:
      code CodeDescriptor
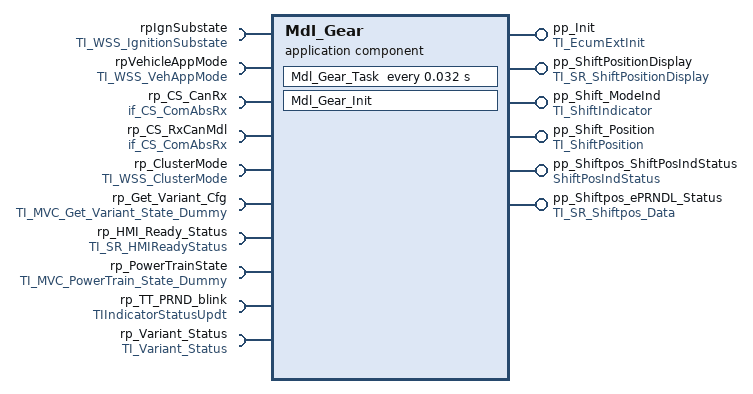
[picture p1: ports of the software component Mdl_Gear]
  application sw component type Mdl_Gear
    6 x provide port:
      pp_Init: server-com-spec{operation=TI_EcumExtInit/Init, queue-length=1}, provided-interface=TI_EcumExtInit
      pp_ShiftPositionDisplay: nonqueued-sender-com-spec{data-element=ShiftPositionDisplay, init-value=constant-reference=Mdl_GearShiftPositionDisplayValue0}, provided-interface=TI_SR_ShiftPositionDisplay
      pp_Shift_ModeInd: nonqueued-sender-com-spec{data-element=ShiftModeIndicator, init-value=constant-reference=Mdl_GearShiftModeIndicatorValue0}, provided-interface=TI_ShiftIndicator
      pp_Shift_Position: nonqueued-sender-com-spec{data-element=ShiftPosition, init-value=constant-reference=Mdl_GearShiftPositionValue0}, provided-interface=TI_ShiftPosition
      pp_Shiftpos_ShiftPosIndStatus: nonqueued-sender-com-spec{data-element=ShiftPosIndStatusData, init-value=constant-reference=Mdl_GearShiftPosIndStatusDataValue0}, provided-interface=ShiftPosIndStatus
      pp_Shiftpos_ePRNDL_Status: nonqueued-sender-com-spec{data-element=ShiftPos_Data, init-value=constant-reference=Mdl_GearShiftPos_DataValue0}, provided-interface=TI_SR_Shiftpos_Data
    10 x require port:
      rpIgnSubstate: nonqueued-receiver-com-spec{data-element=IgnitionSubstate, init-value=constant-reference=Mdl_GearIgnitionSubstateValue0}, required-interface=TI_WSS_IgnitionSubstate
      rpVehicleAppMode: nonqueued-receiver-com-spec{data-element=WSSCurrentVehicleState, init-value=constant-reference=Mdl_GearWSSCurrentVehicleStateValue0}, required-interface=TI_WSS_VehAppMode
      rp_CS_CanRx: required-interface=if_CS_ComAbsRx
      rp_CS_RxCanMdl: required-interface=if_CS_ComAbsRx
      rp_ClusterMode: nonqueued-receiver-com-spec{data-element=WSSCurrentClusterMode, init-value=constant-reference=Mdl_GearWSSCurrentClusterModeValue0}, required-interface=TI_WSS_ClusterMode
      rp_Get_Variant_Cfg: required-interface=TI_MVC_Get_Variant_State_Dummy
      rp_HMI_Ready_Status: nonqueued-receiver-com-spec{data-element=HMI_ReadyStatus, init-value=constant-reference=Mdl_GearHMI_ReadyStatusValue0}, required-interface=TI_SR_HMIReadyStatus
      rp_PowerTrainState: nonqueued-receiver-com-spec{data-element=PowerTrain_Flag, init-value=constant-reference=Mdl_GearPowerTrain_FlagValue0}, required-interface=TI_MVC_PowerTrain_State_Dummy
      rp_TT_PRND_blink: nonqueued-receiver-com-spec{data-element=TIUpdateIndicatorStatus, init-value=constant-reference=Mdl_GearTIUpdateIndicatorStatusValue0}, required-interface=TIIndicatorStatusUpdt
      rp_Variant_Status: required-interface=TI_Variant_Status
    behavior IB_Mdl_Gear
      operation invoked event OIE_pp_Init_Mdl_Gear_InitTrigByInit: start-on-event=Mdl_Gear_Init, operation=pp_Init.Init
      timing event TEMdl_Gear_Task: start-on-event=Mdl_Gear_Task, period=0.032
      port-api-options:
        enable-take-address=false, indirect-api=false, port=Mdl_Gear/pp_Init
        enable-take-address=false, indirect-api=false, port=pp_ShiftPositionDisplay
        enable-take-address=false, indirect-api=false, port=pp_Shift_ModeInd
        enable-take-address=false, indirect-api=false, port=pp_Shift_Position
        enable-take-address=false, indirect-api=false, port=pp_Shiftpos_ShiftPosIndStatus
        enable-take-address=false, indirect-api=false, port=pp_Shiftpos_ePRNDL_Status
        enable-take-address=false, indirect-api=false, port=Mdl_Gear/rpIgnSubstate
        enable-take-address=false, indirect-api=false, port=Mdl_Gear/rpVehicleAppMode
        enable-take-address=false, indirect-api=false, port=Mdl_Gear/rp_CS_CanRx
        enable-take-address=false, indirect-api=false, port=Mdl_Gear/rp_CS_RxCanMdl
        enable-take-address=false, indirect-api=false, port=Mdl_Gear/rp_ClusterMode
        enable-take-address=false, indirect-api=false, port=Mdl_Gear/rp_Get_Variant_Cfg
        enable-take-address=false, indirect-api=false, port=rp_HMI_Ready_Status
        enable-take-address=false, indirect-api=false, port=rp_PowerTrainState
        enable-take-address=false, indirect-api=false, port=rp_TT_PRND_blink
        enable-take-address=false, indirect-api=false, port=Mdl_Gear/rp_Variant_Status
      runnable Mdl_Gear_Init: can-be-invoked-concurrently=true
      runnable Mdl_Gear_Task: can-be-invoked-concurrently=true
        data-receive-point-by-arguments:
          6 x access:
            DRA_rpIgnSubstate_IgnitionSubstate: accessed-variable=rpIgnSubstate.IgnitionSubstate
            DRA_rpVehicleAppMode_WSSCurrentVehicleState: accessed-variable=rpVehicleAppMode.WSSCurrentVehicleState
            DRA_rp_ClusterMode_WSSCurrentClusterMode: accessed-variable=rp_ClusterMode.WSSCurrentClusterMode
            DRA_rp_HMI_Ready_Status_HMI_ReadyStatus: accessed-variable=rp_HMI_Ready_Status.HMI_ReadyStatus
            DRA_rp_PowerTrainState_PowerTrain_Flag: accessed-variable=rp_PowerTrainState.PowerTrain_Flag
            DRA_rp_TT_PRND_blink_TIUpdateIndicatorStatus: accessed-variable=rp_TT_PRND_blink.TIUpdateIndicatorStatus
        data-send-points:
          5 x access:
            DWA_pp_ShiftPositionDisplay_ShiftPositionDisplay: accessed-variable=pp_ShiftPositionDisplay.ShiftPositionDisplay
            DWA_pp_Shift_ModeInd_ShiftModeIndicator: accessed-variable=pp_Shift_ModeInd.ShiftModeIndicator
            DWA_pp_Shift_Position_ShiftPosition: accessed-variable=pp_Shift_Position.ShiftPosition
            DWA_pp_Shiftpos_ShiftPosIndStatus_ShiftPosIndStatusData: accessed-variable=pp_Shiftpos_ShiftPosIndStatus.ShiftPosIndStatusData
            DWA_pp_Shiftpos_ePRNDL_Status_ShiftPos_Data: accessed-variable=pp_Shiftpos_ePRNDL_Status.ShiftPos_Data
        20 x sync call, all with timeout=0.0:
          OA_rp_CS_CanRx_RxCan_GetSignalValueU8Arr: operation=rp_CS_CanRx.RxCan_GetSignalValueU8Arr
          OA_rp_CS_CanRx_RxCan_SetSignalInitValue: operation=rp_CS_CanRx.RxCan_SetSignalInitValue
          OA_rp_CS_CanRx_RxCan_SetSignalInitValueU8Arr: operation=rp_CS_CanRx.RxCan_SetSignalInitValueU8Arr
          OA_rp_CS_CanRx_RxCan_SignalInvalidProcessingControl: operation=rp_CS_CanRx.RxCan_SignalInvalidProcessingControl
          OA_rp_CS_CanRx_RxCan_SignalMissingProcessingControl: operation=rp_CS_CanRx.RxCan_SignalMissingProcessingControl
          OA_rp_CS_CanRx_RxCan_SignalNRProcessingControl: operation=rp_CS_CanRx.RxCan_SignalNRProcessingControl
          OA_rp_CS_CanRx_RxCan_SignalGetJustRcvdStatus: operation=rp_CS_CanRx.RxCan_SignalGetJustRcvdStatus
          OA_rp_CS_CanRx_RxCan_SignalClearJustRcvdStatus: operation=rp_CS_CanRx.RxCan_SignalClearJustRcvdStatus
          OA_rp_CS_CanRx_RxCan_GetSignalValue: operation=rp_CS_CanRx.RxCan_GetSignalValue
          OA_rp_CS_RxCanMdl_RxCan_GetSignalValueU8Arr: operation=rp_CS_RxCanMdl.RxCan_GetSignalValueU8Arr
          OA_rp_CS_RxCanMdl_RxCan_SetSignalInitValue: operation=rp_CS_RxCanMdl.RxCan_SetSignalInitValue
          OA_rp_CS_RxCanMdl_RxCan_SetSignalInitValueU8Arr: operation=rp_CS_RxCanMdl.RxCan_SetSignalInitValueU8Arr
          OA_rp_CS_RxCanMdl_RxCan_SignalInvalidProcessingControl: operation=rp_CS_RxCanMdl.RxCan_SignalInvalidProcessingControl
          OA_rp_CS_RxCanMdl_RxCan_SignalMissingProcessingControl: operation=rp_CS_RxCanMdl.RxCan_SignalMissingProcessingControl
          OA_rp_CS_RxCanMdl_RxCan_SignalNRProcessingControl: operation=rp_CS_RxCanMdl.RxCan_SignalNRProcessingControl
          OA_rp_CS_RxCanMdl_RxCan_SignalGetJustRcvdStatus: operation=rp_CS_RxCanMdl.RxCan_SignalGetJustRcvdStatus
          OA_rp_CS_RxCanMdl_RxCan_SignalClearJustRcvdStatus: operation=rp_CS_RxCanMdl.RxCan_SignalClearJustRcvdStatus
          OA_rp_CS_RxCanMdl_RxCan_GetSignalValue: operation=rp_CS_RxCanMdl.RxCan_GetSignalValue
          OA_rp_Get_Variant_Cfg_Get_Variant_Config_State: operation=rp_Get_Variant_Cfg.Get_Variant_Config_State
          OA_rp_Variant_Status_GetVariant_Status: operation=rp_Variant_Status.GetVariant_Status
  11 x constant specification:
    Mdl_GearShiftPositionDisplayValue0: value-spec=Mdl_GearShiftPositionDisplayValue0:0
    Mdl_GearShiftModeIndicatorValue0: value-spec=Mdl_GearShiftModeIndicatorValue0:0
    Mdl_GearShiftPositionValue0: value-spec=Mdl_GearShiftPositionValue0:0
    Mdl_GearShiftPosIndStatusDataValue0: value-spec={short-label=Mdl_GearShiftPosIndStatusDataValue0, fields={short-label=Mdl_GearShiftPosIndStatusDataValue_0, fields=[Mdl_GearstatusValue_0:0, Mdl_GearstatusValue_1:0, Mdl_GearstatusValue_2:0, Mdl_GearstatusValue_3:0, Mdl_GearstatusValue_4:0, Mdl_GearstatusValue_5:0]}}
    Mdl_GearShiftPos_DataValue0: value-spec={short-label=Mdl_GearShiftPos_DataValue0, fields=[Mdl_GearShiftPos_DataValue_0:0, Mdl_GearShiftPos_DataValue_1:0, Mdl_GearShiftPos_DataValue_2:0, Mdl_GearShiftPos_DataValue_3:0, Mdl_GearShiftPos_DataValue_4:0]}
    Mdl_GearIgnitionSubstateValue0: value-spec=Mdl_GearIgnitionSubstateValue0:0
    Mdl_GearWSSCurrentVehicleStateValue0: value-spec=Mdl_GearWSSCurrentVehicleStateValue0:0
    Mdl_GearWSSCurrentClusterModeValue0: value-spec=Mdl_GearWSSCurrentClusterModeValue0:0
    Mdl_GearHMI_ReadyStatusValue0: value-spec=Mdl_GearHMI_ReadyStatusValue0:0
    Mdl_GearPowerTrain_FlagValue0: value-spec=Mdl_GearPowerTrain_FlagValue0:0
    Mdl_GearTIUpdateIndicatorStatusValue0: value-spec=Mdl_GearTIUpdateIndicatorStatusValue0:0
  swc implementation IMPL_Mdl_Gear: programming-language=C, behavior=IB_Mdl_Gear
    code-descriptors:
      code CodeDescriptor
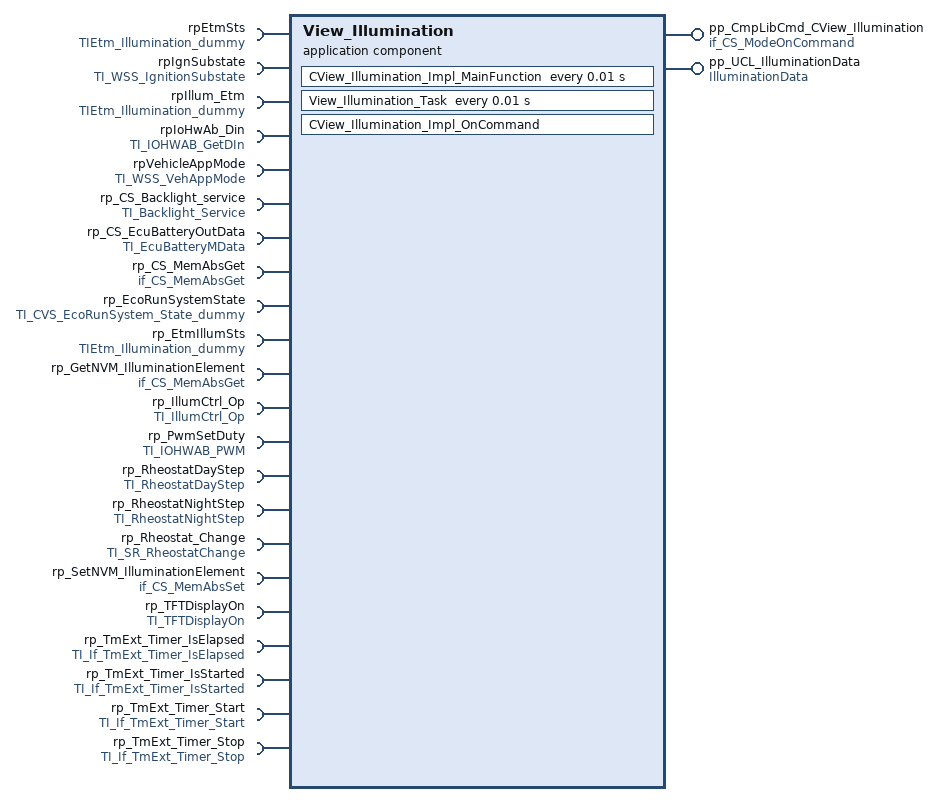
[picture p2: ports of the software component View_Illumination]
  application sw component type View_Illumination
    provide port pp_CmpLibCmd_CView_Illumination: server-com-spec{operation=Impl_OnCommand, queue-length=1}, provided-interface=if_CS_ModeOnCommand
    provide port pp_UCL_IlluminationData: nonqueued-sender-com-spec{data-element=IlluminationDataData, init-value=constant-reference=View_IlluminationIlluminationDataDataValue0}, provided-interface=IlluminationData
    22 x require port:
      rpEtmSts: nonqueued-receiver-com-spec{data-element=IllumStatus, init-value=constant-reference=View_IlluminationIllumStatusValue0}, required-interface=TIEtm_Illumination_dummy
      rpIgnSubstate: nonqueued-receiver-com-spec{data-element=IgnitionSubstate, init-value=constant-reference=View_IlluminationIgnitionSubstateValue0}, required-interface=TI_WSS_IgnitionSubstate
      rpIllum_Etm: nonqueued-receiver-com-spec{data-element=IllumStatus, init-value=constant-reference=View_IlluminationIllumStatusValue0}, required-interface=TIEtm_Illumination_dummy
      rpIoHwAb_Din: required-interface=TI_IOHWAB_GetDIn
      rpVehicleAppMode: nonqueued-receiver-com-spec{data-element=WSSCurrentVehicleState, init-value=constant-reference=View_IlluminationWSSCurrentVehicleStateValue0}, required-interface=TI_WSS_VehAppMode
      rp_CS_Backlight_service: required-interface=TI_Backlight_Service
      rp_CS_EcuBatteryOutData: required-interface=TI_EcuBatteryMData
      rp_CS_MemAbsGet: required-interface=if_CS_MemAbsGet
      rp_EcoRunSystemState: nonqueued-receiver-com-spec{data-element=EcoRunSystem_Flag, init-value=constant-reference=View_IlluminationEcoRunSystem_FlagValue0}, required-interface=TI_CVS_EcoRunSystem_State_dummy
      rp_EtmIllumSts: nonqueued-receiver-com-spec{data-element=IllumStatus, init-value=constant-reference=View_IlluminationIllumStatusValue0}, required-interface=TIEtm_Illumination_dummy
      rp_GetNVM_IlluminationElement: required-interface=if_CS_MemAbsGet
      rp_IllumCtrl_Op: nonqueued-receiver-com-spec{data-element=IllumCtrl_Op_Data, init-value=constant-reference=View_IlluminationIllumCtrl_Op_DataValue0}, required-interface=TI_IllumCtrl_Op
      rp_PwmSetDuty: required-interface=TI_IOHWAB_PWM
      rp_RheostatDayStep: nonqueued-receiver-com-spec{data-element=RheostatDayStep, init-value=constant-reference=View_IlluminationRheostatDayStepValue0}, required-interface=TI_RheostatDayStep
      rp_RheostatNightStep: nonqueued-receiver-com-spec{data-element=RheostatNightStep, init-value=constant-reference=View_IlluminationRheostatNightStepValue0}, required-interface=TI_RheostatNightStep
      rp_Rheostat_Change: nonqueued-receiver-com-spec{data-element=RheoUpdateVal, init-value=constant-reference=View_IlluminationRheoUpdateValValue0}, required-interface=TI_SR_RheostatChange
      rp_SetNVM_IlluminationElement: required-interface=if_CS_MemAbsSet
      rp_TFTDisplayOn: nonqueued-receiver-com-spec{data-element=TFTDisplayOn, init-value=constant-reference=View_IlluminationTFTDisplayOnValue0}, required-interface=TI_TFTDisplayOn
      rp_TmExt_Timer_IsElapsed: required-interface=TI_If_TmExt_Timer_IsElapsed
      rp_TmExt_Timer_IsStarted: required-interface=TI_If_TmExt_Timer_IsStarted
      rp_TmExt_Timer_Start: required-interface=TI_If_TmExt_Timer_Start
      rp_TmExt_Timer_Stop: required-interface=TI_If_TmExt_Timer_Stop
    behavior IB_View_Illumination
      timing event TECView_Illumination_Impl_MainFunction: start-on-event=CView_Illumination_Impl_MainFunction, period=0.01
      operation invoked event OIE_pp_CmpLibCmd_CView_Illumination_CView_Illumination_Impl_OnCommandTrigByImpl_OnCommand: start-on-event=CView_Illumination_Impl_OnCommand, operation=pp_CmpLibCmd_CView_Illumination.Impl_OnCommand
      timing event TEView_Illumination_Task: start-on-event=View_Illumination_Task, period=0.01
      port-api-options:
        enable-take-address=false, indirect-api=false, port=pp_CmpLibCmd_CView_Illumination
        enable-take-address=false, indirect-api=false, port=pp_UCL_IlluminationData
        enable-take-address=false, indirect-api=false, port=View_Illumination/rpEtmSts
        enable-take-address=false, indirect-api=false, port=View_Illumination/rpIgnSubstate
        enable-take-address=false, indirect-api=false, port=View_Illumination/rpIllum_Etm
        enable-take-address=false, indirect-api=false, port=View_Illumination/rpIoHwAb_Din
        enable-take-address=false, indirect-api=false, port=View_Illumination/rpVehicleAppMode
        enable-take-address=false, indirect-api=false, port=View_Illumination/rp_CS_Backlight_service
        enable-take-address=false, indirect-api=false, port=View_Illumination/rp_CS_EcuBatteryOutData
        enable-take-address=false, indirect-api=false, port=View_Illumination/rp_CS_MemAbsGet
        enable-take-address=false, indirect-api=false, port=View_Illumination/rp_EcoRunSystemState
        enable-take-address=false, indirect-api=false, port=View_Illumination/rp_EtmIllumSts
        enable-take-address=false, indirect-api=false, port=View_Illumination/rp_GetNVM_IlluminationElement
        enable-take-address=false, indirect-api=false, port=rp_IllumCtrl_Op
        enable-take-address=false, indirect-api=false, port=View_Illumination/rp_PwmSetDuty
        enable-take-address=false, indirect-api=false, port=View_Illumination/rp_RheostatDayStep
        enable-take-address=false, indirect-api=false, port=View_Illumination/rp_RheostatNightStep
        enable-take-address=false, indirect-api=false, port=View_Illumination/rp_Rheostat_Change
        enable-take-address=false, indirect-api=false, port=View_Illumination/rp_SetNVM_IlluminationElement
        enable-take-address=false, indirect-api=false, port=View_Illumination/rp_TFTDisplayOn
        enable-take-address=false, indirect-api=false, port=View_Illumination/rp_TmExt_Timer_IsElapsed
        enable-take-address=false, indirect-api=false, port=View_Illumination/rp_TmExt_Timer_IsStarted
        enable-take-address=false, indirect-api=false, port=View_Illumination/rp_TmExt_Timer_Start
        enable-take-address=false, indirect-api=false, port=View_Illumination/rp_TmExt_Timer_Stop
      runnable CView_Illumination_Impl_MainFunction: can-be-invoked-concurrently=true
        data-receive-point-by-arguments:
          11 x access:
            DRA_rpEtmSts_IllumStatus: accessed-variable=rpEtmSts.IllumStatus
            DRA_rpIgnSubstate_IgnitionSubstate: accessed-variable=rpIgnSubstate.IgnitionSubstate
            DRA_rpIllum_Etm_IllumStatus: accessed-variable=rpIllum_Etm.IllumStatus
            DRA_rpVehicleAppMode_WSSCurrentVehicleState: accessed-variable=rpVehicleAppMode.WSSCurrentVehicleState
            DRA_rp_EcoRunSystemState_EcoRunSystem_Flag: accessed-variable=rp_EcoRunSystemState.EcoRunSystem_Flag
            DRA_rp_EtmIllumSts_IllumStatus: accessed-variable=rp_EtmIllumSts.IllumStatus
            DRA_rp_IllumCtrl_Op_IllumCtrl_Op_Data: accessed-variable=rp_IllumCtrl_Op.IllumCtrl_Op_Data
            DRA_rp_RheostatDayStep_RheostatDayStep: accessed-variable=rp_RheostatDayStep.RheostatDayStep
            DRA_rp_RheostatNightStep_RheostatNightStep: accessed-variable=rp_RheostatNightStep.RheostatNightStep
            DRA_rp_Rheostat_Change_RheoUpdateVal: accessed-variable=rp_Rheostat_Change.RheoUpdateVal
            DRA_rp_TFTDisplayOn_TFTDisplayOn: accessed-variable=rp_TFTDisplayOn.TFTDisplayOn
        data-send-points:
          access DWA_pp_UCL_IlluminationData_IlluminationDataData: accessed-variable=pp_UCL_IlluminationData.IlluminationDataData
        298 x sync call, all with timeout=0.0:
          OA_rpIoHwAb_Din_GetAsyncRawInput: operation=rpIoHwAb_Din.GetAsyncRawInput
          OA_rpIoHwAb_Din_GetProcessedInput: operation=rpIoHwAb_Din.GetProcessedInput
          OA_rpIoHwAb_Din_GetSyncRawInput: operation=rpIoHwAb_Din.GetSyncRawInput
          OA_rpIoHwAb_Din_GetInputGroup: operation=rpIoHwAb_Din.GetInputGroup
          OA_rp_CS_Backlight_service_SetBrightnessValue: operation=rp_CS_Backlight_service.SetBrightnessValue
          OA_rp_CS_Backlight_service_GetBrightnessValue: operation=rp_CS_Backlight_service.GetBrightnessValue
          OA_rp_CS_Backlight_service_GetThermalValue: operation=rp_CS_Backlight_service.GetThermalValue
          OA_rp_CS_EcuBatteryOutData_EcuBatteryM_GetChannelStatus: operation=rp_CS_EcuBatteryOutData.EcuBatteryM_GetChannelStatus
          OA_rp_CS_EcuBatteryOutData_EcuBatteryM_GetDIOStatus: operation=rp_CS_EcuBatteryOutData.EcuBatteryM_GetDIOStatus
          OA_rp_CS_MemAbsGet_Get_BsShare_SwUpdReflash_Element: operation=rp_CS_MemAbsGet.Get_BsShare_SwUpdReflash_Element
          OA_rp_CS_MemAbsGet_Get_BsShare_SwUpdFotaMode_Element: operation=rp_CS_MemAbsGet.Get_BsShare_SwUpdFotaMode_Element
          OA_rp_CS_MemAbsGet_Get_BsShare_SwUpdFotaFinPrint_Element: operation=rp_CS_MemAbsGet.Get_BsShare_SwUpdFotaFinPrint_Element
          OA_rp_CS_MemAbsGet_Get_BsShare_SwUpdFotaStatus_Element: operation=rp_CS_MemAbsGet.Get_BsShare_SwUpdFotaStatus_Element
          OA_rp_CS_MemAbsGet_Get_BsShare_SwUpdFotadecrypt_Element: operation=rp_CS_MemAbsGet.Get_BsShare_SwUpdFotadecrypt_Element
          OA_rp_CS_MemAbsGet_Get_BsShare_EcuPartNumber_Element: operation=rp_CS_MemAbsGet.Get_BsShare_EcuPartNumber_Element
          OA_rp_CS_MemAbsGet_Get_BsShare_VisteonPartNumber: operation=rp_CS_MemAbsGet.Get_BsShare_VisteonPartNumber
          OA_rp_CS_MemAbsGet_Get_BsShare_VisteonPCBPartNumber: operation=rp_CS_MemAbsGet.Get_BsShare_VisteonPCBPartNumber
          OA_rp_CS_MemAbsGet_Get_BsShare_ProductSerialNumber: operation=rp_CS_MemAbsGet.Get_BsShare_ProductSerialNumber
          OA_rp_CS_MemAbsGet_Get_BsShare_PCBSerialNumber: operation=rp_CS_MemAbsGet.Get_BsShare_PCBSerialNumber
          OA_rp_CS_MemAbsGet_Get_BsShare_SMTManufacturingDate: operation=rp_CS_MemAbsGet.Get_BsShare_SMTManufacturingDate
          OA_rp_CS_MemAbsGet_Get_BsShare_AssemblyManufacturingDate: operation=rp_CS_MemAbsGet.Get_BsShare_AssemblyManufacturingDate
          OA_rp_CS_MemAbsGet_Get_BsShare_SMTPlantNumber: operation=rp_CS_MemAbsGet.Get_BsShare_SMTPlantNumber
          OA_rp_CS_MemAbsGet_Get_BsShare_AssemblyPlantNumber: operation=rp_CS_MemAbsGet.Get_BsShare_AssemblyPlantNumber
          OA_rp_CS_MemAbsGet_Get_BsShare_HWModification: operation=rp_CS_MemAbsGet.Get_BsShare_HWModification
          OA_rp_CS_MemAbsGet_Get_BsShare_VisMeet_Element: operation=rp_CS_MemAbsGet.Get_BsShare_VisMeet_Element
          OA_rp_CS_MemAbsGet_Get_BsShare_VisMeet_EOLEntry_Element: operation=rp_CS_MemAbsGet.Get_BsShare_VisMeet_EOLEntry_Element
          OA_rp_CS_MemAbsGet_Get_BsShare_VehicleConfig_Element: operation=rp_CS_MemAbsGet.Get_BsShare_VehicleConfig_Element
          OA_rp_CS_MemAbsGet_Get_BsConst_SpeedoGauge_Element: operation=rp_CS_MemAbsGet.Get_BsConst_SpeedoGauge_Element
          OA_rp_CS_MemAbsGet_Get_BsConst_TachoGauge_Element: operation=rp_CS_MemAbsGet.Get_BsConst_TachoGauge_Element
          OA_rp_CS_MemAbsGet_Get_BsConst_FuelGauge_Element: operation=rp_CS_MemAbsGet.Get_BsConst_FuelGauge_Element
          OA_rp_CS_MemAbsGet_Get_BsConst_TempGauge_Element: operation=rp_CS_MemAbsGet.Get_BsConst_TempGauge_Element
          OA_rp_CS_MemAbsGet_Get_BsConst_PowerGauge_Element: operation=rp_CS_MemAbsGet.Get_BsConst_PowerGauge_Element
          OA_rp_CS_MemAbsGet_Get_BsConst_OilGauge_Element: operation=rp_CS_MemAbsGet.Get_BsConst_OilGauge_Element
          OA_rp_CS_MemAbsGet_Get_BsConst_TripComputer_Element: operation=rp_CS_MemAbsGet.Get_BsConst_TripComputer_Element
          OA_rp_CS_MemAbsGet_Get_BsConst_Compensation_Line_Slope_m: operation=rp_CS_MemAbsGet.Get_BsConst_Compensation_Line_Slope_m
          OA_rp_CS_MemAbsGet_Get_BsConst_Compensation_Line_Shift_b: operation=rp_CS_MemAbsGet.Get_BsConst_Compensation_Line_Shift_b
          OA_rp_CS_MemAbsGet_Get_BsConst_Lookup_Curve_HotSpot_Coef_X: operation=rp_CS_MemAbsGet.Get_BsConst_Lookup_Curve_HotSpot_Coef_X
          OA_rp_CS_MemAbsGet_Get_BsConst_Lookup_Curve_HotSpot_Coef_Y: operation=rp_CS_MemAbsGet.Get_BsConst_Lookup_Curve_HotSpot_Coef_Y
          OA_rp_CS_MemAbsGet_Get_BsConst_Temp_Threshold_Hysteresis_Derating: operation=rp_CS_MemAbsGet.Get_BsConst_Temp_Threshold_Hysteresis_Derating
          OA_rp_CS_MemAbsGet_Get_BsConst_Derating_Backlight_Disable: operation=rp_CS_MemAbsGet.Get_BsConst_Derating_Backlight_Disable
          OA_rp_CS_MemAbsGet_Get_BsConst_Temperature_Sensor_Conv: operation=rp_CS_MemAbsGet.Get_BsConst_Temperature_Sensor_Conv
          OA_rp_CS_MemAbsGet_Get_BsConst_PCB_Temperature_Sensor_Conv: operation=rp_CS_MemAbsGet.Get_BsConst_PCB_Temperature_Sensor_Conv
          OA_rp_CS_MemAbsGet_Get_BsConst_Display_Illum_Max_Level: operation=rp_CS_MemAbsGet.Get_BsConst_Display_Illum_Max_Level
          OA_rp_CS_MemAbsGet_Get_BsConst_PWM_boost_bypass_duty: operation=rp_CS_MemAbsGet.Get_BsConst_PWM_boost_bypass_duty
          OA_rp_CS_MemAbsGet_Get_BsConst_BsConst_Illumination_ReservedByte: operation=rp_CS_MemAbsGet.Get_BsConst_BsConst_Illumination_ReservedByte
          OA_rp_CS_MemAbsGet_Get_BsConst_Compensation_Line_Slope_m_SafeCopy1: operation=rp_CS_MemAbsGet.Get_BsConst_Compensation_Line_Slope_m_SafeCopy1
          OA_rp_CS_MemAbsGet_Get_BsConst_Compensation_Line_Shift_b_SafeCopy1: operation=rp_CS_MemAbsGet.Get_BsConst_Compensation_Line_Shift_b_SafeCopy1
          OA_rp_CS_MemAbsGet_Get_BsConst_Lookup_Curve_HotSpot_Coef_X_SafeCopy1: operation=rp_CS_MemAbsGet.Get_BsConst_Lookup_Curve_HotSpot_Coef_X_SafeCopy1
          OA_rp_CS_MemAbsGet_Get_BsConst_Lookup_Curve_HotSpot_Coef_Y_SafeCopy1: operation=rp_CS_MemAbsGet.Get_BsConst_Lookup_Curve_HotSpot_Coef_Y_SafeCopy1
          OA_rp_CS_MemAbsGet_Get_BsConst_Temp_Threshold_Hysteresis_Derating_SafeCopy1: operation=rp_CS_MemAbsGet.Get_BsConst_Temp_Threshold_Hysteresis_Derating_SafeCopy1
          OA_rp_CS_MemAbsGet_Get_BsConst_Derating_Backlight_Disable_SafeCopy1: operation=rp_CS_MemAbsGet.Get_BsConst_Derating_Backlight_Disable_SafeCopy1
          OA_rp_CS_MemAbsGet_Get_BsConst_Temperature_Sensor_Conv_SafeCopy1: operation=rp_CS_MemAbsGet.Get_BsConst_Temperature_Sensor_Conv_SafeCopy1
          OA_rp_CS_MemAbsGet_Get_BsConst_PCB_Temperature_Sensor_Conv_SafeCopy1: operation=rp_CS_MemAbsGet.Get_BsConst_PCB_Temperature_Sensor_Conv_SafeCopy1
          OA_rp_CS_MemAbsGet_Get_BsConst_Display_Illum_Max_Level_SafeCopy1: operation=rp_CS_MemAbsGet.Get_BsConst_Display_Illum_Max_Level_SafeCopy1
          OA_rp_CS_MemAbsGet_Get_BsConst_PWM_boost_bypass_duty_SafeCopy1: operation=rp_CS_MemAbsGet.Get_BsConst_PWM_boost_bypass_duty_SafeCopy1
          OA_rp_CS_MemAbsGet_Get_BsConst_BsConst_Illumination_ReservedByte_SafeCopy1: operation=rp_CS_MemAbsGet.Get_BsConst_BsConst_Illumination_ReservedByte_SafeCopy1
          OA_rp_CS_MemAbsGet_Get_BsConst_Compensation_Line_Slope_m_SafeCopy2: operation=rp_CS_MemAbsGet.Get_BsConst_Compensation_Line_Slope_m_SafeCopy2
          OA_rp_CS_MemAbsGet_Get_BsConst_Compensation_Line_Shift_b_SafeCopy2: operation=rp_CS_MemAbsGet.Get_BsConst_Compensation_Line_Shift_b_SafeCopy2
          OA_rp_CS_MemAbsGet_Get_BsConst_Lookup_Curve_HotSpot_Coef_X_SafeCopy2: operation=rp_CS_MemAbsGet.Get_BsConst_Lookup_Curve_HotSpot_Coef_X_SafeCopy2
          OA_rp_CS_MemAbsGet_Get_BsConst_Lookup_Curve_HotSpot_Coef_Y_SafeCopy2: operation=rp_CS_MemAbsGet.Get_BsConst_Lookup_Curve_HotSpot_Coef_Y_SafeCopy2
          OA_rp_CS_MemAbsGet_Get_BsConst_Temp_Threshold_Hysteresis_Derating_SafeCopy2: operation=rp_CS_MemAbsGet.Get_BsConst_Temp_Threshold_Hysteresis_Derating_SafeCopy2
          OA_rp_CS_MemAbsGet_Get_BsConst_Derating_Backlight_Disable_SafeCopy2: operation=rp_CS_MemAbsGet.Get_BsConst_Derating_Backlight_Disable_SafeCopy2
          OA_rp_CS_MemAbsGet_Get_BsConst_Temperature_Sensor_Conv_SafeCopy2: operation=rp_CS_MemAbsGet.Get_BsConst_Temperature_Sensor_Conv_SafeCopy2
          OA_rp_CS_MemAbsGet_Get_BsConst_PCB_Temperature_Sensor_Conv_SafeCopy2: operation=rp_CS_MemAbsGet.Get_BsConst_PCB_Temperature_Sensor_Conv_SafeCopy2
          OA_rp_CS_MemAbsGet_Get_BsConst_Display_Illum_Max_Level_SafeCopy2: operation=rp_CS_MemAbsGet.Get_BsConst_Display_Illum_Max_Level_SafeCopy2
          OA_rp_CS_MemAbsGet_Get_BsConst_PWM_boost_bypass_duty_SafeCopy2: operation=rp_CS_MemAbsGet.Get_BsConst_PWM_boost_bypass_duty_SafeCopy2
          OA_rp_CS_MemAbsGet_Get_BsConst_BsConst_Illumination_ReservedByte_SafeCopy2: operation=rp_CS_MemAbsGet.Get_BsConst_BsConst_Illumination_ReservedByte_SafeCopy2
          OA_rp_CS_MemAbsGet_Get_BsConst_Audio_Element: operation=rp_CS_MemAbsGet.Get_BsConst_Audio_Element
          OA_rp_CS_MemAbsGet_Get_BsConst_Warning_Element: operation=rp_CS_MemAbsGet.Get_BsConst_Warning_Element
          OA_rp_CS_MemAbsGet_Get_BsConst_RealTimeClock_Element: operation=rp_CS_MemAbsGet.Get_BsConst_RealTimeClock_Element
          OA_rp_CS_MemAbsGet_Get_BsConst_Communication_Element: operation=rp_CS_MemAbsGet.Get_BsConst_Communication_Element
          OA_rp_CS_MemAbsGet_Get_BsConst_Power_Element: operation=rp_CS_MemAbsGet.Get_BsConst_Power_Element
          OA_rp_CS_MemAbsGet_Get_BsConst_ServiceReminder_Element: operation=rp_CS_MemAbsGet.Get_BsConst_ServiceReminder_Element
          OA_rp_CS_MemAbsGet_Get_BsConst_EngOffTimer_Element: operation=rp_CS_MemAbsGet.Get_BsConst_EngOffTimer_Element
          OA_rp_CS_MemAbsGet_Get_BsCys_Certicificate_Element: operation=rp_CS_MemAbsGet.Get_BsCys_Certicificate_Element
          OA_rp_CS_MemAbsGet_Get_RefCys_Certicificate_Element: operation=rp_CS_MemAbsGet.Get_RefCys_Certicificate_Element
          OA_rp_CS_MemAbsGet_Get_RefCys_Certicificate1_Element: operation=rp_CS_MemAbsGet.Get_RefCys_Certicificate1_Element
          OA_rp_CS_MemAbsGet_Get_BsRt_Odometer_Element: operation=rp_CS_MemAbsGet.Get_BsRt_Odometer_Element
          OA_rp_CS_MemAbsGet_Get_BsRt_SpeedoGauge_Element: operation=rp_CS_MemAbsGet.Get_BsRt_SpeedoGauge_Element
          OA_rp_CS_MemAbsGet_Get_BsRt_TachoGauge_Element: operation=rp_CS_MemAbsGet.Get_BsRt_TachoGauge_Element
          OA_rp_CS_MemAbsGet_Get_BsRt_FuelGauge_Element: operation=rp_CS_MemAbsGet.Get_BsRt_FuelGauge_Element
          OA_rp_CS_MemAbsGet_Get_BsRt_TempGauge_Element: operation=rp_CS_MemAbsGet.Get_BsRt_TempGauge_Element
          OA_rp_CS_MemAbsGet_Get_BsRt_PowerGauge_Element: operation=rp_CS_MemAbsGet.Get_BsRt_PowerGauge_Element
          OA_rp_CS_MemAbsGet_Get_BsRt_OilGauge_Element: operation=rp_CS_MemAbsGet.Get_BsRt_OilGauge_Element
          OA_rp_CS_MemAbsGet_Get_BsRt_TripComputer_Element: operation=rp_CS_MemAbsGet.Get_BsRt_TripComputer_Element
          OA_rp_CS_MemAbsGet_Get_BsRt_Warning_Element: operation=rp_CS_MemAbsGet.Get_BsRt_Warning_Element
          OA_rp_CS_MemAbsGet_Get_BsRt_RealTimeClock_Element: operation=rp_CS_MemAbsGet.Get_BsRt_RealTimeClock_Element
          OA_rp_CS_MemAbsGet_Get_BsRt_Personalization_Element: operation=rp_CS_MemAbsGet.Get_BsRt_Personalization_Element
          OA_rp_CS_MemAbsGet_Get_BsRt_Illumination_Element: operation=rp_CS_MemAbsGet.Get_BsRt_Illumination_Element
          OA_rp_CS_MemAbsGet_Get_BsRt_CusDlt_Element: operation=rp_CS_MemAbsGet.Get_BsRt_CusDlt_Element
          OA_rp_CS_MemAbsGet_Get_BsReten_Odometer_Element: operation=rp_CS_MemAbsGet.Get_BsReten_Odometer_Element
          OA_rp_CS_MemAbsGet_Get_BsReten_Gauges_Element: operation=rp_CS_MemAbsGet.Get_BsReten_Gauges_Element
          OA_rp_CS_MemAbsGet_Get_BsReten_Tripcomputer_Element: operation=rp_CS_MemAbsGet.Get_BsReten_Tripcomputer_Element
          OA_rp_CS_MemAbsGet_Get_BsReten_Illumination_Element: operation=rp_CS_MemAbsGet.Get_BsReten_Illumination_Element
          OA_rp_CS_MemAbsGet_Get_BsReten_Audio_Element: operation=rp_CS_MemAbsGet.Get_BsReten_Audio_Element
          OA_rp_CS_MemAbsGet_Get_BsReten_Warning_Element: operation=rp_CS_MemAbsGet.Get_BsReten_Warning_Element
          OA_rp_CS_MemAbsGet_Get_BsReten_RealTimeClock_Element: operation=rp_CS_MemAbsGet.Get_BsReten_RealTimeClock_Element
          OA_rp_CS_MemAbsGet_Get_BsReten_Communication_Element: operation=rp_CS_MemAbsGet.Get_BsReten_Communication_Element
          OA_rp_CS_MemAbsGet_Get_BsReten_Personalization_Element: operation=rp_CS_MemAbsGet.Get_BsReten_Personalization_Element
          OA_rp_CS_MemAbsGet_Get_BsReten_Power_Element: operation=rp_CS_MemAbsGet.Get_BsReten_Power_Element
          OA_rp_CS_MemAbsGet_Get_BsReten_Display_Element: operation=rp_CS_MemAbsGet.Get_BsReten_Display_Element
          OA_rp_CS_MemAbsGet_Get_BsDiag_ErrorRecord_Element: operation=rp_CS_MemAbsGet.Get_BsDiag_ErrorRecord_Element
          OA_rp_CS_MemAbsGet_Get_BsDiag_Dtc_Element: operation=rp_CS_MemAbsGet.Get_BsDiag_Dtc_Element
          OA_rp_GetNVM_IlluminationElement_Get_BsShare_SwUpdReflash_Element: operation=rp_GetNVM_IlluminationElement.Get_BsShare_SwUpdReflash_Element
          OA_rp_GetNVM_IlluminationElement_Get_BsShare_SwUpdFotaMode_Element: operation=rp_GetNVM_IlluminationElement.Get_BsShare_SwUpdFotaMode_Element
          OA_rp_GetNVM_IlluminationElement_Get_BsShare_SwUpdFotaFinPrint_Element: operation=rp_GetNVM_IlluminationElement.Get_BsShare_SwUpdFotaFinPrint_Element
          OA_rp_GetNVM_IlluminationElement_Get_BsShare_SwUpdFotaStatus_Element: operation=rp_GetNVM_IlluminationElement.Get_BsShare_SwUpdFotaStatus_Element
          OA_rp_GetNVM_IlluminationElement_Get_BsShare_SwUpdFotadecrypt_Element: operation=rp_GetNVM_IlluminationElement.Get_BsShare_SwUpdFotadecrypt_Element
          OA_rp_GetNVM_IlluminationElement_Get_BsShare_EcuPartNumber_Element: operation=rp_GetNVM_IlluminationElement.Get_BsShare_EcuPartNumber_Element
          OA_rp_GetNVM_IlluminationElement_Get_BsShare_VisteonPartNumber: operation=rp_GetNVM_IlluminationElement.Get_BsShare_VisteonPartNumber
          OA_rp_GetNVM_IlluminationElement_Get_BsShare_VisteonPCBPartNumber: operation=rp_GetNVM_IlluminationElement.Get_BsShare_VisteonPCBPartNumber
          OA_rp_GetNVM_IlluminationElement_Get_BsShare_ProductSerialNumber: operation=rp_GetNVM_IlluminationElement.Get_BsShare_ProductSerialNumber
          OA_rp_GetNVM_IlluminationElement_Get_BsShare_PCBSerialNumber: operation=rp_GetNVM_IlluminationElement.Get_BsShare_PCBSerialNumber
          OA_rp_GetNVM_IlluminationElement_Get_BsShare_SMTManufacturingDate: operation=rp_GetNVM_IlluminationElement.Get_BsShare_SMTManufacturingDate
          OA_rp_GetNVM_IlluminationElement_Get_BsShare_AssemblyManufacturingDate: operation=rp_GetNVM_IlluminationElement.Get_BsShare_AssemblyManufacturingDate
          OA_rp_GetNVM_IlluminationElement_Get_BsShare_SMTPlantNumber: operation=rp_GetNVM_IlluminationElement.Get_BsShare_SMTPlantNumber
          OA_rp_GetNVM_IlluminationElement_Get_BsShare_AssemblyPlantNumber: operation=rp_GetNVM_IlluminationElement.Get_BsShare_AssemblyPlantNumber
          OA_rp_GetNVM_IlluminationElement_Get_BsShare_HWModification: operation=rp_GetNVM_IlluminationElement.Get_BsShare_HWModification
          OA_rp_GetNVM_IlluminationElement_Get_BsShare_VisMeet_Element: operation=rp_GetNVM_IlluminationElement.Get_BsShare_VisMeet_Element
          OA_rp_GetNVM_IlluminationElement_Get_BsShare_VisMeet_EOLEntry_Element: operation=rp_GetNVM_IlluminationElement.Get_BsShare_VisMeet_EOLEntry_Element
          OA_rp_GetNVM_IlluminationElement_Get_BsShare_VehicleConfig_Element: operation=rp_GetNVM_IlluminationElement.Get_BsShare_VehicleConfig_Element
          OA_rp_GetNVM_IlluminationElement_Get_BsConst_SpeedoGauge_Element: operation=rp_GetNVM_IlluminationElement.Get_BsConst_SpeedoGauge_Element
          OA_rp_GetNVM_IlluminationElement_Get_BsConst_TachoGauge_Element: operation=rp_GetNVM_IlluminationElement.Get_BsConst_TachoGauge_Element
          OA_rp_GetNVM_IlluminationElement_Get_BsConst_FuelGauge_Element: operation=rp_GetNVM_IlluminationElement.Get_BsConst_FuelGauge_Element
          OA_rp_GetNVM_IlluminationElement_Get_BsConst_TempGauge_Element: operation=rp_GetNVM_IlluminationElement.Get_BsConst_TempGauge_Element
          OA_rp_GetNVM_IlluminationElement_Get_BsConst_PowerGauge_Element: operation=rp_GetNVM_IlluminationElement.Get_BsConst_PowerGauge_Element
          OA_rp_GetNVM_IlluminationElement_Get_BsConst_OilGauge_Element: operation=rp_GetNVM_IlluminationElement.Get_BsConst_OilGauge_Element
          OA_rp_GetNVM_IlluminationElement_Get_BsConst_TripComputer_Element: operation=rp_GetNVM_IlluminationElement.Get_BsConst_TripComputer_Element
          OA_rp_GetNVM_IlluminationElement_Get_BsConst_Compensation_Line_Slope_m: operation=rp_GetNVM_IlluminationElement.Get_BsConst_Compensation_Line_Slope_m
          OA_rp_GetNVM_IlluminationElement_Get_BsConst_Compensation_Line_Shift_b: operation=rp_GetNVM_IlluminationElement.Get_BsConst_Compensation_Line_Shift_b
          OA_rp_GetNVM_IlluminationElement_Get_BsConst_Lookup_Curve_HotSpot_Coef_X: operation=rp_GetNVM_IlluminationElement.Get_BsConst_Lookup_Curve_HotSpot_Coef_X
          OA_rp_GetNVM_IlluminationElement_Get_BsConst_Lookup_Curve_HotSpot_Coef_Y: operation=rp_GetNVM_IlluminationElement.Get_BsConst_Lookup_Curve_HotSpot_Coef_Y
          OA_rp_GetNVM_IlluminationElement_Get_BsConst_Temp_Threshold_Hysteresis_Derating: operation=rp_GetNVM_IlluminationElement.Get_BsConst_Temp_Threshold_Hysteresis_Derating
          OA_rp_GetNVM_IlluminationElement_Get_BsConst_Derating_Backlight_Disable: operation=rp_GetNVM_IlluminationElement.Get_BsConst_Derating_Backlight_Disable
          OA_rp_GetNVM_IlluminationElement_Get_BsConst_Temperature_Sensor_Conv: operation=rp_GetNVM_IlluminationElement.Get_BsConst_Temperature_Sensor_Conv
          OA_rp_GetNVM_IlluminationElement_Get_BsConst_PCB_Temperature_Sensor_Conv: operation=rp_GetNVM_IlluminationElement.Get_BsConst_PCB_Temperature_Sensor_Conv
          OA_rp_GetNVM_IlluminationElement_Get_BsConst_Display_Illum_Max_Level: operation=rp_GetNVM_IlluminationElement.Get_BsConst_Display_Illum_Max_Level
          OA_rp_GetNVM_IlluminationElement_Get_BsConst_PWM_boost_bypass_duty: operation=rp_GetNVM_IlluminationElement.Get_BsConst_PWM_boost_bypass_duty
          OA_rp_GetNVM_IlluminationElement_Get_BsConst_BsConst_Illumination_ReservedByte: operation=rp_GetNVM_IlluminationElement.Get_BsConst_BsConst_Illumination_ReservedByte
          OA_rp_GetNVM_IlluminationElement_Get_BsConst_Compensation_Line_Slope_m_SafeCopy1: operation=rp_GetNVM_IlluminationElement.Get_BsConst_Compensation_Line_Slope_m_SafeCopy1
          OA_rp_GetNVM_IlluminationElement_Get_BsConst_Compensation_Line_Shift_b_SafeCopy1: operation=rp_GetNVM_IlluminationElement.Get_BsConst_Compensation_Line_Shift_b_SafeCopy1
          OA_rp_GetNVM_IlluminationElement_Get_BsConst_Lookup_Curve_HotSpot_Coef_X_SafeCopy1: operation=rp_GetNVM_IlluminationElement.Get_BsConst_Lookup_Curve_HotSpot_Coef_X_SafeCopy1
          OA_rp_GetNVM_IlluminationElement_Get_BsConst_Lookup_Curve_HotSpot_Coef_Y_SafeCopy1: operation=rp_GetNVM_IlluminationElement.Get_BsConst_Lookup_Curve_HotSpot_Coef_Y_SafeCopy1
          OA_rp_GetNVM_IlluminationElement_Get_BsConst_Temp_Threshold_Hysteresis_Derating_SafeCopy1: operation=rp_GetNVM_IlluminationElement.Get_BsConst_Temp_Threshold_Hysteresis_Derating_SafeCopy1
          OA_rp_GetNVM_IlluminationElement_Get_BsConst_Derating_Backlight_Disable_SafeCopy1: operation=rp_GetNVM_IlluminationElement.Get_BsConst_Derating_Backlight_Disable_SafeCopy1
          OA_rp_GetNVM_IlluminationElement_Get_BsConst_Temperature_Sensor_Conv_SafeCopy1: operation=rp_GetNVM_IlluminationElement.Get_BsConst_Temperature_Sensor_Conv_SafeCopy1
          OA_rp_GetNVM_IlluminationElement_Get_BsConst_PCB_Temperature_Sensor_Conv_SafeCopy1: operation=rp_GetNVM_IlluminationElement.Get_BsConst_PCB_Temperature_Sensor_Conv_SafeCopy1
          OA_rp_GetNVM_IlluminationElement_Get_BsConst_Display_Illum_Max_Level_SafeCopy1: operation=rp_GetNVM_IlluminationElement.Get_BsConst_Display_Illum_Max_Level_SafeCopy1
          OA_rp_GetNVM_IlluminationElement_Get_BsConst_PWM_boost_bypass_duty_SafeCopy1: operation=rp_GetNVM_IlluminationElement.Get_BsConst_PWM_boost_bypass_duty_SafeCopy1
          OA_rp_GetNVM_IlluminationElement_Get_BsConst_BsConst_Illumination_ReservedByte_SafeCopy1: operation=rp_GetNVM_IlluminationElement.Get_BsConst_BsConst_Illumination_ReservedByte_SafeCopy1
          OA_rp_GetNVM_IlluminationElement_Get_BsConst_Compensation_Line_Slope_m_SafeCopy2: operation=rp_GetNVM_IlluminationElement.Get_BsConst_Compensation_Line_Slope_m_SafeCopy2
          OA_rp_GetNVM_IlluminationElement_Get_BsConst_Compensation_Line_Shift_b_SafeCopy2: operation=rp_GetNVM_IlluminationElement.Get_BsConst_Compensation_Line_Shift_b_SafeCopy2
          OA_rp_GetNVM_IlluminationElement_Get_BsConst_Lookup_Curve_HotSpot_Coef_X_SafeCopy2: operation=rp_GetNVM_IlluminationElement.Get_BsConst_Lookup_Curve_HotSpot_Coef_X_SafeCopy2
          OA_rp_GetNVM_IlluminationElement_Get_BsConst_Lookup_Curve_HotSpot_Coef_Y_SafeCopy2: operation=rp_GetNVM_IlluminationElement.Get_BsConst_Lookup_Curve_HotSpot_Coef_Y_SafeCopy2
          OA_rp_GetNVM_IlluminationElement_Get_BsConst_Temp_Threshold_Hysteresis_Derating_SafeCopy2: operation=rp_GetNVM_IlluminationElement.Get_BsConst_Temp_Threshold_Hysteresis_Derating_SafeCopy2
          OA_rp_GetNVM_IlluminationElement_Get_BsConst_Derating_Backlight_Disable_SafeCopy2: operation=rp_GetNVM_IlluminationElement.Get_BsConst_Derating_Backlight_Disable_SafeCopy2
          OA_rp_GetNVM_IlluminationElement_Get_BsConst_Temperature_Sensor_Conv_SafeCopy2: operation=rp_GetNVM_IlluminationElement.Get_BsConst_Temperature_Sensor_Conv_SafeCopy2
          OA_rp_GetNVM_IlluminationElement_Get_BsConst_PCB_Temperature_Sensor_Conv_SafeCopy2: operation=rp_GetNVM_IlluminationElement.Get_BsConst_PCB_Temperature_Sensor_Conv_SafeCopy2
          OA_rp_GetNVM_IlluminationElement_Get_BsConst_Display_Illum_Max_Level_SafeCopy2: operation=rp_GetNVM_IlluminationElement.Get_BsConst_Display_Illum_Max_Level_SafeCopy2
          OA_rp_GetNVM_IlluminationElement_Get_BsConst_PWM_boost_bypass_duty_SafeCopy2: operation=rp_GetNVM_IlluminationElement.Get_BsConst_PWM_boost_bypass_duty_SafeCopy2
          OA_rp_GetNVM_IlluminationElement_Get_BsConst_BsConst_Illumination_ReservedByte_SafeCopy2: operation=rp_GetNVM_IlluminationElement.Get_BsConst_BsConst_Illumination_ReservedByte_SafeCopy2
          OA_rp_GetNVM_IlluminationElement_Get_BsConst_Audio_Element: operation=rp_GetNVM_IlluminationElement.Get_BsConst_Audio_Element
          OA_rp_GetNVM_IlluminationElement_Get_BsConst_Warning_Element: operation=rp_GetNVM_IlluminationElement.Get_BsConst_Warning_Element
          OA_rp_GetNVM_IlluminationElement_Get_BsConst_RealTimeClock_Element: operation=rp_GetNVM_IlluminationElement.Get_BsConst_RealTimeClock_Element
          OA_rp_GetNVM_IlluminationElement_Get_BsConst_Communication_Element: operation=rp_GetNVM_IlluminationElement.Get_BsConst_Communication_Element
          OA_rp_GetNVM_IlluminationElement_Get_BsConst_Power_Element: operation=rp_GetNVM_IlluminationElement.Get_BsConst_Power_Element
          OA_rp_GetNVM_IlluminationElement_Get_BsConst_ServiceReminder_Element: operation=rp_GetNVM_IlluminationElement.Get_BsConst_ServiceReminder_Element
          OA_rp_GetNVM_IlluminationElement_Get_BsConst_EngOffTimer_Element: operation=rp_GetNVM_IlluminationElement.Get_BsConst_EngOffTimer_Element
          OA_rp_GetNVM_IlluminationElement_Get_BsCys_Certicificate_Element: operation=rp_GetNVM_IlluminationElement.Get_BsCys_Certicificate_Element
          OA_rp_GetNVM_IlluminationElement_Get_RefCys_Certicificate_Element: operation=rp_GetNVM_IlluminationElement.Get_RefCys_Certicificate_Element
          OA_rp_GetNVM_IlluminationElement_Get_RefCys_Certicificate1_Element: operation=rp_GetNVM_IlluminationElement.Get_RefCys_Certicificate1_Element
          OA_rp_GetNVM_IlluminationElement_Get_BsRt_Odometer_Element: operation=rp_GetNVM_IlluminationElement.Get_BsRt_Odometer_Element
          OA_rp_GetNVM_IlluminationElement_Get_BsRt_SpeedoGauge_Element: operation=rp_GetNVM_IlluminationElement.Get_BsRt_SpeedoGauge_Element
          OA_rp_GetNVM_IlluminationElement_Get_BsRt_TachoGauge_Element: operation=rp_GetNVM_IlluminationElement.Get_BsRt_TachoGauge_Element
          OA_rp_GetNVM_IlluminationElement_Get_BsRt_FuelGauge_Element: operation=rp_GetNVM_IlluminationElement.Get_BsRt_FuelGauge_Element
          OA_rp_GetNVM_IlluminationElement_Get_BsRt_TempGauge_Element: operation=rp_GetNVM_IlluminationElement.Get_BsRt_TempGauge_Element
          OA_rp_GetNVM_IlluminationElement_Get_BsRt_PowerGauge_Element: operation=rp_GetNVM_IlluminationElement.Get_BsRt_PowerGauge_Element
          OA_rp_GetNVM_IlluminationElement_Get_BsRt_OilGauge_Element: operation=rp_GetNVM_IlluminationElement.Get_BsRt_OilGauge_Element
          OA_rp_GetNVM_IlluminationElement_Get_BsRt_TripComputer_Element: operation=rp_GetNVM_IlluminationElement.Get_BsRt_TripComputer_Element
          OA_rp_GetNVM_IlluminationElement_Get_BsRt_Warning_Element: operation=rp_GetNVM_IlluminationElement.Get_BsRt_Warning_Element
          OA_rp_GetNVM_IlluminationElement_Get_BsRt_RealTimeClock_Element: operation=rp_GetNVM_IlluminationElement.Get_BsRt_RealTimeClock_Element
          OA_rp_GetNVM_IlluminationElement_Get_BsRt_Personalization_Element: operation=rp_GetNVM_IlluminationElement.Get_BsRt_Personalization_Element
          OA_rp_GetNVM_IlluminationElement_Get_BsRt_Illumination_Element: operation=rp_GetNVM_IlluminationElement.Get_BsRt_Illumination_Element
          OA_rp_GetNVM_IlluminationElement_Get_BsRt_CusDlt_Element: operation=rp_GetNVM_IlluminationElement.Get_BsRt_CusDlt_Element
          OA_rp_GetNVM_IlluminationElement_Get_BsReten_Odometer_Element: operation=rp_GetNVM_IlluminationElement.Get_BsReten_Odometer_Element
          OA_rp_GetNVM_IlluminationElement_Get_BsReten_Gauges_Element: operation=rp_GetNVM_IlluminationElement.Get_BsReten_Gauges_Element
          OA_rp_GetNVM_IlluminationElement_Get_BsReten_Tripcomputer_Element: operation=rp_GetNVM_IlluminationElement.Get_BsReten_Tripcomputer_Element
          OA_rp_GetNVM_IlluminationElement_Get_BsReten_Illumination_Element: operation=rp_GetNVM_IlluminationElement.Get_BsReten_Illumination_Element
          OA_rp_GetNVM_IlluminationElement_Get_BsReten_Audio_Element: operation=rp_GetNVM_IlluminationElement.Get_BsReten_Audio_Element
          OA_rp_GetNVM_IlluminationElement_Get_BsReten_Warning_Element: operation=rp_GetNVM_IlluminationElement.Get_BsReten_Warning_Element
          OA_rp_GetNVM_IlluminationElement_Get_BsReten_RealTimeClock_Element: operation=rp_GetNVM_IlluminationElement.Get_BsReten_RealTimeClock_Element
          OA_rp_GetNVM_IlluminationElement_Get_BsReten_Communication_Element: operation=rp_GetNVM_IlluminationElement.Get_BsReten_Communication_Element
          OA_rp_GetNVM_IlluminationElement_Get_BsReten_Personalization_Element: operation=rp_GetNVM_IlluminationElement.Get_BsReten_Personalization_Element
          OA_rp_GetNVM_IlluminationElement_Get_BsReten_Power_Element: operation=rp_GetNVM_IlluminationElement.Get_BsReten_Power_Element
          OA_rp_GetNVM_IlluminationElement_Get_BsReten_Display_Element: operation=rp_GetNVM_IlluminationElement.Get_BsReten_Display_Element
          OA_rp_GetNVM_IlluminationElement_Get_BsDiag_ErrorRecord_Element: operation=rp_GetNVM_IlluminationElement.Get_BsDiag_ErrorRecord_Element
          OA_rp_GetNVM_IlluminationElement_Get_BsDiag_Dtc_Element: operation=rp_GetNVM_IlluminationElement.Get_BsDiag_Dtc_Element
          OA_rp_PwmSetDuty_PwmSetDuty: operation=rp_PwmSetDuty.PwmSetDuty
          OA_rp_PwmSetDuty_PwmSetDutyAndPeriod: operation=rp_PwmSetDuty.PwmSetDutyAndPeriod
          OA_rp_PwmSetDuty_PwmSetIdeal: operation=rp_PwmSetDuty.PwmSetIdeal
          OA_rp_SetNVM_IlluminationElement_Set_BsShare_SwUpdReflash_Element: operation=rp_SetNVM_IlluminationElement.Set_BsShare_SwUpdReflash_Element
          OA_rp_SetNVM_IlluminationElement_Set_BsShare_SwUpdFotaMode_Element: operation=rp_SetNVM_IlluminationElement.Set_BsShare_SwUpdFotaMode_Element
          OA_rp_SetNVM_IlluminationElement_Set_BsShare_SwUpdFotaFinPrint_Element: operation=rp_SetNVM_IlluminationElement.Set_BsShare_SwUpdFotaFinPrint_Element
          OA_rp_SetNVM_IlluminationElement_Set_BsShare_SwUpdFotaStatus_Element: operation=rp_SetNVM_IlluminationElement.Set_BsShare_SwUpdFotaStatus_Element
          OA_rp_SetNVM_IlluminationElement_Set_BsShare_SwUpdFotadecrypt_Element: operation=rp_SetNVM_IlluminationElement.Set_BsShare_SwUpdFotadecrypt_Element
          OA_rp_SetNVM_IlluminationElement_Set_BsShare_EcuPartNumber_Element: operation=rp_SetNVM_IlluminationElement.Set_BsShare_EcuPartNumber_Element
          OA_rp_SetNVM_IlluminationElement_Set_BsShare_VisteonPartNumber: operation=rp_SetNVM_IlluminationElement.Set_BsShare_VisteonPartNumber
          OA_rp_SetNVM_IlluminationElement_Set_BsShare_VisteonPCBPartNumber: operation=rp_SetNVM_IlluminationElement.Set_BsShare_VisteonPCBPartNumber
          OA_rp_SetNVM_IlluminationElement_Set_BsShare_ProductSerialNumber: operation=rp_SetNVM_IlluminationElement.Set_BsShare_ProductSerialNumber
          OA_rp_SetNVM_IlluminationElement_Set_BsShare_PCBSerialNumber: operation=rp_SetNVM_IlluminationElement.Set_BsShare_PCBSerialNumber
          OA_rp_SetNVM_IlluminationElement_Set_BsShare_SMTManufacturingDate: operation=rp_SetNVM_IlluminationElement.Set_BsShare_SMTManufacturingDate
          OA_rp_SetNVM_IlluminationElement_Set_BsShare_AssemblyManufacturingDate: operation=rp_SetNVM_IlluminationElement.Set_BsShare_AssemblyManufacturingDate
          OA_rp_SetNVM_IlluminationElement_Set_BsShare_SMTPlantNumber: operation=rp_SetNVM_IlluminationElement.Set_BsShare_SMTPlantNumber
          OA_rp_SetNVM_IlluminationElement_Set_BsShare_AssemblyPlantNumber: operation=rp_SetNVM_IlluminationElement.Set_BsShare_AssemblyPlantNumber
          OA_rp_SetNVM_IlluminationElement_Set_BsShare_HWModification: operation=rp_SetNVM_IlluminationElement.Set_BsShare_HWModification
          OA_rp_SetNVM_IlluminationElement_Set_BsShare_VisMeet_Element: operation=rp_SetNVM_IlluminationElement.Set_BsShare_VisMeet_Element
          OA_rp_SetNVM_IlluminationElement_Set_BsShare_VisMeet_EOLEntry_Element: operation=rp_SetNVM_IlluminationElement.Set_BsShare_VisMeet_EOLEntry_Element
          OA_rp_SetNVM_IlluminationElement_Set_BsShare_VehicleConfig_Element: operation=rp_SetNVM_IlluminationElement.Set_BsShare_VehicleConfig_Element
          OA_rp_SetNVM_IlluminationElement_Set_BsConst_SpeedoGauge_Element: operation=rp_SetNVM_IlluminationElement.Set_BsConst_SpeedoGauge_Element
          OA_rp_SetNVM_IlluminationElement_Set_BsConst_TachoGauge_Element: operation=rp_SetNVM_IlluminationElement.Set_BsConst_TachoGauge_Element
          OA_rp_SetNVM_IlluminationElement_Set_BsConst_FuelGauge_Element: operation=rp_SetNVM_IlluminationElement.Set_BsConst_FuelGauge_Element
          OA_rp_SetNVM_IlluminationElement_Set_BsConst_TempGauge_Element: operation=rp_SetNVM_IlluminationElement.Set_BsConst_TempGauge_Element
          OA_rp_SetNVM_IlluminationElement_Set_BsConst_PowerGauge_Element: operation=rp_SetNVM_IlluminationElement.Set_BsConst_PowerGauge_Element
          OA_rp_SetNVM_IlluminationElement_Set_BsConst_OilGauge_Element: operation=rp_SetNVM_IlluminationElement.Set_BsConst_OilGauge_Element
          OA_rp_SetNVM_IlluminationElement_Set_BsConst_TripComputer_Element: operation=rp_SetNVM_IlluminationElement.Set_BsConst_TripComputer_Element
          OA_rp_SetNVM_IlluminationElement_Set_BsConst_Compensation_Line_Slope_m: operation=rp_SetNVM_IlluminationElement.Set_BsConst_Compensation_Line_Slope_m
          OA_rp_SetNVM_IlluminationElement_Set_BsConst_Compensation_Line_Shift_b: operation=rp_SetNVM_IlluminationElement.Set_BsConst_Compensation_Line_Shift_b
          OA_rp_SetNVM_IlluminationElement_Set_BsConst_Lookup_Curve_HotSpot_Coef_X: operation=rp_SetNVM_IlluminationElement.Set_BsConst_Lookup_Curve_HotSpot_Coef_X
          OA_rp_SetNVM_IlluminationElement_Set_BsConst_Lookup_Curve_HotSpot_Coef_Y: operation=rp_SetNVM_IlluminationElement.Set_BsConst_Lookup_Curve_HotSpot_Coef_Y
          OA_rp_SetNVM_IlluminationElement_Set_BsConst_Temp_Threshold_Hysteresis_Derating: operation=rp_SetNVM_IlluminationElement.Set_BsConst_Temp_Threshold_Hysteresis_Derating
          OA_rp_SetNVM_IlluminationElement_Set_BsConst_Derating_Backlight_Disable: operation=rp_SetNVM_IlluminationElement.Set_BsConst_Derating_Backlight_Disable
          OA_rp_SetNVM_IlluminationElement_Set_BsConst_Temperature_Sensor_Conv: operation=rp_SetNVM_IlluminationElement.Set_BsConst_Temperature_Sensor_Conv
          OA_rp_SetNVM_IlluminationElement_Set_BsConst_PCB_Temperature_Sensor_Conv: operation=rp_SetNVM_IlluminationElement.Set_BsConst_PCB_Temperature_Sensor_Conv
          OA_rp_SetNVM_IlluminationElement_Set_BsConst_Display_Illum_Max_Level: operation=rp_SetNVM_IlluminationElement.Set_BsConst_Display_Illum_Max_Level
          OA_rp_SetNVM_IlluminationElement_Set_BsConst_PWM_boost_bypass_duty: operation=rp_SetNVM_IlluminationElement.Set_BsConst_PWM_boost_bypass_duty
          OA_rp_SetNVM_IlluminationElement_Set_BsConst_BsConst_Illumination_ReservedByte: operation=rp_SetNVM_IlluminationElement.Set_BsConst_BsConst_Illumination_ReservedByte
          OA_rp_SetNVM_IlluminationElement_Set_BsConst_Compensation_Line_Slope_m_SafeCopy1: operation=rp_SetNVM_IlluminationElement.Set_BsConst_Compensation_Line_Slope_m_SafeCopy1
          OA_rp_SetNVM_IlluminationElement_Set_BsConst_Compensation_Line_Shift_b_SafeCopy1: operation=rp_SetNVM_IlluminationElement.Set_BsConst_Compensation_Line_Shift_b_SafeCopy1
          OA_rp_SetNVM_IlluminationElement_Set_BsConst_Lookup_Curve_HotSpot_Coef_X_SafeCopy1: operation=rp_SetNVM_IlluminationElement.Set_BsConst_Lookup_Curve_HotSpot_Coef_X_SafeCopy1
          OA_rp_SetNVM_IlluminationElement_Set_BsConst_Lookup_Curve_HotSpot_Coef_Y_SafeCopy1: operation=rp_SetNVM_IlluminationElement.Set_BsConst_Lookup_Curve_HotSpot_Coef_Y_SafeCopy1
          OA_rp_SetNVM_IlluminationElement_Set_BsConst_Temp_Threshold_Hysteresis_Derating_SafeCopy1: operation=rp_SetNVM_IlluminationElement.Set_BsConst_Temp_Threshold_Hysteresis_Derating_SafeCopy1
          OA_rp_SetNVM_IlluminationElement_Set_BsConst_Derating_Backlight_Disable_SafeCopy1: operation=rp_SetNVM_IlluminationElement.Set_BsConst_Derating_Backlight_Disable_SafeCopy1
          OA_rp_SetNVM_IlluminationElement_Set_BsConst_Temperature_Sensor_Conv_SafeCopy1: operation=rp_SetNVM_IlluminationElement.Set_BsConst_Temperature_Sensor_Conv_SafeCopy1
          OA_rp_SetNVM_IlluminationElement_Set_BsConst_PCB_Temperature_Sensor_Conv_SafeCopy1: operation=rp_SetNVM_IlluminationElement.Set_BsConst_PCB_Temperature_Sensor_Conv_SafeCopy1
          OA_rp_SetNVM_IlluminationElement_Set_BsConst_Display_Illum_Max_Level_SafeCopy1: operation=rp_SetNVM_IlluminationElement.Set_BsConst_Display_Illum_Max_Level_SafeCopy1
          OA_rp_SetNVM_IlluminationElement_Set_BsConst_PWM_boost_bypass_duty_SafeCopy1: operation=rp_SetNVM_IlluminationElement.Set_BsConst_PWM_boost_bypass_duty_SafeCopy1
          OA_rp_SetNVM_IlluminationElement_Set_BsConst_BsConst_Illumination_ReservedByte_SafeCopy1: operation=rp_SetNVM_IlluminationElement.Set_BsConst_BsConst_Illumination_ReservedByte_SafeCopy1
          OA_rp_SetNVM_IlluminationElement_Set_BsConst_Compensation_Line_Slope_m_SafeCopy2: operation=rp_SetNVM_IlluminationElement.Set_BsConst_Compensation_Line_Slope_m_SafeCopy2
          OA_rp_SetNVM_IlluminationElement_Set_BsConst_Compensation_Line_Shift_b_SafeCopy2: operation=rp_SetNVM_IlluminationElement.Set_BsConst_Compensation_Line_Shift_b_SafeCopy2
          OA_rp_SetNVM_IlluminationElement_Set_BsConst_Lookup_Curve_HotSpot_Coef_X_SafeCopy2: operation=rp_SetNVM_IlluminationElement.Set_BsConst_Lookup_Curve_HotSpot_Coef_X_SafeCopy2
          OA_rp_SetNVM_IlluminationElement_Set_BsConst_Lookup_Curve_HotSpot_Coef_Y_SafeCopy2: operation=rp_SetNVM_IlluminationElement.Set_BsConst_Lookup_Curve_HotSpot_Coef_Y_SafeCopy2
          OA_rp_SetNVM_IlluminationElement_Set_BsConst_Temp_Threshold_Hysteresis_Derating_SafeCopy2: operation=rp_SetNVM_IlluminationElement.Set_BsConst_Temp_Threshold_Hysteresis_Derating_SafeCopy2
          OA_rp_SetNVM_IlluminationElement_Set_BsConst_Derating_Backlight_Disable_SafeCopy2: operation=rp_SetNVM_IlluminationElement.Set_BsConst_Derating_Backlight_Disable_SafeCopy2
          OA_rp_SetNVM_IlluminationElement_Set_BsConst_Temperature_Sensor_Conv_SafeCopy2: operation=rp_SetNVM_IlluminationElement.Set_BsConst_Temperature_Sensor_Conv_SafeCopy2
          OA_rp_SetNVM_IlluminationElement_Set_BsConst_PCB_Temperature_Sensor_Conv_SafeCopy2: operation=rp_SetNVM_IlluminationElement.Set_BsConst_PCB_Temperature_Sensor_Conv_SafeCopy2
          OA_rp_SetNVM_IlluminationElement_Set_BsConst_Display_Illum_Max_Level_SafeCopy2: operation=rp_SetNVM_IlluminationElement.Set_BsConst_Display_Illum_Max_Level_SafeCopy2
          OA_rp_SetNVM_IlluminationElement_Set_BsConst_PWM_boost_bypass_duty_SafeCopy2: operation=rp_SetNVM_IlluminationElement.Set_BsConst_PWM_boost_bypass_duty_SafeCopy2
          OA_rp_SetNVM_IlluminationElement_Set_BsConst_BsConst_Illumination_ReservedByte_SafeCopy2: operation=rp_SetNVM_IlluminationElement.Set_BsConst_BsConst_Illumination_ReservedByte_SafeCopy2
          OA_rp_SetNVM_IlluminationElement_Set_BsConst_Audio_Element: operation=rp_SetNVM_IlluminationElement.Set_BsConst_Audio_Element
          OA_rp_SetNVM_IlluminationElement_Set_BsConst_Warning_Element: operation=rp_SetNVM_IlluminationElement.Set_BsConst_Warning_Element
          OA_rp_SetNVM_IlluminationElement_Set_BsConst_RealTimeClock_Element: operation=rp_SetNVM_IlluminationElement.Set_BsConst_RealTimeClock_Element
          OA_rp_SetNVM_IlluminationElement_Set_BsConst_Communication_Element: operation=rp_SetNVM_IlluminationElement.Set_BsConst_Communication_Element
          OA_rp_SetNVM_IlluminationElement_Set_BsConst_Power_Element: operation=rp_SetNVM_IlluminationElement.Set_BsConst_Power_Element
          OA_rp_SetNVM_IlluminationElement_Set_BsConst_ServiceReminder_Element: operation=rp_SetNVM_IlluminationElement.Set_BsConst_ServiceReminder_Element
          OA_rp_SetNVM_IlluminationElement_Set_BsConst_EngOffTimer_Element: operation=rp_SetNVM_IlluminationElement.Set_BsConst_EngOffTimer_Element
          OA_rp_SetNVM_IlluminationElement_Set_BsCys_Certicificate_Element: operation=rp_SetNVM_IlluminationElement.Set_BsCys_Certicificate_Element
          OA_rp_SetNVM_IlluminationElement_Set_RefCys_Certicificate_Element: operation=rp_SetNVM_IlluminationElement.Set_RefCys_Certicificate_Element
          OA_rp_SetNVM_IlluminationElement_Set_RefCys_Certicificate1_Element: operation=rp_SetNVM_IlluminationElement.Set_RefCys_Certicificate1_Element
          OA_rp_SetNVM_IlluminationElement_Set_BsRt_Odometer_Element: operation=rp_SetNVM_IlluminationElement.Set_BsRt_Odometer_Element
          OA_rp_SetNVM_IlluminationElement_Set_BsRt_SpeedoGauge_Element: operation=rp_SetNVM_IlluminationElement.Set_BsRt_SpeedoGauge_Element
          OA_rp_SetNVM_IlluminationElement_Set_BsRt_TachoGauge_Element: operation=rp_SetNVM_IlluminationElement.Set_BsRt_TachoGauge_Element
          OA_rp_SetNVM_IlluminationElement_Set_BsRt_FuelGauge_Element: operation=rp_SetNVM_IlluminationElement.Set_BsRt_FuelGauge_Element
          OA_rp_SetNVM_IlluminationElement_Set_BsRt_TempGauge_Element: operation=rp_SetNVM_IlluminationElement.Set_BsRt_TempGauge_Element
          OA_rp_SetNVM_IlluminationElement_Set_BsRt_PowerGauge_Element: operation=rp_SetNVM_IlluminationElement.Set_BsRt_PowerGauge_Element
          OA_rp_SetNVM_IlluminationElement_Set_BsRt_OilGauge_Element: operation=rp_SetNVM_IlluminationElement.Set_BsRt_OilGauge_Element
          OA_rp_SetNVM_IlluminationElement_Set_BsRt_TripComputer_Element: operation=rp_SetNVM_IlluminationElement.Set_BsRt_TripComputer_Element
          OA_rp_SetNVM_IlluminationElement_Set_BsRt_Warning_Element: operation=rp_SetNVM_IlluminationElement.Set_BsRt_Warning_Element
          OA_rp_SetNVM_IlluminationElement_Set_BsRt_RealTimeClock_Element: operation=rp_SetNVM_IlluminationElement.Set_BsRt_RealTimeClock_Element
          OA_rp_SetNVM_IlluminationElement_Set_BsRt_Personalization_Element: operation=rp_SetNVM_IlluminationElement.Set_BsRt_Personalization_Element
          OA_rp_SetNVM_IlluminationElement_Set_BsRt_Illumination_Element: operation=rp_SetNVM_IlluminationElement.Set_BsRt_Illumination_Element
          OA_rp_SetNVM_IlluminationElement_Set_BsRt_CusDlt_Element: operation=rp_SetNVM_IlluminationElement.Set_BsRt_CusDlt_Element
          OA_rp_SetNVM_IlluminationElement_Set_BsReten_Odometer_Element: operation=rp_SetNVM_IlluminationElement.Set_BsReten_Odometer_Element
          OA_rp_SetNVM_IlluminationElement_Set_BsReten_Gauges_Element: operation=rp_SetNVM_IlluminationElement.Set_BsReten_Gauges_Element
          OA_rp_SetNVM_IlluminationElement_Set_BsReten_Tripcomputer_Element: operation=rp_SetNVM_IlluminationElement.Set_BsReten_Tripcomputer_Element
          OA_rp_SetNVM_IlluminationElement_Set_BsReten_Illumination_Element: operation=rp_SetNVM_IlluminationElement.Set_BsReten_Illumination_Element
          OA_rp_SetNVM_IlluminationElement_Set_BsReten_Audio_Element: operation=rp_SetNVM_IlluminationElement.Set_BsReten_Audio_Element
          OA_rp_SetNVM_IlluminationElement_Set_BsReten_Warning_Element: operation=rp_SetNVM_IlluminationElement.Set_BsReten_Warning_Element
          OA_rp_SetNVM_IlluminationElement_Set_BsReten_RealTimeClock_Element: operation=rp_SetNVM_IlluminationElement.Set_BsReten_RealTimeClock_Element
          OA_rp_SetNVM_IlluminationElement_Set_BsReten_Communication_Element: operation=rp_SetNVM_IlluminationElement.Set_BsReten_Communication_Element
          OA_rp_SetNVM_IlluminationElement_Set_BsReten_Personalization_Element: operation=rp_SetNVM_IlluminationElement.Set_BsReten_Personalization_Element
          OA_rp_SetNVM_IlluminationElement_Set_BsReten_Power_Element: operation=rp_SetNVM_IlluminationElement.Set_BsReten_Power_Element
          OA_rp_SetNVM_IlluminationElement_Set_BsReten_Display_Element: operation=rp_SetNVM_IlluminationElement.Set_BsReten_Display_Element
          OA_rp_SetNVM_IlluminationElement_Set_BsDiag_ErrorRecord_Element: operation=rp_SetNVM_IlluminationElement.Set_BsDiag_ErrorRecord_Element
          OA_rp_SetNVM_IlluminationElement_Set_BsDiag_Dtc_Element: operation=rp_SetNVM_IlluminationElement.Set_BsDiag_Dtc_Element
          OA_rp_TmExt_Timer_IsElapsed_Timer_IsElapsed: operation=rp_TmExt_Timer_IsElapsed.Timer_IsElapsed
          OA_rp_TmExt_Timer_IsStarted_Timer_IsStarted: operation=rp_TmExt_Timer_IsStarted.Timer_IsStarted
          OA_rp_TmExt_Timer_Start_Timer_Start: operation=rp_TmExt_Timer_Start.Timer_Start
          OA_rp_TmExt_Timer_Stop_Timer_Stop: operation=rp_TmExt_Timer_Stop.Timer_Stop
      runnable CView_Illumination_Impl_OnCommand: can-be-invoked-concurrently=true
      runnable View_Illumination_Task: can-be-invoked-concurrently=true
        data-receive-point-by-arguments:
          11 x access:
            DRA_rpEtmSts_IllumStatus: accessed-variable=rpEtmSts.IllumStatus
            DRA_rpIgnSubstate_IgnitionSubstate: accessed-variable=rpIgnSubstate.IgnitionSubstate
            DRA_rpIllum_Etm_IllumStatus: accessed-variable=rpIllum_Etm.IllumStatus
            DRA_rpVehicleAppMode_WSSCurrentVehicleState: accessed-variable=rpVehicleAppMode.WSSCurrentVehicleState
            DRA_rp_EcoRunSystemState_EcoRunSystem_Flag: accessed-variable=rp_EcoRunSystemState.EcoRunSystem_Flag
            DRA_rp_EtmIllumSts_IllumStatus: accessed-variable=rp_EtmIllumSts.IllumStatus
            DRA_rp_IllumCtrl_Op_IllumCtrl_Op_Data: accessed-variable=rp_IllumCtrl_Op.IllumCtrl_Op_Data
            DRA_rp_RheostatDayStep_RheostatDayStep: accessed-variable=rp_RheostatDayStep.RheostatDayStep
            DRA_rp_RheostatNightStep_RheostatNightStep: accessed-variable=rp_RheostatNightStep.RheostatNightStep
            DRA_rp_Rheostat_Change_RheoUpdateVal: accessed-variable=rp_Rheostat_Change.RheoUpdateVal
            DRA_rp_TFTDisplayOn_TFTDisplayOn: accessed-variable=rp_TFTDisplayOn.TFTDisplayOn
        data-send-points:
          access DWA_pp_UCL_IlluminationData_IlluminationDataData: accessed-variable=pp_UCL_IlluminationData.IlluminationDataData
        298 x sync call, all with timeout=0.0:
          OA_rpIoHwAb_Din_GetAsyncRawInput: operation=rpIoHwAb_Din.GetAsyncRawInput
          OA_rpIoHwAb_Din_GetProcessedInput: operation=rpIoHwAb_Din.GetProcessedInput
          OA_rpIoHwAb_Din_GetSyncRawInput: operation=rpIoHwAb_Din.GetSyncRawInput
          OA_rpIoHwAb_Din_GetInputGroup: operation=rpIoHwAb_Din.GetInputGroup
          OA_rp_CS_Backlight_service_SetBrightnessValue: operation=rp_CS_Backlight_service.SetBrightnessValue
          OA_rp_CS_Backlight_service_GetBrightnessValue: operation=rp_CS_Backlight_service.GetBrightnessValue
          OA_rp_CS_Backlight_service_GetThermalValue: operation=rp_CS_Backlight_service.GetThermalValue
          OA_rp_CS_EcuBatteryOutData_EcuBatteryM_GetChannelStatus: operation=rp_CS_EcuBatteryOutData.EcuBatteryM_GetChannelStatus
          OA_rp_CS_EcuBatteryOutData_EcuBatteryM_GetDIOStatus: operation=rp_CS_EcuBatteryOutData.EcuBatteryM_GetDIOStatus
          OA_rp_CS_MemAbsGet_Get_BsShare_SwUpdReflash_Element: operation=rp_CS_MemAbsGet.Get_BsShare_SwUpdReflash_Element
          OA_rp_CS_MemAbsGet_Get_BsShare_SwUpdFotaMode_Element: operation=rp_CS_MemAbsGet.Get_BsShare_SwUpdFotaMode_Element
          OA_rp_CS_MemAbsGet_Get_BsShare_SwUpdFotaFinPrint_Element: operation=rp_CS_MemAbsGet.Get_BsShare_SwUpdFotaFinPrint_Element
          OA_rp_CS_MemAbsGet_Get_BsShare_SwUpdFotaStatus_Element: operation=rp_CS_MemAbsGet.Get_BsShare_SwUpdFotaStatus_Element
          OA_rp_CS_MemAbsGet_Get_BsShare_SwUpdFotadecrypt_Element: operation=rp_CS_MemAbsGet.Get_BsShare_SwUpdFotadecrypt_Element
          OA_rp_CS_MemAbsGet_Get_BsShare_EcuPartNumber_Element: operation=rp_CS_MemAbsGet.Get_BsShare_EcuPartNumber_Element
          OA_rp_CS_MemAbsGet_Get_BsShare_VisteonPartNumber: operation=rp_CS_MemAbsGet.Get_BsShare_VisteonPartNumber
          OA_rp_CS_MemAbsGet_Get_BsShare_VisteonPCBPartNumber: operation=rp_CS_MemAbsGet.Get_BsShare_VisteonPCBPartNumber
          OA_rp_CS_MemAbsGet_Get_BsShare_ProductSerialNumber: operation=rp_CS_MemAbsGet.Get_BsShare_ProductSerialNumber
          OA_rp_CS_MemAbsGet_Get_BsShare_PCBSerialNumber: operation=rp_CS_MemAbsGet.Get_BsShare_PCBSerialNumber
          OA_rp_CS_MemAbsGet_Get_BsShare_SMTManufacturingDate: operation=rp_CS_MemAbsGet.Get_BsShare_SMTManufacturingDate
          OA_rp_CS_MemAbsGet_Get_BsShare_AssemblyManufacturingDate: operation=rp_CS_MemAbsGet.Get_BsShare_AssemblyManufacturingDate
          OA_rp_CS_MemAbsGet_Get_BsShare_SMTPlantNumber: operation=rp_CS_MemAbsGet.Get_BsShare_SMTPlantNumber
          OA_rp_CS_MemAbsGet_Get_BsShare_AssemblyPlantNumber: operation=rp_CS_MemAbsGet.Get_BsShare_AssemblyPlantNumber
          OA_rp_CS_MemAbsGet_Get_BsShare_HWModification: operation=rp_CS_MemAbsGet.Get_BsShare_HWModification
          OA_rp_CS_MemAbsGet_Get_BsShare_VisMeet_Element: operation=rp_CS_MemAbsGet.Get_BsShare_VisMeet_Element
          OA_rp_CS_MemAbsGet_Get_BsShare_VisMeet_EOLEntry_Element: operation=rp_CS_MemAbsGet.Get_BsShare_VisMeet_EOLEntry_Element
          OA_rp_CS_MemAbsGet_Get_BsShare_VehicleConfig_Element: operation=rp_CS_MemAbsGet.Get_BsShare_VehicleConfig_Element
          OA_rp_CS_MemAbsGet_Get_BsConst_SpeedoGauge_Element: operation=rp_CS_MemAbsGet.Get_BsConst_SpeedoGauge_Element
          OA_rp_CS_MemAbsGet_Get_BsConst_TachoGauge_Element: operation=rp_CS_MemAbsGet.Get_BsConst_TachoGauge_Element
          OA_rp_CS_MemAbsGet_Get_BsConst_FuelGauge_Element: operation=rp_CS_MemAbsGet.Get_BsConst_FuelGauge_Element
          OA_rp_CS_MemAbsGet_Get_BsConst_TempGauge_Element: operation=rp_CS_MemAbsGet.Get_BsConst_TempGauge_Element
          OA_rp_CS_MemAbsGet_Get_BsConst_PowerGauge_Element: operation=rp_CS_MemAbsGet.Get_BsConst_PowerGauge_Element
          OA_rp_CS_MemAbsGet_Get_BsConst_OilGauge_Element: operation=rp_CS_MemAbsGet.Get_BsConst_OilGauge_Element
          OA_rp_CS_MemAbsGet_Get_BsConst_TripComputer_Element: operation=rp_CS_MemAbsGet.Get_BsConst_TripComputer_Element
          OA_rp_CS_MemAbsGet_Get_BsConst_Compensation_Line_Slope_m: operation=rp_CS_MemAbsGet.Get_BsConst_Compensation_Line_Slope_m
          OA_rp_CS_MemAbsGet_Get_BsConst_Compensation_Line_Shift_b: operation=rp_CS_MemAbsGet.Get_BsConst_Compensation_Line_Shift_b
          OA_rp_CS_MemAbsGet_Get_BsConst_Lookup_Curve_HotSpot_Coef_X: operation=rp_CS_MemAbsGet.Get_BsConst_Lookup_Curve_HotSpot_Coef_X
          OA_rp_CS_MemAbsGet_Get_BsConst_Lookup_Curve_HotSpot_Coef_Y: operation=rp_CS_MemAbsGet.Get_BsConst_Lookup_Curve_HotSpot_Coef_Y
          OA_rp_CS_MemAbsGet_Get_BsConst_Temp_Threshold_Hysteresis_Derating: operation=rp_CS_MemAbsGet.Get_BsConst_Temp_Threshold_Hysteresis_Derating
          OA_rp_CS_MemAbsGet_Get_BsConst_Derating_Backlight_Disable: operation=rp_CS_MemAbsGet.Get_BsConst_Derating_Backlight_Disable
          OA_rp_CS_MemAbsGet_Get_BsConst_Temperature_Sensor_Conv: operation=rp_CS_MemAbsGet.Get_BsConst_Temperature_Sensor_Conv
          OA_rp_CS_MemAbsGet_Get_BsConst_PCB_Temperature_Sensor_Conv: operation=rp_CS_MemAbsGet.Get_BsConst_PCB_Temperature_Sensor_Conv
          OA_rp_CS_MemAbsGet_Get_BsConst_Display_Illum_Max_Level: operation=rp_CS_MemAbsGet.Get_BsConst_Display_Illum_Max_Level
          OA_rp_CS_MemAbsGet_Get_BsConst_PWM_boost_bypass_duty: operation=rp_CS_MemAbsGet.Get_BsConst_PWM_boost_bypass_duty
          OA_rp_CS_MemAbsGet_Get_BsConst_BsConst_Illumination_ReservedByte: operation=rp_CS_MemAbsGet.Get_BsConst_BsConst_Illumination_ReservedByte
          OA_rp_CS_MemAbsGet_Get_BsConst_Compensation_Line_Slope_m_SafeCopy1: operation=rp_CS_MemAbsGet.Get_BsConst_Compensation_Line_Slope_m_SafeCopy1
          OA_rp_CS_MemAbsGet_Get_BsConst_Compensation_Line_Shift_b_SafeCopy1: operation=rp_CS_MemAbsGet.Get_BsConst_Compensation_Line_Shift_b_SafeCopy1
          OA_rp_CS_MemAbsGet_Get_BsConst_Lookup_Curve_HotSpot_Coef_X_SafeCopy1: operation=rp_CS_MemAbsGet.Get_BsConst_Lookup_Curve_HotSpot_Coef_X_SafeCopy1
          OA_rp_CS_MemAbsGet_Get_BsConst_Lookup_Curve_HotSpot_Coef_Y_SafeCopy1: operation=rp_CS_MemAbsGet.Get_BsConst_Lookup_Curve_HotSpot_Coef_Y_SafeCopy1
          OA_rp_CS_MemAbsGet_Get_BsConst_Temp_Threshold_Hysteresis_Derating_SafeCopy1: operation=rp_CS_MemAbsGet.Get_BsConst_Temp_Threshold_Hysteresis_Derating_SafeCopy1
          OA_rp_CS_MemAbsGet_Get_BsConst_Derating_Backlight_Disable_SafeCopy1: operation=rp_CS_MemAbsGet.Get_BsConst_Derating_Backlight_Disable_SafeCopy1
          OA_rp_CS_MemAbsGet_Get_BsConst_Temperature_Sensor_Conv_SafeCopy1: operation=rp_CS_MemAbsGet.Get_BsConst_Temperature_Sensor_Conv_SafeCopy1
          OA_rp_CS_MemAbsGet_Get_BsConst_PCB_Temperature_Sensor_Conv_SafeCopy1: operation=rp_CS_MemAbsGet.Get_BsConst_PCB_Temperature_Sensor_Conv_SafeCopy1
          OA_rp_CS_MemAbsGet_Get_BsConst_Display_Illum_Max_Level_SafeCopy1: operation=rp_CS_MemAbsGet.Get_BsConst_Display_Illum_Max_Level_SafeCopy1
          OA_rp_CS_MemAbsGet_Get_BsConst_PWM_boost_bypass_duty_SafeCopy1: operation=rp_CS_MemAbsGet.Get_BsConst_PWM_boost_bypass_duty_SafeCopy1
          OA_rp_CS_MemAbsGet_Get_BsConst_BsConst_Illumination_ReservedByte_SafeCopy1: operation=rp_CS_MemAbsGet.Get_BsConst_BsConst_Illumination_ReservedByte_SafeCopy1
          OA_rp_CS_MemAbsGet_Get_BsConst_Compensation_Line_Slope_m_SafeCopy2: operation=rp_CS_MemAbsGet.Get_BsConst_Compensation_Line_Slope_m_SafeCopy2
          OA_rp_CS_MemAbsGet_Get_BsConst_Compensation_Line_Shift_b_SafeCopy2: operation=rp_CS_MemAbsGet.Get_BsConst_Compensation_Line_Shift_b_SafeCopy2
          OA_rp_CS_MemAbsGet_Get_BsConst_Lookup_Curve_HotSpot_Coef_X_SafeCopy2: operation=rp_CS_MemAbsGet.Get_BsConst_Lookup_Curve_HotSpot_Coef_X_SafeCopy2
          OA_rp_CS_MemAbsGet_Get_BsConst_Lookup_Curve_HotSpot_Coef_Y_SafeCopy2: operation=rp_CS_MemAbsGet.Get_BsConst_Lookup_Curve_HotSpot_Coef_Y_SafeCopy2
          OA_rp_CS_MemAbsGet_Get_BsConst_Temp_Threshold_Hysteresis_Derating_SafeCopy2: operation=rp_CS_MemAbsGet.Get_BsConst_Temp_Threshold_Hysteresis_Derating_SafeCopy2
          OA_rp_CS_MemAbsGet_Get_BsConst_Derating_Backlight_Disable_SafeCopy2: operation=rp_CS_MemAbsGet.Get_BsConst_Derating_Backlight_Disable_SafeCopy2
          OA_rp_CS_MemAbsGet_Get_BsConst_Temperature_Sensor_Conv_SafeCopy2: operation=rp_CS_MemAbsGet.Get_BsConst_Temperature_Sensor_Conv_SafeCopy2
          OA_rp_CS_MemAbsGet_Get_BsConst_PCB_Temperature_Sensor_Conv_SafeCopy2: operation=rp_CS_MemAbsGet.Get_BsConst_PCB_Temperature_Sensor_Conv_SafeCopy2
          OA_rp_CS_MemAbsGet_Get_BsConst_Display_Illum_Max_Level_SafeCopy2: operation=rp_CS_MemAbsGet.Get_BsConst_Display_Illum_Max_Level_SafeCopy2
          OA_rp_CS_MemAbsGet_Get_BsConst_PWM_boost_bypass_duty_SafeCopy2: operation=rp_CS_MemAbsGet.Get_BsConst_PWM_boost_bypass_duty_SafeCopy2
          OA_rp_CS_MemAbsGet_Get_BsConst_BsConst_Illumination_ReservedByte_SafeCopy2: operation=rp_CS_MemAbsGet.Get_BsConst_BsConst_Illumination_ReservedByte_SafeCopy2
          OA_rp_CS_MemAbsGet_Get_BsConst_Audio_Element: operation=rp_CS_MemAbsGet.Get_BsConst_Audio_Element
          OA_rp_CS_MemAbsGet_Get_BsConst_Warning_Element: operation=rp_CS_MemAbsGet.Get_BsConst_Warning_Element
          OA_rp_CS_MemAbsGet_Get_BsConst_RealTimeClock_Element: operation=rp_CS_MemAbsGet.Get_BsConst_RealTimeClock_Element
          OA_rp_CS_MemAbsGet_Get_BsConst_Communication_Element: operation=rp_CS_MemAbsGet.Get_BsConst_Communication_Element
          OA_rp_CS_MemAbsGet_Get_BsConst_Power_Element: operation=rp_CS_MemAbsGet.Get_BsConst_Power_Element
          OA_rp_CS_MemAbsGet_Get_BsConst_ServiceReminder_Element: operation=rp_CS_MemAbsGet.Get_BsConst_ServiceReminder_Element
          OA_rp_CS_MemAbsGet_Get_BsConst_EngOffTimer_Element: operation=rp_CS_MemAbsGet.Get_BsConst_EngOffTimer_Element
          OA_rp_CS_MemAbsGet_Get_BsCys_Certicificate_Element: operation=rp_CS_MemAbsGet.Get_BsCys_Certicificate_Element
          OA_rp_CS_MemAbsGet_Get_RefCys_Certicificate_Element: operation=rp_CS_MemAbsGet.Get_RefCys_Certicificate_Element
          OA_rp_CS_MemAbsGet_Get_RefCys_Certicificate1_Element: operation=rp_CS_MemAbsGet.Get_RefCys_Certicificate1_Element
          OA_rp_CS_MemAbsGet_Get_BsRt_Odometer_Element: operation=rp_CS_MemAbsGet.Get_BsRt_Odometer_Element
          OA_rp_CS_MemAbsGet_Get_BsRt_SpeedoGauge_Element: operation=rp_CS_MemAbsGet.Get_BsRt_SpeedoGauge_Element
          OA_rp_CS_MemAbsGet_Get_BsRt_TachoGauge_Element: operation=rp_CS_MemAbsGet.Get_BsRt_TachoGauge_Element
          OA_rp_CS_MemAbsGet_Get_BsRt_FuelGauge_Element: operation=rp_CS_MemAbsGet.Get_BsRt_FuelGauge_Element
          OA_rp_CS_MemAbsGet_Get_BsRt_TempGauge_Element: operation=rp_CS_MemAbsGet.Get_BsRt_TempGauge_Element
          OA_rp_CS_MemAbsGet_Get_BsRt_PowerGauge_Element: operation=rp_CS_MemAbsGet.Get_BsRt_PowerGauge_Element
          OA_rp_CS_MemAbsGet_Get_BsRt_OilGauge_Element: operation=rp_CS_MemAbsGet.Get_BsRt_OilGauge_Element
          OA_rp_CS_MemAbsGet_Get_BsRt_TripComputer_Element: operation=rp_CS_MemAbsGet.Get_BsRt_TripComputer_Element
          OA_rp_CS_MemAbsGet_Get_BsRt_Warning_Element: operation=rp_CS_MemAbsGet.Get_BsRt_Warning_Element
          OA_rp_CS_MemAbsGet_Get_BsRt_RealTimeClock_Element: operation=rp_CS_MemAbsGet.Get_BsRt_RealTimeClock_Element
          OA_rp_CS_MemAbsGet_Get_BsRt_Personalization_Element: operation=rp_CS_MemAbsGet.Get_BsRt_Personalization_Element
          OA_rp_CS_MemAbsGet_Get_BsRt_Illumination_Element: operation=rp_CS_MemAbsGet.Get_BsRt_Illumination_Element
          OA_rp_CS_MemAbsGet_Get_BsRt_CusDlt_Element: operation=rp_CS_MemAbsGet.Get_BsRt_CusDlt_Element
          OA_rp_CS_MemAbsGet_Get_BsReten_Odometer_Element: operation=rp_CS_MemAbsGet.Get_BsReten_Odometer_Element
          OA_rp_CS_MemAbsGet_Get_BsReten_Gauges_Element: operation=rp_CS_MemAbsGet.Get_BsReten_Gauges_Element
          OA_rp_CS_MemAbsGet_Get_BsReten_Tripcomputer_Element: operation=rp_CS_MemAbsGet.Get_BsReten_Tripcomputer_Element
          OA_rp_CS_MemAbsGet_Get_BsReten_Illumination_Element: operation=rp_CS_MemAbsGet.Get_BsReten_Illumination_Element
          OA_rp_CS_MemAbsGet_Get_BsReten_Audio_Element: operation=rp_CS_MemAbsGet.Get_BsReten_Audio_Element
          OA_rp_CS_MemAbsGet_Get_BsReten_Warning_Element: operation=rp_CS_MemAbsGet.Get_BsReten_Warning_Element
          OA_rp_CS_MemAbsGet_Get_BsReten_RealTimeClock_Element: operation=rp_CS_MemAbsGet.Get_BsReten_RealTimeClock_Element
          OA_rp_CS_MemAbsGet_Get_BsReten_Communication_Element: operation=rp_CS_MemAbsGet.Get_BsReten_Communication_Element
          OA_rp_CS_MemAbsGet_Get_BsReten_Personalization_Element: operation=rp_CS_MemAbsGet.Get_BsReten_Personalization_Element
          OA_rp_CS_MemAbsGet_Get_BsReten_Power_Element: operation=rp_CS_MemAbsGet.Get_BsReten_Power_Element
          OA_rp_CS_MemAbsGet_Get_BsReten_Display_Element: operation=rp_CS_MemAbsGet.Get_BsReten_Display_Element
          OA_rp_CS_MemAbsGet_Get_BsDiag_ErrorRecord_Element: operation=rp_CS_MemAbsGet.Get_BsDiag_ErrorRecord_Element
          OA_rp_CS_MemAbsGet_Get_BsDiag_Dtc_Element: operation=rp_CS_MemAbsGet.Get_BsDiag_Dtc_Element
          OA_rp_GetNVM_IlluminationElement_Get_BsShare_SwUpdReflash_Element: operation=rp_GetNVM_IlluminationElement.Get_BsShare_SwUpdReflash_Element
          OA_rp_GetNVM_IlluminationElement_Get_BsShare_SwUpdFotaMode_Element: operation=rp_GetNVM_IlluminationElement.Get_BsShare_SwUpdFotaMode_Element
          OA_rp_GetNVM_IlluminationElement_Get_BsShare_SwUpdFotaFinPrint_Element: operation=rp_GetNVM_IlluminationElement.Get_BsShare_SwUpdFotaFinPrint_Element
          OA_rp_GetNVM_IlluminationElement_Get_BsShare_SwUpdFotaStatus_Element: operation=rp_GetNVM_IlluminationElement.Get_BsShare_SwUpdFotaStatus_Element
          OA_rp_GetNVM_IlluminationElement_Get_BsShare_SwUpdFotadecrypt_Element: operation=rp_GetNVM_IlluminationElement.Get_BsShare_SwUpdFotadecrypt_Element
          OA_rp_GetNVM_IlluminationElement_Get_BsShare_EcuPartNumber_Element: operation=rp_GetNVM_IlluminationElement.Get_BsShare_EcuPartNumber_Element
          OA_rp_GetNVM_IlluminationElement_Get_BsShare_VisteonPartNumber: operation=rp_GetNVM_IlluminationElement.Get_BsShare_VisteonPartNumber
          OA_rp_GetNVM_IlluminationElement_Get_BsShare_VisteonPCBPartNumber: operation=rp_GetNVM_IlluminationElement.Get_BsShare_VisteonPCBPartNumber
          OA_rp_GetNVM_IlluminationElement_Get_BsShare_ProductSerialNumber: operation=rp_GetNVM_IlluminationElement.Get_BsShare_ProductSerialNumber
          OA_rp_GetNVM_IlluminationElement_Get_BsShare_PCBSerialNumber: operation=rp_GetNVM_IlluminationElement.Get_BsShare_PCBSerialNumber
          OA_rp_GetNVM_IlluminationElement_Get_BsShare_SMTManufacturingDate: operation=rp_GetNVM_IlluminationElement.Get_BsShare_SMTManufacturingDate
          OA_rp_GetNVM_IlluminationElement_Get_BsShare_AssemblyManufacturingDate: operation=rp_GetNVM_IlluminationElement.Get_BsShare_AssemblyManufacturingDate
          OA_rp_GetNVM_IlluminationElement_Get_BsShare_SMTPlantNumber: operation=rp_GetNVM_IlluminationElement.Get_BsShare_SMTPlantNumber
          OA_rp_GetNVM_IlluminationElement_Get_BsShare_AssemblyPlantNumber: operation=rp_GetNVM_IlluminationElement.Get_BsShare_AssemblyPlantNumber
          OA_rp_GetNVM_IlluminationElement_Get_BsShare_HWModification: operation=rp_GetNVM_IlluminationElement.Get_BsShare_HWModification
          OA_rp_GetNVM_IlluminationElement_Get_BsShare_VisMeet_Element: operation=rp_GetNVM_IlluminationElement.Get_BsShare_VisMeet_Element
          OA_rp_GetNVM_IlluminationElement_Get_BsShare_VisMeet_EOLEntry_Element: operation=rp_GetNVM_IlluminationElement.Get_BsShare_VisMeet_EOLEntry_Element
          OA_rp_GetNVM_IlluminationElement_Get_BsShare_VehicleConfig_Element: operation=rp_GetNVM_IlluminationElement.Get_BsShare_VehicleConfig_Element
          OA_rp_GetNVM_IlluminationElement_Get_BsConst_SpeedoGauge_Element: operation=rp_GetNVM_IlluminationElement.Get_BsConst_SpeedoGauge_Element
          OA_rp_GetNVM_IlluminationElement_Get_BsConst_TachoGauge_Element: operation=rp_GetNVM_IlluminationElement.Get_BsConst_TachoGauge_Element
          OA_rp_GetNVM_IlluminationElement_Get_BsConst_FuelGauge_Element: operation=rp_GetNVM_IlluminationElement.Get_BsConst_FuelGauge_Element
          OA_rp_GetNVM_IlluminationElement_Get_BsConst_TempGauge_Element: operation=rp_GetNVM_IlluminationElement.Get_BsConst_TempGauge_Element
          OA_rp_GetNVM_IlluminationElement_Get_BsConst_PowerGauge_Element: operation=rp_GetNVM_IlluminationElement.Get_BsConst_PowerGauge_Element
          OA_rp_GetNVM_IlluminationElement_Get_BsConst_OilGauge_Element: operation=rp_GetNVM_IlluminationElement.Get_BsConst_OilGauge_Element
          OA_rp_GetNVM_IlluminationElement_Get_BsConst_TripComputer_Element: operation=rp_GetNVM_IlluminationElement.Get_BsConst_TripComputer_Element
          OA_rp_GetNVM_IlluminationElement_Get_BsConst_Compensation_Line_Slope_m: operation=rp_GetNVM_IlluminationElement.Get_BsConst_Compensation_Line_Slope_m
          OA_rp_GetNVM_IlluminationElement_Get_BsConst_Compensation_Line_Shift_b: operation=rp_GetNVM_IlluminationElement.Get_BsConst_Compensation_Line_Shift_b
          OA_rp_GetNVM_IlluminationElement_Get_BsConst_Lookup_Curve_HotSpot_Coef_X: operation=rp_GetNVM_IlluminationElement.Get_BsConst_Lookup_Curve_HotSpot_Coef_X
          OA_rp_GetNVM_IlluminationElement_Get_BsConst_Lookup_Curve_HotSpot_Coef_Y: operation=rp_GetNVM_IlluminationElement.Get_BsConst_Lookup_Curve_HotSpot_Coef_Y
          OA_rp_GetNVM_IlluminationElement_Get_BsConst_Temp_Threshold_Hysteresis_Derating: operation=rp_GetNVM_IlluminationElement.Get_BsConst_Temp_Threshold_Hysteresis_Derating
          OA_rp_GetNVM_IlluminationElement_Get_BsConst_Derating_Backlight_Disable: operation=rp_GetNVM_IlluminationElement.Get_BsConst_Derating_Backlight_Disable
          OA_rp_GetNVM_IlluminationElement_Get_BsConst_Temperature_Sensor_Conv: operation=rp_GetNVM_IlluminationElement.Get_BsConst_Temperature_Sensor_Conv
          OA_rp_GetNVM_IlluminationElement_Get_BsConst_PCB_Temperature_Sensor_Conv: operation=rp_GetNVM_IlluminationElement.Get_BsConst_PCB_Temperature_Sensor_Conv
          OA_rp_GetNVM_IlluminationElement_Get_BsConst_Display_Illum_Max_Level: operation=rp_GetNVM_IlluminationElement.Get_BsConst_Display_Illum_Max_Level
          OA_rp_GetNVM_IlluminationElement_Get_BsConst_PWM_boost_bypass_duty: operation=rp_GetNVM_IlluminationElement.Get_BsConst_PWM_boost_bypass_duty
          OA_rp_GetNVM_IlluminationElement_Get_BsConst_BsConst_Illumination_ReservedByte: operation=rp_GetNVM_IlluminationElement.Get_BsConst_BsConst_Illumination_ReservedByte
          OA_rp_GetNVM_IlluminationElement_Get_BsConst_Compensation_Line_Slope_m_SafeCopy1: operation=rp_GetNVM_IlluminationElement.Get_BsConst_Compensation_Line_Slope_m_SafeCopy1
          OA_rp_GetNVM_IlluminationElement_Get_BsConst_Compensation_Line_Shift_b_SafeCopy1: operation=rp_GetNVM_IlluminationElement.Get_BsConst_Compensation_Line_Shift_b_SafeCopy1
          OA_rp_GetNVM_IlluminationElement_Get_BsConst_Lookup_Curve_HotSpot_Coef_X_SafeCopy1: operation=rp_GetNVM_IlluminationElement.Get_BsConst_Lookup_Curve_HotSpot_Coef_X_SafeCopy1
          OA_rp_GetNVM_IlluminationElement_Get_BsConst_Lookup_Curve_HotSpot_Coef_Y_SafeCopy1: operation=rp_GetNVM_IlluminationElement.Get_BsConst_Lookup_Curve_HotSpot_Coef_Y_SafeCopy1
          OA_rp_GetNVM_IlluminationElement_Get_BsConst_Temp_Threshold_Hysteresis_Derating_SafeCopy1: operation=rp_GetNVM_IlluminationElement.Get_BsConst_Temp_Threshold_Hysteresis_Derating_SafeCopy1
          OA_rp_GetNVM_IlluminationElement_Get_BsConst_Derating_Backlight_Disable_SafeCopy1: operation=rp_GetNVM_IlluminationElement.Get_BsConst_Derating_Backlight_Disable_SafeCopy1
          OA_rp_GetNVM_IlluminationElement_Get_BsConst_Temperature_Sensor_Conv_SafeCopy1: operation=rp_GetNVM_IlluminationElement.Get_BsConst_Temperature_Sensor_Conv_SafeCopy1
          OA_rp_GetNVM_IlluminationElement_Get_BsConst_PCB_Temperature_Sensor_Conv_SafeCopy1: operation=rp_GetNVM_IlluminationElement.Get_BsConst_PCB_Temperature_Sensor_Conv_SafeCopy1
          OA_rp_GetNVM_IlluminationElement_Get_BsConst_Display_Illum_Max_Level_SafeCopy1: operation=rp_GetNVM_IlluminationElement.Get_BsConst_Display_Illum_Max_Level_SafeCopy1
          OA_rp_GetNVM_IlluminationElement_Get_BsConst_PWM_boost_bypass_duty_SafeCopy1: operation=rp_GetNVM_IlluminationElement.Get_BsConst_PWM_boost_bypass_duty_SafeCopy1
          OA_rp_GetNVM_IlluminationElement_Get_BsConst_BsConst_Illumination_ReservedByte_SafeCopy1: operation=rp_GetNVM_IlluminationElement.Get_BsConst_BsConst_Illumination_ReservedByte_SafeCopy1
          OA_rp_GetNVM_IlluminationElement_Get_BsConst_Compensation_Line_Slope_m_SafeCopy2: operation=rp_GetNVM_IlluminationElement.Get_BsConst_Compensation_Line_Slope_m_SafeCopy2
          OA_rp_GetNVM_IlluminationElement_Get_BsConst_Compensation_Line_Shift_b_SafeCopy2: operation=rp_GetNVM_IlluminationElement.Get_BsConst_Compensation_Line_Shift_b_SafeCopy2
          OA_rp_GetNVM_IlluminationElement_Get_BsConst_Lookup_Curve_HotSpot_Coef_X_SafeCopy2: operation=rp_GetNVM_IlluminationElement.Get_BsConst_Lookup_Curve_HotSpot_Coef_X_SafeCopy2
          OA_rp_GetNVM_IlluminationElement_Get_BsConst_Lookup_Curve_HotSpot_Coef_Y_SafeCopy2: operation=rp_GetNVM_IlluminationElement.Get_BsConst_Lookup_Curve_HotSpot_Coef_Y_SafeCopy2
          OA_rp_GetNVM_IlluminationElement_Get_BsConst_Temp_Threshold_Hysteresis_Derating_SafeCopy2: operation=rp_GetNVM_IlluminationElement.Get_BsConst_Temp_Threshold_Hysteresis_Derating_SafeCopy2
          OA_rp_GetNVM_IlluminationElement_Get_BsConst_Derating_Backlight_Disable_SafeCopy2: operation=rp_GetNVM_IlluminationElement.Get_BsConst_Derating_Backlight_Disable_SafeCopy2
          OA_rp_GetNVM_IlluminationElement_Get_BsConst_Temperature_Sensor_Conv_SafeCopy2: operation=rp_GetNVM_IlluminationElement.Get_BsConst_Temperature_Sensor_Conv_SafeCopy2
          OA_rp_GetNVM_IlluminationElement_Get_BsConst_PCB_Temperature_Sensor_Conv_SafeCopy2: operation=rp_GetNVM_IlluminationElement.Get_BsConst_PCB_Temperature_Sensor_Conv_SafeCopy2
          OA_rp_GetNVM_IlluminationElement_Get_BsConst_Display_Illum_Max_Level_SafeCopy2: operation=rp_GetNVM_IlluminationElement.Get_BsConst_Display_Illum_Max_Level_SafeCopy2
          OA_rp_GetNVM_IlluminationElement_Get_BsConst_PWM_boost_bypass_duty_SafeCopy2: operation=rp_GetNVM_IlluminationElement.Get_BsConst_PWM_boost_bypass_duty_SafeCopy2
          OA_rp_GetNVM_IlluminationElement_Get_BsConst_BsConst_Illumination_ReservedByte_SafeCopy2: operation=rp_GetNVM_IlluminationElement.Get_BsConst_BsConst_Illumination_ReservedByte_SafeCopy2
          OA_rp_GetNVM_IlluminationElement_Get_BsConst_Audio_Element: operation=rp_GetNVM_IlluminationElement.Get_BsConst_Audio_Element
          OA_rp_GetNVM_IlluminationElement_Get_BsConst_Warning_Element: operation=rp_GetNVM_IlluminationElement.Get_BsConst_Warning_Element
          OA_rp_GetNVM_IlluminationElement_Get_BsConst_RealTimeClock_Element: operation=rp_GetNVM_IlluminationElement.Get_BsConst_RealTimeClock_Element
          OA_rp_GetNVM_IlluminationElement_Get_BsConst_Communication_Element: operation=rp_GetNVM_IlluminationElement.Get_BsConst_Communication_Element
          OA_rp_GetNVM_IlluminationElement_Get_BsConst_Power_Element: operation=rp_GetNVM_IlluminationElement.Get_BsConst_Power_Element
          OA_rp_GetNVM_IlluminationElement_Get_BsConst_ServiceReminder_Element: operation=rp_GetNVM_IlluminationElement.Get_BsConst_ServiceReminder_Element
          OA_rp_GetNVM_IlluminationElement_Get_BsConst_EngOffTimer_Element: operation=rp_GetNVM_IlluminationElement.Get_BsConst_EngOffTimer_Element
          OA_rp_GetNVM_IlluminationElement_Get_BsCys_Certicificate_Element: operation=rp_GetNVM_IlluminationElement.Get_BsCys_Certicificate_Element
          OA_rp_GetNVM_IlluminationElement_Get_RefCys_Certicificate_Element: operation=rp_GetNVM_IlluminationElement.Get_RefCys_Certicificate_Element
          OA_rp_GetNVM_IlluminationElement_Get_RefCys_Certicificate1_Element: operation=rp_GetNVM_IlluminationElement.Get_RefCys_Certicificate1_Element
          OA_rp_GetNVM_IlluminationElement_Get_BsRt_Odometer_Element: operation=rp_GetNVM_IlluminationElement.Get_BsRt_Odometer_Element
          OA_rp_GetNVM_IlluminationElement_Get_BsRt_SpeedoGauge_Element: operation=rp_GetNVM_IlluminationElement.Get_BsRt_SpeedoGauge_Element
          OA_rp_GetNVM_IlluminationElement_Get_BsRt_TachoGauge_Element: operation=rp_GetNVM_IlluminationElement.Get_BsRt_TachoGauge_Element
          OA_rp_GetNVM_IlluminationElement_Get_BsRt_FuelGauge_Element: operation=rp_GetNVM_IlluminationElement.Get_BsRt_FuelGauge_Element
          OA_rp_GetNVM_IlluminationElement_Get_BsRt_TempGauge_Element: operation=rp_GetNVM_IlluminationElement.Get_BsRt_TempGauge_Element
          OA_rp_GetNVM_IlluminationElement_Get_BsRt_PowerGauge_Element: operation=rp_GetNVM_IlluminationElement.Get_BsRt_PowerGauge_Element
          OA_rp_GetNVM_IlluminationElement_Get_BsRt_OilGauge_Element: operation=rp_GetNVM_IlluminationElement.Get_BsRt_OilGauge_Element
          OA_rp_GetNVM_IlluminationElement_Get_BsRt_TripComputer_Element: operation=rp_GetNVM_IlluminationElement.Get_BsRt_TripComputer_Element
          OA_rp_GetNVM_IlluminationElement_Get_BsRt_Warning_Element: operation=rp_GetNVM_IlluminationElement.Get_BsRt_Warning_Element
          OA_rp_GetNVM_IlluminationElement_Get_BsRt_RealTimeClock_Element: operation=rp_GetNVM_IlluminationElement.Get_BsRt_RealTimeClock_Element
          OA_rp_GetNVM_IlluminationElement_Get_BsRt_Personalization_Element: operation=rp_GetNVM_IlluminationElement.Get_BsRt_Personalization_Element
          OA_rp_GetNVM_IlluminationElement_Get_BsRt_Illumination_Element: operation=rp_GetNVM_IlluminationElement.Get_BsRt_Illumination_Element
          OA_rp_GetNVM_IlluminationElement_Get_BsRt_CusDlt_Element: operation=rp_GetNVM_IlluminationElement.Get_BsRt_CusDlt_Element
          OA_rp_GetNVM_IlluminationElement_Get_BsReten_Odometer_Element: operation=rp_GetNVM_IlluminationElement.Get_BsReten_Odometer_Element
          OA_rp_GetNVM_IlluminationElement_Get_BsReten_Gauges_Element: operation=rp_GetNVM_IlluminationElement.Get_BsReten_Gauges_Element
          OA_rp_GetNVM_IlluminationElement_Get_BsReten_Tripcomputer_Element: operation=rp_GetNVM_IlluminationElement.Get_BsReten_Tripcomputer_Element
          OA_rp_GetNVM_IlluminationElement_Get_BsReten_Illumination_Element: operation=rp_GetNVM_IlluminationElement.Get_BsReten_Illumination_Element
          OA_rp_GetNVM_IlluminationElement_Get_BsReten_Audio_Element: operation=rp_GetNVM_IlluminationElement.Get_BsReten_Audio_Element
          OA_rp_GetNVM_IlluminationElement_Get_BsReten_Warning_Element: operation=rp_GetNVM_IlluminationElement.Get_BsReten_Warning_Element
          OA_rp_GetNVM_IlluminationElement_Get_BsReten_RealTimeClock_Element: operation=rp_GetNVM_IlluminationElement.Get_BsReten_RealTimeClock_Element
          OA_rp_GetNVM_IlluminationElement_Get_BsReten_Communication_Element: operation=rp_GetNVM_IlluminationElement.Get_BsReten_Communication_Element
          OA_rp_GetNVM_IlluminationElement_Get_BsReten_Personalization_Element: operation=rp_GetNVM_IlluminationElement.Get_BsReten_Personalization_Element
          OA_rp_GetNVM_IlluminationElement_Get_BsReten_Power_Element: operation=rp_GetNVM_IlluminationElement.Get_BsReten_Power_Element
          OA_rp_GetNVM_IlluminationElement_Get_BsReten_Display_Element: operation=rp_GetNVM_IlluminationElement.Get_BsReten_Display_Element
          OA_rp_GetNVM_IlluminationElement_Get_BsDiag_ErrorRecord_Element: operation=rp_GetNVM_IlluminationElement.Get_BsDiag_ErrorRecord_Element
          OA_rp_GetNVM_IlluminationElement_Get_BsDiag_Dtc_Element: operation=rp_GetNVM_IlluminationElement.Get_BsDiag_Dtc_Element
          OA_rp_PwmSetDuty_PwmSetDuty: operation=rp_PwmSetDuty.PwmSetDuty
          OA_rp_PwmSetDuty_PwmSetDutyAndPeriod: operation=rp_PwmSetDuty.PwmSetDutyAndPeriod
          OA_rp_PwmSetDuty_PwmSetIdeal: operation=rp_PwmSetDuty.PwmSetIdeal
          OA_rp_SetNVM_IlluminationElement_Set_BsShare_SwUpdReflash_Element: operation=rp_SetNVM_IlluminationElement.Set_BsShare_SwUpdReflash_Element
          OA_rp_SetNVM_IlluminationElement_Set_BsShare_SwUpdFotaMode_Element: operation=rp_SetNVM_IlluminationElement.Set_BsShare_SwUpdFotaMode_Element
          OA_rp_SetNVM_IlluminationElement_Set_BsShare_SwUpdFotaFinPrint_Element: operation=rp_SetNVM_IlluminationElement.Set_BsShare_SwUpdFotaFinPrint_Element
          OA_rp_SetNVM_IlluminationElement_Set_BsShare_SwUpdFotaStatus_Element: operation=rp_SetNVM_IlluminationElement.Set_BsShare_SwUpdFotaStatus_Element
          OA_rp_SetNVM_IlluminationElement_Set_BsShare_SwUpdFotadecrypt_Element: operation=rp_SetNVM_IlluminationElement.Set_BsShare_SwUpdFotadecrypt_Element
          OA_rp_SetNVM_IlluminationElement_Set_BsShare_EcuPartNumber_Element: operation=rp_SetNVM_IlluminationElement.Set_BsShare_EcuPartNumber_Element
          OA_rp_SetNVM_IlluminationElement_Set_BsShare_VisteonPartNumber: operation=rp_SetNVM_IlluminationElement.Set_BsShare_VisteonPartNumber
          OA_rp_SetNVM_IlluminationElement_Set_BsShare_VisteonPCBPartNumber: operation=rp_SetNVM_IlluminationElement.Set_BsShare_VisteonPCBPartNumber
          OA_rp_SetNVM_IlluminationElement_Set_BsShare_ProductSerialNumber: operation=rp_SetNVM_IlluminationElement.Set_BsShare_ProductSerialNumber
          OA_rp_SetNVM_IlluminationElement_Set_BsShare_PCBSerialNumber: operation=rp_SetNVM_IlluminationElement.Set_BsShare_PCBSerialNumber
          OA_rp_SetNVM_IlluminationElement_Set_BsShare_SMTManufacturingDate: operation=rp_SetNVM_IlluminationElement.Set_BsShare_SMTManufacturingDate
          OA_rp_SetNVM_IlluminationElement_Set_BsShare_AssemblyManufacturingDate: operation=rp_SetNVM_IlluminationElement.Set_BsShare_AssemblyManufacturingDate
          OA_rp_SetNVM_IlluminationElement_Set_BsShare_SMTPlantNumber: operation=rp_SetNVM_IlluminationElement.Set_BsShare_SMTPlantNumber
          OA_rp_SetNVM_IlluminationElement_Set_BsShare_AssemblyPlantNumber: operation=rp_SetNVM_IlluminationElement.Set_BsShare_AssemblyPlantNumber
          OA_rp_SetNVM_IlluminationElement_Set_BsShare_HWModification: operation=rp_SetNVM_IlluminationElement.Set_BsShare_HWModification
          OA_rp_SetNVM_IlluminationElement_Set_BsShare_VisMeet_Element: operation=rp_SetNVM_IlluminationElement.Set_BsShare_VisMeet_Element
          OA_rp_SetNVM_IlluminationElement_Set_BsShare_VisMeet_EOLEntry_Element: operation=rp_SetNVM_IlluminationElement.Set_BsShare_VisMeet_EOLEntry_Element
          OA_rp_SetNVM_IlluminationElement_Set_BsShare_VehicleConfig_Element: operation=rp_SetNVM_IlluminationElement.Set_BsShare_VehicleConfig_Element
          OA_rp_SetNVM_IlluminationElement_Set_BsConst_SpeedoGauge_Element: operation=rp_SetNVM_IlluminationElement.Set_BsConst_SpeedoGauge_Element
          OA_rp_SetNVM_IlluminationElement_Set_BsConst_TachoGauge_Element: operation=rp_SetNVM_IlluminationElement.Set_BsConst_TachoGauge_Element
          OA_rp_SetNVM_IlluminationElement_Set_BsConst_FuelGauge_Element: operation=rp_SetNVM_IlluminationElement.Set_BsConst_FuelGauge_Element
          OA_rp_SetNVM_IlluminationElement_Set_BsConst_TempGauge_Element: operation=rp_SetNVM_IlluminationElement.Set_BsConst_TempGauge_Element
          OA_rp_SetNVM_IlluminationElement_Set_BsConst_PowerGauge_Element: operation=rp_SetNVM_IlluminationElement.Set_BsConst_PowerGauge_Element
          OA_rp_SetNVM_IlluminationElement_Set_BsConst_OilGauge_Element: operation=rp_SetNVM_IlluminationElement.Set_BsConst_OilGauge_Element
          OA_rp_SetNVM_IlluminationElement_Set_BsConst_TripComputer_Element: operation=rp_SetNVM_IlluminationElement.Set_BsConst_TripComputer_Element
          OA_rp_SetNVM_IlluminationElement_Set_BsConst_Compensation_Line_Slope_m: operation=rp_SetNVM_IlluminationElement.Set_BsConst_Compensation_Line_Slope_m
          OA_rp_SetNVM_IlluminationElement_Set_BsConst_Compensation_Line_Shift_b: operation=rp_SetNVM_IlluminationElement.Set_BsConst_Compensation_Line_Shift_b
          OA_rp_SetNVM_IlluminationElement_Set_BsConst_Lookup_Curve_HotSpot_Coef_X: operation=rp_SetNVM_IlluminationElement.Set_BsConst_Lookup_Curve_HotSpot_Coef_X
          OA_rp_SetNVM_IlluminationElement_Set_BsConst_Lookup_Curve_HotSpot_Coef_Y: operation=rp_SetNVM_IlluminationElement.Set_BsConst_Lookup_Curve_HotSpot_Coef_Y
          OA_rp_SetNVM_IlluminationElement_Set_BsConst_Temp_Threshold_Hysteresis_Derating: operation=rp_SetNVM_IlluminationElement.Set_BsConst_Temp_Threshold_Hysteresis_Derating
          OA_rp_SetNVM_IlluminationElement_Set_BsConst_Derating_Backlight_Disable: operation=rp_SetNVM_IlluminationElement.Set_BsConst_Derating_Backlight_Disable
          OA_rp_SetNVM_IlluminationElement_Set_BsConst_Temperature_Sensor_Conv: operation=rp_SetNVM_IlluminationElement.Set_BsConst_Temperature_Sensor_Conv
          OA_rp_SetNVM_IlluminationElement_Set_BsConst_PCB_Temperature_Sensor_Conv: operation=rp_SetNVM_IlluminationElement.Set_BsConst_PCB_Temperature_Sensor_Conv
          OA_rp_SetNVM_IlluminationElement_Set_BsConst_Display_Illum_Max_Level: operation=rp_SetNVM_IlluminationElement.Set_BsConst_Display_Illum_Max_Level
          OA_rp_SetNVM_IlluminationElement_Set_BsConst_PWM_boost_bypass_duty: operation=rp_SetNVM_IlluminationElement.Set_BsConst_PWM_boost_bypass_duty
          OA_rp_SetNVM_IlluminationElement_Set_BsConst_BsConst_Illumination_ReservedByte: operation=rp_SetNVM_IlluminationElement.Set_BsConst_BsConst_Illumination_ReservedByte
          OA_rp_SetNVM_IlluminationElement_Set_BsConst_Compensation_Line_Slope_m_SafeCopy1: operation=rp_SetNVM_IlluminationElement.Set_BsConst_Compensation_Line_Slope_m_SafeCopy1
          OA_rp_SetNVM_IlluminationElement_Set_BsConst_Compensation_Line_Shift_b_SafeCopy1: operation=rp_SetNVM_IlluminationElement.Set_BsConst_Compensation_Line_Shift_b_SafeCopy1
          OA_rp_SetNVM_IlluminationElement_Set_BsConst_Lookup_Curve_HotSpot_Coef_X_SafeCopy1: operation=rp_SetNVM_IlluminationElement.Set_BsConst_Lookup_Curve_HotSpot_Coef_X_SafeCopy1
          OA_rp_SetNVM_IlluminationElement_Set_BsConst_Lookup_Curve_HotSpot_Coef_Y_SafeCopy1: operation=rp_SetNVM_IlluminationElement.Set_BsConst_Lookup_Curve_HotSpot_Coef_Y_SafeCopy1
          OA_rp_SetNVM_IlluminationElement_Set_BsConst_Temp_Threshold_Hysteresis_Derating_SafeCopy1: operation=rp_SetNVM_IlluminationElement.Set_BsConst_Temp_Threshold_Hysteresis_Derating_SafeCopy1
          OA_rp_SetNVM_IlluminationElement_Set_BsConst_Derating_Backlight_Disable_SafeCopy1: operation=rp_SetNVM_IlluminationElement.Set_BsConst_Derating_Backlight_Disable_SafeCopy1
          OA_rp_SetNVM_IlluminationElement_Set_BsConst_Temperature_Sensor_Conv_SafeCopy1: operation=rp_SetNVM_IlluminationElement.Set_BsConst_Temperature_Sensor_Conv_SafeCopy1
          OA_rp_SetNVM_IlluminationElement_Set_BsConst_PCB_Temperature_Sensor_Conv_SafeCopy1: operation=rp_SetNVM_IlluminationElement.Set_BsConst_PCB_Temperature_Sensor_Conv_SafeCopy1
          OA_rp_SetNVM_IlluminationElement_Set_BsConst_Display_Illum_Max_Level_SafeCopy1: operation=rp_SetNVM_IlluminationElement.Set_BsConst_Display_Illum_Max_Level_SafeCopy1
          OA_rp_SetNVM_IlluminationElement_Set_BsConst_PWM_boost_bypass_duty_SafeCopy1: operation=rp_SetNVM_IlluminationElement.Set_BsConst_PWM_boost_bypass_duty_SafeCopy1
          OA_rp_SetNVM_IlluminationElement_Set_BsConst_BsConst_Illumination_ReservedByte_SafeCopy1: operation=rp_SetNVM_IlluminationElement.Set_BsConst_BsConst_Illumination_ReservedByte_SafeCopy1
          OA_rp_SetNVM_IlluminationElement_Set_BsConst_Compensation_Line_Slope_m_SafeCopy2: operation=rp_SetNVM_IlluminationElement.Set_BsConst_Compensation_Line_Slope_m_SafeCopy2
          OA_rp_SetNVM_IlluminationElement_Set_BsConst_Compensation_Line_Shift_b_SafeCopy2: operation=rp_SetNVM_IlluminationElement.Set_BsConst_Compensation_Line_Shift_b_SafeCopy2
          OA_rp_SetNVM_IlluminationElement_Set_BsConst_Lookup_Curve_HotSpot_Coef_X_SafeCopy2: operation=rp_SetNVM_IlluminationElement.Set_BsConst_Lookup_Curve_HotSpot_Coef_X_SafeCopy2
          OA_rp_SetNVM_IlluminationElement_Set_BsConst_Lookup_Curve_HotSpot_Coef_Y_SafeCopy2: operation=rp_SetNVM_IlluminationElement.Set_BsConst_Lookup_Curve_HotSpot_Coef_Y_SafeCopy2
          OA_rp_SetNVM_IlluminationElement_Set_BsConst_Temp_Threshold_Hysteresis_Derating_SafeCopy2: operation=rp_SetNVM_IlluminationElement.Set_BsConst_Temp_Threshold_Hysteresis_Derating_SafeCopy2
          OA_rp_SetNVM_IlluminationElement_Set_BsConst_Derating_Backlight_Disable_SafeCopy2: operation=rp_SetNVM_IlluminationElement.Set_BsConst_Derating_Backlight_Disable_SafeCopy2
          OA_rp_SetNVM_IlluminationElement_Set_BsConst_Temperature_Sensor_Conv_SafeCopy2: operation=rp_SetNVM_IlluminationElement.Set_BsConst_Temperature_Sensor_Conv_SafeCopy2
          OA_rp_SetNVM_IlluminationElement_Set_BsConst_PCB_Temperature_Sensor_Conv_SafeCopy2: operation=rp_SetNVM_IlluminationElement.Set_BsConst_PCB_Temperature_Sensor_Conv_SafeCopy2
          OA_rp_SetNVM_IlluminationElement_Set_BsConst_Display_Illum_Max_Level_SafeCopy2: operation=rp_SetNVM_IlluminationElement.Set_BsConst_Display_Illum_Max_Level_SafeCopy2
          OA_rp_SetNVM_IlluminationElement_Set_BsConst_PWM_boost_bypass_duty_SafeCopy2: operation=rp_SetNVM_IlluminationElement.Set_BsConst_PWM_boost_bypass_duty_SafeCopy2
          OA_rp_SetNVM_IlluminationElement_Set_BsConst_BsConst_Illumination_ReservedByte_SafeCopy2: operation=rp_SetNVM_IlluminationElement.Set_BsConst_BsConst_Illumination_ReservedByte_SafeCopy2
          OA_rp_SetNVM_IlluminationElement_Set_BsConst_Audio_Element: operation=rp_SetNVM_IlluminationElement.Set_BsConst_Audio_Element
          OA_rp_SetNVM_IlluminationElement_Set_BsConst_Warning_Element: operation=rp_SetNVM_IlluminationElement.Set_BsConst_Warning_Element
          OA_rp_SetNVM_IlluminationElement_Set_BsConst_RealTimeClock_Element: operation=rp_SetNVM_IlluminationElement.Set_BsConst_RealTimeClock_Element
          OA_rp_SetNVM_IlluminationElement_Set_BsConst_Communication_Element: operation=rp_SetNVM_IlluminationElement.Set_BsConst_Communication_Element
          OA_rp_SetNVM_IlluminationElement_Set_BsConst_Power_Element: operation=rp_SetNVM_IlluminationElement.Set_BsConst_Power_Element
          OA_rp_SetNVM_IlluminationElement_Set_BsConst_ServiceReminder_Element: operation=rp_SetNVM_IlluminationElement.Set_BsConst_ServiceReminder_Element
          OA_rp_SetNVM_IlluminationElement_Set_BsConst_EngOffTimer_Element: operation=rp_SetNVM_IlluminationElement.Set_BsConst_EngOffTimer_Element
          OA_rp_SetNVM_IlluminationElement_Set_BsCys_Certicificate_Element: operation=rp_SetNVM_IlluminationElement.Set_BsCys_Certicificate_Element
          OA_rp_SetNVM_IlluminationElement_Set_RefCys_Certicificate_Element: operation=rp_SetNVM_IlluminationElement.Set_RefCys_Certicificate_Element
          OA_rp_SetNVM_IlluminationElement_Set_RefCys_Certicificate1_Element: operation=rp_SetNVM_IlluminationElement.Set_RefCys_Certicificate1_Element
          OA_rp_SetNVM_IlluminationElement_Set_BsRt_Odometer_Element: operation=rp_SetNVM_IlluminationElement.Set_BsRt_Odometer_Element
          OA_rp_SetNVM_IlluminationElement_Set_BsRt_SpeedoGauge_Element: operation=rp_SetNVM_IlluminationElement.Set_BsRt_SpeedoGauge_Element
          OA_rp_SetNVM_IlluminationElement_Set_BsRt_TachoGauge_Element: operation=rp_SetNVM_IlluminationElement.Set_BsRt_TachoGauge_Element
          OA_rp_SetNVM_IlluminationElement_Set_BsRt_FuelGauge_Element: operation=rp_SetNVM_IlluminationElement.Set_BsRt_FuelGauge_Element
          OA_rp_SetNVM_IlluminationElement_Set_BsRt_TempGauge_Element: operation=rp_SetNVM_IlluminationElement.Set_BsRt_TempGauge_Element
          OA_rp_SetNVM_IlluminationElement_Set_BsRt_PowerGauge_Element: operation=rp_SetNVM_IlluminationElement.Set_BsRt_PowerGauge_Element
          OA_rp_SetNVM_IlluminationElement_Set_BsRt_OilGauge_Element: operation=rp_SetNVM_IlluminationElement.Set_BsRt_OilGauge_Element
          OA_rp_SetNVM_IlluminationElement_Set_BsRt_TripComputer_Element: operation=rp_SetNVM_IlluminationElement.Set_BsRt_TripComputer_Element
          OA_rp_SetNVM_IlluminationElement_Set_BsRt_Warning_Element: operation=rp_SetNVM_IlluminationElement.Set_BsRt_Warning_Element
          OA_rp_SetNVM_IlluminationElement_Set_BsRt_RealTimeClock_Element: operation=rp_SetNVM_IlluminationElement.Set_BsRt_RealTimeClock_Element
          OA_rp_SetNVM_IlluminationElement_Set_BsRt_Personalization_Element: operation=rp_SetNVM_IlluminationElement.Set_BsRt_Personalization_Element
          OA_rp_SetNVM_IlluminationElement_Set_BsRt_Illumination_Element: operation=rp_SetNVM_IlluminationElement.Set_BsRt_Illumination_Element
          OA_rp_SetNVM_IlluminationElement_Set_BsRt_CusDlt_Element: operation=rp_SetNVM_IlluminationElement.Set_BsRt_CusDlt_Element
          OA_rp_SetNVM_IlluminationElement_Set_BsReten_Odometer_Element: operation=rp_SetNVM_IlluminationElement.Set_BsReten_Odometer_Element
          OA_rp_SetNVM_IlluminationElement_Set_BsReten_Gauges_Element: operation=rp_SetNVM_IlluminationElement.Set_BsReten_Gauges_Element
          OA_rp_SetNVM_IlluminationElement_Set_BsReten_Tripcomputer_Element: operation=rp_SetNVM_IlluminationElement.Set_BsReten_Tripcomputer_Element
          OA_rp_SetNVM_IlluminationElement_Set_BsReten_Illumination_Element: operation=rp_SetNVM_IlluminationElement.Set_BsReten_Illumination_Element
          OA_rp_SetNVM_IlluminationElement_Set_BsReten_Audio_Element: operation=rp_SetNVM_IlluminationElement.Set_BsReten_Audio_Element
          OA_rp_SetNVM_IlluminationElement_Set_BsReten_Warning_Element: operation=rp_SetNVM_IlluminationElement.Set_BsReten_Warning_Element
          OA_rp_SetNVM_IlluminationElement_Set_BsReten_RealTimeClock_Element: operation=rp_SetNVM_IlluminationElement.Set_BsReten_RealTimeClock_Element
          OA_rp_SetNVM_IlluminationElement_Set_BsReten_Communication_Element: operation=rp_SetNVM_IlluminationElement.Set_BsReten_Communication_Element
          OA_rp_SetNVM_IlluminationElement_Set_BsReten_Personalization_Element: operation=rp_SetNVM_IlluminationElement.Set_BsReten_Personalization_Element
          OA_rp_SetNVM_IlluminationElement_Set_BsReten_Power_Element: operation=rp_SetNVM_IlluminationElement.Set_BsReten_Power_Element
          OA_rp_SetNVM_IlluminationElement_Set_BsReten_Display_Element: operation=rp_SetNVM_IlluminationElement.Set_BsReten_Display_Element
          OA_rp_SetNVM_IlluminationElement_Set_BsDiag_ErrorRecord_Element: operation=rp_SetNVM_IlluminationElement.Set_BsDiag_ErrorRecord_Element
          OA_rp_SetNVM_IlluminationElement_Set_BsDiag_Dtc_Element: operation=rp_SetNVM_IlluminationElement.Set_BsDiag_Dtc_Element
          OA_rp_TmExt_Timer_IsElapsed_Timer_IsElapsed: operation=rp_TmExt_Timer_IsElapsed.Timer_IsElapsed
          OA_rp_TmExt_Timer_IsStarted_Timer_IsStarted: operation=rp_TmExt_Timer_IsStarted.Timer_IsStarted
          OA_rp_TmExt_Timer_Start_Timer_Start: operation=rp_TmExt_Timer_Start.Timer_Start
          OA_rp_TmExt_Timer_Stop_Timer_Stop: operation=rp_TmExt_Timer_Stop.Timer_Stop
  10 x constant specification:
    View_IlluminationIlluminationDataDataValue0: value-spec={short-label=View_IlluminationIlluminationDataDataValue0, fields=[View_IlluminationIlluminationDataDataValue_0:0, View_IlluminationIlluminationDataDataValue_1:0, View_IlluminationIlluminationDataDataValue_2:0, View_IlluminationIlluminationDataDataValue_3:0]}
    View_IlluminationIllumStatusValue0: value-spec=View_IlluminationIllumStatusValue0:0
    View_IlluminationIgnitionSubstateValue0: value-spec=View_IlluminationIgnitionSubstateValue0:0
    View_IlluminationWSSCurrentVehicleStateValue0: value-spec=View_IlluminationWSSCurrentVehicleStateValue0:0
    View_IlluminationEcoRunSystem_FlagValue0: value-spec=View_IlluminationEcoRunSystem_FlagValue0:0
    View_IlluminationIllumCtrl_Op_DataValue0: value-spec={short-label=View_IlluminationIllumCtrl_Op_DataValue0, fields=[View_IlluminationIllumCtrl_Op_DataValue_0:0, View_IlluminationIllumCtrl_Op_DataValue_1:0, View_IlluminationIllumCtrl_Op_DataValue_2:0, View_IlluminationIllumCtrl_Op_DataValue_3:0, View_IlluminationIllumCtrl_Op_DataValue_4:0, View_IlluminationIllumCtrl_Op_DataValue_5:0, View_IlluminationIllumCtrl_Op_DataValue_6:0, View_IlluminationIllumCtrl_Op_DataValue_7:0]}
    View_IlluminationRheostatDayStepValue0: value-spec=View_IlluminationRheostatDayStepValue0:0
    View_IlluminationRheostatNightStepValue0: value-spec=View_IlluminationRheostatNightStepValue0:0
    View_IlluminationRheoUpdateValValue0: value-spec=View_IlluminationRheoUpdateValValue0:0
    View_IlluminationTFTDisplayOnValue0: value-spec=View_IlluminationTFTDisplayOnValue0:0
  swc implementation IMPL_View_Illumination: programming-language=C, behavior=IB_View_Illumination
    code-descriptors:
      code CodeDescriptor
